VERSION "HNNBNNNYNNNNNNNNNNNNNNNNNNNNNNNNNNNNNNNNNN/4/%%%/4/'%**4NNN///"

NS_ :

BS_:

BU_: BAP_Tester BedienDisp_vo BedienSG_hi CGS DDA Gateway Gateway_PAG GurtMikrofon OTA_FC ZR_High ZR_LIMU ZR_MIB_TOP_ab_Gen3 ZR_Standard

BO_ 1178 Mem_FS_01: 8 Gateway
 SG_ FS_Fond_Bed_enable : 12|1@1+ (1.0,0.0) [0.0|1] ""  ZR_High
 SG_ FS_Lehne_nicht_verriegelt : 13|1@1+ (1.0,0.0) [0.0|1] ""  ZR_High
 SG_ FS_Spezialposition_anfahren : 14|1@1+ (1.0,0.0) [0.0|1] ""  ZR_High
 SG_ FS_Gurtbringer_Sperre : 15|1@1+ (1.0,0.0) [0.0|1] ""  ZR_High
 SG_ FS_BFS_Sitzsym_Anfahrt : 16|1@1+ (1.0,0.0) [0.0|1] ""  ZR_High
 SG_ FS_Sitzfahrt_aktiv : 17|1@1+ (1.0,0.0) [0.0|1] ""  ZR_High
 SG_ FS_SLV_aktiv : 18|1@1+ (1.0,0.0) [0.0|1] ""  ZR_High
 SG_ FS_SHV_aktiv : 19|1@1+ (1.0,0.0) [0.0|1] ""  ZR_High
 SG_ FS_LNV_aktiv : 20|1@1+ (1.0,0.0) [0.0|1] ""  ZR_High
 SG_ FS_SNV_aktiv : 21|1@1+ (1.0,0.0) [0.0|1] ""  ZR_High
 SG_ FS_KSV_aktiv : 22|1@1+ (1.0,0.0) [0.0|1] ""  ZR_High
 SG_ FS_LKV_aktiv : 23|1@1+ (1.0,0.0) [0.0|1] ""  ZR_High
 SG_ FS_STV_aktiv : 24|1@1+ (1.0,0.0) [0.0|1] ""  ZR_High
 SG_ FS_LHV_aktiv : 25|1@1+ (1.0,0.0) [0.0|1] ""  ZR_High
 SG_ FS_LWV_aktiv : 26|1@1+ (1.0,0.0) [0.0|1] ""  ZR_High
 SG_ FS_GHV_aktiv : 27|1@1+ (1.0,0.0) [0.0|1] ""  ZR_High
 SG_ FS_BFS_KSS_Anfahrt : 28|1@1+ (1.0,0.0) [0.0|1] ""  ZR_High
 SG_ FS_MMB_lokal_Stop : 29|1@1+ (1.0,0.0) [0.0|1] ""  ZR_High
 SG_ FS_NFA_einfahren : 30|1@1+ (1.0,0.0) [0.0|1] ""  Vector__XXX
 SG_ FS_Kollisionsbereich_Windschott : 31|1@1+ (1.0,0.0) [0.0|1] ""  Vector__XXX
 SG_ FS_MMB_storage : 32|4@1+ (1.0,0.0) [0.0|15] ""  ZR_High
 SG_ FS_MMB_tipp : 36|1@1+ (1.0,0.0) [0.0|1] ""  ZR_High
 SG_ FS_MMB_tast : 37|1@1+ (1.0,0.0) [0.0|1] ""  ZR_High
 SG_ FS_MMB_store_LED_on : 38|1@1+ (1.0,0.0) [0.0|1] ""  ZR_High
 SG_ FS_MMB_storage_beep : 39|1@1+ (1.0,0.0) [0.0|1] ""  Vector__XXX
 SG_ FS_MMB_store : 40|1@1+ (1.0,0.0) [0.0|1] ""  ZR_High
 SG_ FS_MMB_glob_stop : 41|1@1+ (1.0,0.0) [0.0|1] ""  ZR_High
 SG_ FS_EE_Fond_FS_enable : 42|1@1+ (1.0,0.0) [0.0|1] ""  ZR_High
 SG_ FS_EE_Fond_BFS_enable : 43|1@1+ (1.0,0.0) [0.0|1] ""  ZR_High
 SG_ FS_BFS_Fond_Verst_enable : 44|1@1+ (1.0,0.0) [0.0|1] ""  ZR_High
 SG_ FS_EE_BFS_enable : 45|1@1+ (1.0,0.0) [0.0|1] ""  ZR_High
 SG_ FS_Kollisionsgefahr_Windschott : 46|1@1+ (1.0,0.0) [0.0|1] ""  Vector__XXX

BO_ 954 Mem_FS_02: 8 Gateway
 SG_ Mem_FS_Lordose_hoch : 12|1@1+ (1.0,0.0) [0.0|1] ""  ZR_High
 SG_ Mem_FS_Lordose_runter : 13|1@1+ (1.0,0.0) [0.0|1] ""  ZR_High
 SG_ Mem_FS_Lordose_vor : 14|1@1+ (1.0,0.0) [0.0|1] ""  ZR_High
 SG_ Mem_FS_Lordose_zurueck : 15|1@1+ (1.0,0.0) [0.0|1] ""  ZR_High
 SG_ Mem_FS_Massage_Geschw : 16|3@1+ (1.0,0.0) [0.0|7] ""  ZR_High
 SG_ Mem_FS_Massage_Intensitaet : 19|3@1+ (1.0,0.0) [0.0|7] ""  ZR_High
 SG_ Mem_FS_SWangenLehne_beluef : 22|1@1+ (1.0,0.0) [0.0|1] ""  ZR_High
 SG_ Mem_FS_SWangenLehne_entlue : 23|1@1+ (1.0,0.0) [0.0|1] ""  ZR_High
 SG_ Mem_FS_Massage_Programm : 24|3@1+ (1.0,0.0) [0.0|7] ""  Vector__XXX
 SG_ Mem_FS_SWangenSitz_beluef : 27|1@1+ (1.0,0.0) [0.0|1] ""  ZR_High
 SG_ Mem_FS_SWangenSitz_entlue : 28|1@1+ (1.0,0.0) [0.0|1] ""  ZR_High
 SG_ FS_BFS_aufraeumen : 29|1@1+ (1.0,0.0) [0.0|1] ""  ZR_High
 SG_ FS_BFSFo_aufraeumen : 30|1@1+ (1.0,0.0) [0.0|1] ""  ZR_High
 SG_ FS_FSFo_aufraeumen : 31|1@1+ (1.0,0.0) [0.0|1] ""  ZR_High
 SG_ FS_Remote_Multif_Taster_hoch : 32|1@1+ (1.0,0.0) [0.0|1] ""  ZR_High
 SG_ FS_Remote_Multif_Taster_tief : 33|1@1+ (1.0,0.0) [0.0|1] ""  ZR_High
 SG_ FS_Remote_Multif_Taster_vor : 34|1@1+ (1.0,0.0) [0.0|1] ""  ZR_High
 SG_ FS_Remote_Multif_Taster_zurueck : 35|1@1+ (1.0,0.0) [0.0|1] ""  ZR_High
 SG_ FS_Remote_Programmwippe_hoch : 36|1@1+ (1.0,0.0) [0.0|1] ""  ZR_High
 SG_ FS_Remote_Programmwippe_tief : 37|1@1+ (1.0,0.0) [0.0|1] ""  ZR_High
 SG_ FS_Remote_SHV_Taste_hoch : 38|1@1+ (1.0,0.0) [0.0|1] ""  ZR_High
 SG_ FS_Remote_SHV_Taste_tief : 39|1@1+ (1.0,0.0) [0.0|1] ""  ZR_High
 SG_ FS_Remote_SLV_Taste_vor : 40|1@1+ (1.0,0.0) [0.0|1] ""  ZR_High
 SG_ FS_Remote_SLV_Taste_zurueck : 41|1@1+ (1.0,0.0) [0.0|1] ""  ZR_High
 SG_ FS_Remote_SNV_Taste_hoch : 42|1@1+ (1.0,0.0) [0.0|1] ""  ZR_High
 SG_ FS_Remote_SNV_Taste_tief : 43|1@1+ (1.0,0.0) [0.0|1] ""  ZR_High
 SG_ FS_Remote_KSV_Taste_hoch : 44|1@1+ (1.0,0.0) [0.0|1] ""  ZR_High
 SG_ FS_Remote_KSV_Taste_tief : 45|1@1+ (1.0,0.0) [0.0|1] ""  ZR_High
 SG_ FS_Remote_LNV_Taste_vor : 46|1@1+ (1.0,0.0) [0.0|1] ""  ZR_High
 SG_ FS_Remote_LNV_Taste_zurueck : 47|1@1+ (1.0,0.0) [0.0|1] ""  ZR_High
 SG_ FS_Remote_Massage_Taste : 48|1@1+ (1.0,0.0) [0.0|1] ""  ZR_High
 SG_ FS_RemoteTarget : 49|2@1+ (1.0,0.0) [0.0|3] ""  ZR_High
 SG_ FS_Remote_KSV_Taste_vor : 51|1@1+ (1.0,0.0) [0.0|1] ""  ZR_High
 SG_ FS_Remote_KSV_Taste_zurueck : 52|1@1+ (1.0,0.0) [0.0|1] ""  ZR_High
 SG_ FS_Remote_STV_Taste_vor : 53|1@1+ (1.0,0.0) [0.0|1] ""  ZR_High
 SG_ FS_Remote_STV_Taste_zurueck : 54|1@1+ (1.0,0.0) [0.0|1] ""  ZR_High
 SG_ FS_Remote_SWV_Taste_eng : 55|1@1+ (1.0,0.0) [0.0|1] ""  ZR_High
 SG_ FS_Remote_SWV_Taste_breit : 56|1@1+ (1.0,0.0) [0.0|1] ""  ZR_High
 SG_ FS_Remote_LWV_Taste_eng : 57|1@1+ (1.0,0.0) [0.0|1] ""  ZR_High
 SG_ FS_Remote_LWV_Taste_breit : 58|1@1+ (1.0,0.0) [0.0|1] ""  ZR_High
 SG_ FS_Remote_LKV_Taste_vor : 59|1@1+ (1.0,0.0) [0.0|1] ""  ZR_High
 SG_ FS_Remote_LKV_Taste_zurueck : 60|1@1+ (1.0,0.0) [0.0|1] ""  ZR_High
 SG_ FS_MMB_Sys_Fahrt_aktiv : 61|1@1+ (1.0,0.0) [0.0|1] ""  ZR_High

BO_ 956 Mem_FS_Fond_01: 8 Gateway
 SG_ Mem_FSFo_Lordose_hoch : 12|1@1+ (1.0,0.0) [0.0|1] ""  ZR_High
 SG_ Mem_FSFo_Lordose_runter : 13|1@1+ (1.0,0.0) [0.0|1] ""  ZR_High
 SG_ Mem_FSFo_Lordose_vor : 14|1@1+ (1.0,0.0) [0.0|1] ""  ZR_High
 SG_ Mem_FSFo_Lordose_zurueck : 15|1@1+ (1.0,0.0) [0.0|1] ""  ZR_High
 SG_ Mem_FSFo_Massage_Geschw : 16|3@1+ (1.0,0.0) [0.0|7] ""  ZR_High
 SG_ Mem_FSFo_Massage_Intens : 19|3@1+ (1.0,0.0) [0.0|7] ""  ZR_High
 SG_ Mem_FSFo_MMB_storage : 22|2@1+ (1.0,0.0) [0.0|3] ""  ZR_High
 SG_ Mem_FSFo_Massage_Prg : 24|3@1+ (1.0,0.0) [0.0|7] ""  ZR_High
 SG_ Mem_FSFo_MMB_tast : 27|1@1+ (1.0,0.0) [0.0|1] ""  ZR_High
 SG_ Mem_FSFo_MMB_tipp : 28|1@1+ (1.0,0.0) [0.0|1] ""  ZR_High
 SG_ Mem_FSFo_MMB_glob_Stop : 29|1@1+ (1.0,0.0) [0.0|1] ""  ZR_High
 SG_ Mem_FSFo_Sitztiefe_vor : 30|1@1+ (1.0,0.0) [0.0|1] ""  ZR_High
 SG_ Mem_FSFo_Sitztiefe_zur : 31|1@1+ (1.0,0.0) [0.0|1] ""  ZR_High
 SG_ Mem_FSFo_MMB_store : 32|1@1+ (1.0,0.0) [0.0|1] ""  ZR_High
 SG_ Mem_FSFo_MMB_storage_beep : 33|1@1+ (1.0,0.0) [0.0|1] ""  ZR_High
 SG_ Mem_FSFo_MMB_store_LED_on : 34|1@1+ (1.0,0.0) [0.0|1] ""  ZR_High
 SG_ Mem_FSFo_MMB_lokal_Stop : 36|1@1+ (1.0,0.0) [0.0|1] ""  ZR_High
 SG_ Mem_FSFo_Sitzfahrt_aktiv : 37|1@1+ (1.0,0.0) [0.0|1] ""  ZR_High
 SG_ Mem_FSFo_Business_anfahren : 42|1@1+ (1.0,0.0) [0.0|1] ""  ZR_High
 SG_ Mem_FSFo_Relax_anfahren : 43|1@1+ (1.0,0.0) [0.0|1] ""  ZR_High

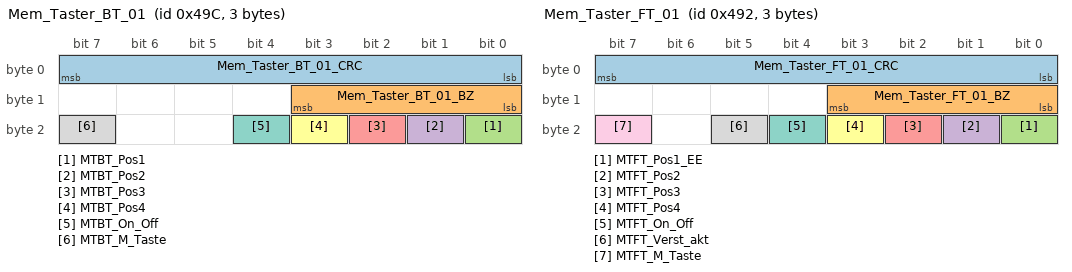
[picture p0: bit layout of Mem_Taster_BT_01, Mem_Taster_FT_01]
BO_ 1180 Mem_Taster_BT_01: 3 Gateway
 SG_ Mem_Taster_BT_01_CRC : 0|8@1+ (1,0) [0|255] ""  Vector__XXX
 SG_ Mem_Taster_BT_01_BZ : 8|4@1+ (1,0) [0|15] ""  Vector__XXX
 SG_ MTBT_Pos1 : 16|1@1+ (1.0,0.0) [0.0|1] ""  ZR_High
 SG_ MTBT_Pos2 : 17|1@1+ (1.0,0.0) [0.0|1] ""  ZR_High
 SG_ MTBT_Pos3 : 18|1@1+ (1.0,0.0) [0.0|1] ""  ZR_High
 SG_ MTBT_Pos4 : 19|1@1+ (1.0,0.0) [0.0|1] ""  ZR_High
 SG_ MTBT_On_Off : 20|1@1+ (1.0,0.0) [0.0|1] ""  ZR_High
 SG_ MTBT_M_Taste : 23|1@1+ (1.0,0.0) [0.0|1] ""  ZR_High

BO_ 1170 Mem_Taster_FT_01: 3 Gateway
 SG_ Mem_Taster_FT_01_CRC : 0|8@1+ (1,0) [0|255] ""  Vector__XXX
 SG_ Mem_Taster_FT_01_BZ : 8|4@1+ (1,0) [0|15] ""  Vector__XXX
 SG_ MTFT_Pos1_EE : 16|1@1+ (1.0,0.0) [0.0|1] ""  ZR_High
 SG_ MTFT_Pos2 : 17|1@1+ (1.0,0.0) [0.0|1] ""  ZR_High
 SG_ MTFT_Pos3 : 18|1@1+ (1.0,0.0) [0.0|1] ""  ZR_High
 SG_ MTFT_Pos4 : 19|1@1+ (1.0,0.0) [0.0|1] ""  ZR_High
 SG_ MTFT_On_Off : 20|1@1+ (1.0,0.0) [0.0|1] ""  ZR_High
 SG_ MTFT_Verst_akt : 21|1@1+ (1.0,0.0) [0.0|1] ""  ZR_High
 SG_ MTFT_M_Taste : 23|1@1+ (1.0,0.0) [0.0|1] ""  ZR_High

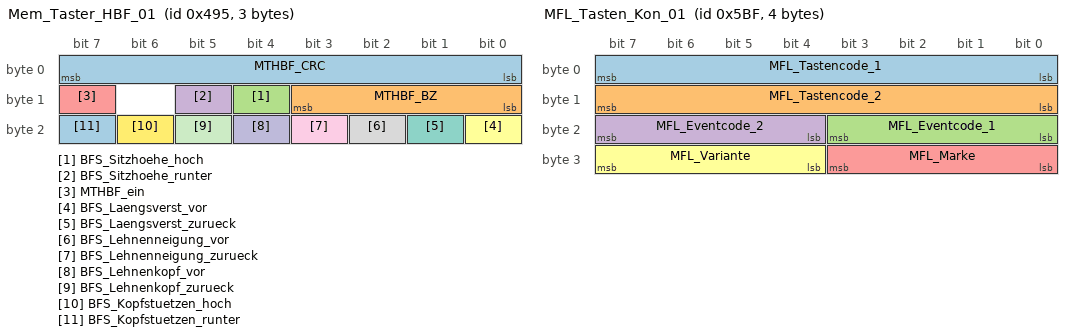
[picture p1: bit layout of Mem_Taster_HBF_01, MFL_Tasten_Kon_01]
BO_ 1173 Mem_Taster_HBF_01: 3 Gateway
 SG_ MTHBF_CRC : 0|8@1+ (1,0) [0|255] ""  Vector__XXX
 SG_ MTHBF_BZ : 8|4@1+ (1,0) [0|15] ""  Vector__XXX
 SG_ BFS_Sitzhoehe_hoch : 12|1@1+ (1.0,0.0) [0.0|1] ""  ZR_High
 SG_ BFS_Sitzhoehe_runter : 13|1@1+ (1.0,0.0) [0.0|1] ""  ZR_High
 SG_ MTHBF_ein : 15|1@1+ (1.0,0.0) [0.0|1] ""  ZR_High
 SG_ BFS_Laengsverst_vor : 16|1@1+ (1.0,0.0) [0.0|1] ""  ZR_High
 SG_ BFS_Laengsverst_zurueck : 17|1@1+ (1.0,0.0) [0.0|1] ""  ZR_High
 SG_ BFS_Lehnenneigung_vor : 18|1@1+ (1.0,0.0) [0.0|1] ""  ZR_High
 SG_ BFS_Lehnenneigung_zurueck : 19|1@1+ (1.0,0.0) [0.0|1] ""  ZR_High
 SG_ BFS_Lehnenkopf_vor : 20|1@1+ (1.0,0.0) [0.0|1] ""  ZR_High
 SG_ BFS_Lehnenkopf_zurueck : 21|1@1+ (1.0,0.0) [0.0|1] ""  ZR_High
 SG_ BFS_Kopfstuetzen_hoch : 22|1@1+ (1.0,0.0) [0.0|1] ""  ZR_High
 SG_ BFS_Kopfstuetzen_runter : 23|1@1+ (1.0,0.0) [0.0|1] ""  ZR_High

BO_ 817 MFL_01: 8 Gateway
 SG_ MFL_Zaehler : 0|4@1+ (1,0) [0|15] ""  Vector__XXX
 SG_ MFL_Toggle : 4|1@1+ (1,0) [0|1] ""  Vector__XXX
 SG_ MFL_Lokalaktiv : 5|1@1+ (1.0,0.0) [0.0|1] ""  Vector__XXX
 SG_ MFL_M_Taste : 6|1@1+ (1.0,0.0) [0.0|1] ""  ZR_High
 SG_ MFL_Paddle_Verbau : 7|1@1+ (1.0,0.0) [0.0|1] ""  ZR_High
 SG_ MFL_Tastencode_1 : 8|8@1+ (1.0,0.0) [0.0|255] ""  Vector__XXX
 SG_ MFL_Tastencode_2 : 16|8@1+ (1.0,0.0) [0.0|255] ""  Vector__XXX
 SG_ MFL_Eventcode_1 : 24|4@1+ (1.0,0.0) [0.0|15] ""  Vector__XXX
 SG_ MFL_Eventcode_2 : 28|4@1+ (1.0,0.0) [0.0|15] ""  Vector__XXX
 SG_ MFL_Marke : 32|4@1+ (1.0,0.0) [0.0|15] ""  Vector__XXX
 SG_ MFL_Variante : 36|4@1+ (1,0) [0|15] ""  Vector__XXX
 SG_ MFL_Dummy_0_Signal_1 : 40|8@1+ (1.0,0.0) [0.0|255] ""  Vector__XXX
 SG_ MFL_Tip_Down : 48|1@1+ (1.0,0.0) [0.0|1] ""  ZR_High
 SG_ MFL_Tip_Up : 49|1@1+ (1.0,0.0) [0.0|1] ""  ZR_High
 SG_ MFL_SatModul_links_Err : 50|1@1+ (1.0,0.0) [0.0|1] ""  ZR_High
 SG_ MFL_SatModul_rechts_Err : 51|1@1+ (1.0,0.0) [0.0|1] ""  ZR_High
 SG_ MFL_Dummy_0_Signal_2 : 52|1@1+ (1.0,0.0) [0.0|1] ""  Vector__XXX
 SG_ MFL_Dummy_0_Signal_3 : 53|1@1+ (1.0,0.0) [0.0|1] ""  Vector__XXX
 SG_ MFL_LR_HZG_Status : 54|1@1+ (1.0,0.0) [0.0|1] ""  ZR_High
 SG_ MFL_LR_HZG_Err : 55|1@1+ (1.0,0.0) [0.0|1] ""  ZR_High
 SG_ MFL_Signalhorn : 56|1@1+ (1.0,0.0) [0.0|1] ""  OTA_FC,ZR_High
 SG_ MFL_Signalhorn_Err : 57|1@1+ (1.0,0.0) [0.0|1] ""  ZR_High
 SG_ MFL_Tip_links_Err : 58|1@1+ (1.0,0.0) [0.0|1] ""  ZR_High
 SG_ MFL_Tip_rechts_Err : 59|1@1+ (1.0,0.0) [0.0|1] ""  ZR_High
 SG_ MFL_Taste_links_Err : 60|1@1+ (1.0,0.0) [0.0|1] ""  ZR_High
 SG_ MFL_Taste_rechts_Err : 61|1@1+ (1.0,0.0) [0.0|1] ""  ZR_High
 SG_ MFL_ECU_Err : 62|1@1+ (1.0,0.0) [0.0|1] ""  ZR_High
 SG_ MFL_Response_Err : 63|1@1+ (1.0,0.0) [0.0|1] ""  Vector__XXX

BO_ 1471 MFL_Tasten_Kon_01: 4 Gateway
 SG_ MFL_Tastencode_1 : 0|8@1+ (1.0,0.0) [0.0|255] ""  OTA_FC,ZR_High,ZR_LIMU,ZR_MIB_TOP_ab_Gen3,ZR_Standard
 SG_ MFL_Tastencode_2 : 8|8@1+ (1.0,0.0) [0.0|255] ""  OTA_FC,ZR_High,ZR_LIMU,ZR_MIB_TOP_ab_Gen3,ZR_Standard
 SG_ MFL_Eventcode_1 : 16|4@1+ (1.0,0.0) [0.0|15] ""  ZR_High,ZR_LIMU,ZR_MIB_TOP_ab_Gen3,ZR_Standard
 SG_ MFL_Eventcode_2 : 20|4@1+ (1.0,0.0) [0.0|15] ""  ZR_High,ZR_LIMU,ZR_MIB_TOP_ab_Gen3,ZR_Standard
 SG_ MFL_Marke : 24|4@1+ (1.0,0.0) [0.0|15] ""  ZR_High,ZR_LIMU,ZR_MIB_TOP_ab_Gen3,ZR_Standard
 SG_ MFL_Variante : 28|4@1+ (1,0) [0|15] ""  ZR_High,ZR_LIMU,ZR_MIB_TOP_ab_Gen3,ZR_Standard

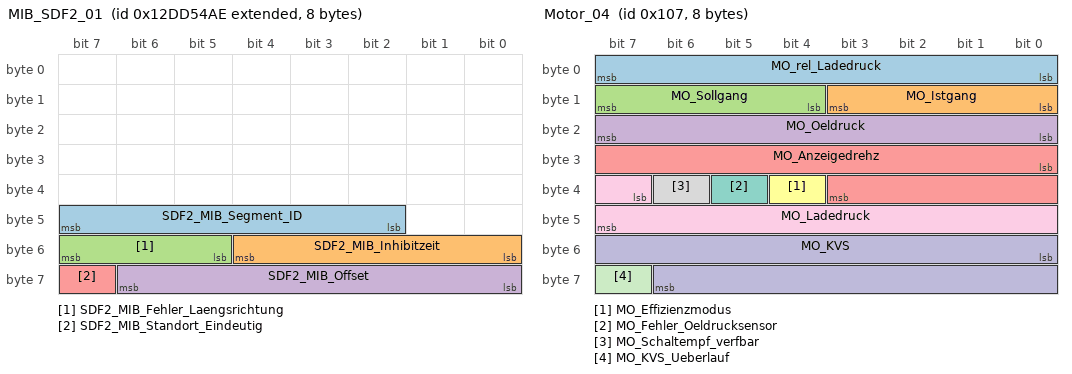
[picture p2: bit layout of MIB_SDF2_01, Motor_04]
BO_ 2463978670 MIB_SDF2_01: 8 ZR_High
 SG_ SDF2_MIB_Segment_ID : 42|6@1+ (1,0) [2|63] ""  Gateway,Gateway_PAG
 SG_ SDF2_MIB_Inhibitzeit : 48|5@1+ (10,0) [0|310] "Unit_MilliSecon"  Gateway,Gateway_PAG
 SG_ SDF2_MIB_Fehler_Laengsrichtung : 53|3@1+ (1.0,0.0) [0.0|7] ""  Gateway,Gateway_PAG
 SG_ SDF2_MIB_Offset : 56|7@1+ (2,0) [0|254] "Unit_Meter"  Gateway,Gateway_PAG
 SG_ SDF2_MIB_Standort_Eindeutig : 63|1@1+ (1.0,0.0) [0.0|1] ""  Gateway,Gateway_PAG

BO_ 263 Motor_04: 8 Gateway
 SG_ MO_rel_Ladedruck : 0|8@1+ (0.4,0) [0.0|100.0] "Unit_PerCent"  ZR_High,ZR_LIMU,ZR_MIB_TOP_ab_Gen3,ZR_Standard
 SG_ MO_Istgang : 8|4@1+ (1.0,0.0) [0.0|15] ""  ZR_High,ZR_LIMU,ZR_MIB_TOP_ab_Gen3,ZR_Standard
 SG_ MO_Sollgang : 12|4@1+ (1.0,0.0) [0.0|15] ""  ZR_High,ZR_LIMU,ZR_MIB_TOP_ab_Gen3,ZR_Standard
 SG_ MO_Oeldruck : 16|8@1+ (0.04,0) [0.00|10.00] "Unit_Bar"  Vector__XXX
 SG_ MO_Anzeigedrehz : 24|12@1+ (3,0) [0|12282] "Unit_MinutInver"  ZR_High,ZR_LIMU,ZR_MIB_TOP_ab_Gen3,ZR_Standard
 SG_ MO_Effizienzmodus : 36|1@1+ (1.0,0.0) [0.0|1] ""  Vector__XXX
 SG_ MO_Fehler_Oeldrucksensor : 37|1@1+ (1.0,0.0) [0.0|1] ""  Vector__XXX
 SG_ MO_Schaltempf_verfbar : 38|1@1+ (1.0,0.0) [0.0|1] ""  ZR_High,ZR_LIMU,ZR_MIB_TOP_ab_Gen3,ZR_Standard
 SG_ MO_Ladedruck : 39|9@1+ (0.01,0) [0.00|5.10] "Unit_Bar"  Vector__XXX
 SG_ MO_KVS : 48|15@1+ (1,0) [0|32767] "Unit_MicroLiter"  OTA_FC
 SG_ MO_KVS_Ueberlauf : 63|1@1+ (1.0,0.0) [0.0|1] ""  Vector__XXX

BO_ 1600 Motor_07: 8 Gateway
 SG_ MO_QBit_Ansaugluft_Temp : 0|1@1+ (1.0,0.0) [0.0|1] ""  Vector__XXX
 SG_ MO_QBit_Oel_Temp : 1|1@1+ (1.0,0.0) [0.0|1] ""  BedienSG_hi
 SG_ MO_QBit_Kuehlmittel_Temp : 2|1@1+ (1.0,0.0) [0.0|1] ""  BedienSG_hi
 SG_ MO_KL15_Abschaltempfehlung : 3|1@1+ (1.0,0.0) [0.0|1] ""  Vector__XXX
 SG_ MO_HYB_Fehler_HV_Netz : 4|1@1+ (1.0,0.0) [0.0|1] ""  Vector__XXX
 SG_ MO_aktives_Getriebeheizen : 5|1@1+ (1.0,0.0) [0.0|1] ""  Vector__XXX
 SG_ MO_Absperrventil_oeffnen : 6|2@1+ (1.0,0.0) [0.0|3] ""  Vector__XXX
 SG_ MO_Ansaugluft_Temp : 8|8@1+ (0.75,-48) [-48.00|141.75] "Unit_DegreCelsi"  OTA_FC
 SG_ MO_Oel_Temp : 16|8@1+ (1,-60) [-60|192] "Unit_DegreCelsi"  BedienSG_hi,OTA_FC,ZR_High
 SG_ MO_Kuehlmittel_Temp : 24|8@1+ (0.75,-48) [-48.00|141.75] "Unit_DegreCelsi"  BedienSG_hi,OTA_FC,ZR_High
 SG_ MO_Hoeheninfo : 32|8@1+ (0.00781,0) [0.00000|1.98374] ""  OTA_FC,ZR_High
 SG_ MO_Kennfeldk : 40|1@1+ (1.0,0.0) [0.0|1] ""  Vector__XXX
 SG_ MO_Versionsinfo_02 : 41|5@1+ (1.0,0.0) [0.0|31] ""  Vector__XXX
 SG_ MO_QBit_Hoeheninfo : 46|1@1+ (1.0,0.0) [0.0|1] ""  ZR_High
 SG_ MO_Getriebe_kuehlen : 47|1@1+ (1.0,0.0) [0.0|1] ""  OTA_FC
 SG_ MO_Mom_Traegheit_02 : 48|5@1+ (0.01,0) [0.00|0.31] "Unit_KiloGramMeterSquar"  Vector__XXX
 SG_ MO_Heizungspumpenansteuerung : 53|4@1+ (10,0) [0|100] "Unit_PerCent"  Vector__XXX
 SG_ MO_SpannungsAnf : 57|1@1+ (1.0,0.0) [0.0|1] ""  Vector__XXX
 SG_ MO_Nachlaufzeit_Heizungspumpe : 58|6@1+ (15,0) [0|945] "Unit_Secon"  Vector__XXX

BO_ 1607 Motor_09: 8 Gateway
 SG_ MO_ITM_Kuehlmittel_Temp : 0|8@1+ (0.75,-48) [-45.75|143.25] "Unit_DegreCelsi"  OTA_FC,ZR_High
 SG_ MO_E85_Sensor : 8|4@1+ (10,0) [0|100] "Unit_PerCent"  Vector__XXX
 SG_ SCR_Anz_Motorstarts : 12|4@1+ (1.0,0.0) [0.0|15] ""  Vector__XXX
 SG_ SCR_Reichweite : 16|15@1+ (1,0) [0|32766] "Unit_KiloMeter"  ZR_High
 SG_ MO_Ethanol_Spuelhinweis : 31|1@1+ (1.0,0.0) [0.0|1] ""  Vector__XXX
 SG_ SCR_Warnstufe_1 : 32|1@1+ (1.0,0.0) [0.0|1] ""  ZR_High
 SG_ SCR_Warnstufe_2 : 33|1@1+ (1.0,0.0) [0.0|1] ""  ZR_High
 SG_ SCR_Text : 34|3@1+ (1.0,0.0) [0.0|7] ""  Vector__XXX
 SG_ SCR_Akustik : 37|2@1+ (1.0,0.0) [0.0|3] ""  Vector__XXX
 SG_ SCR_verbaut : 39|1@1+ (1.0,0.0) [0.0|1] ""  ZR_High
 SG_ MO_Kraftstofffilter_Wasser : 40|1@1+ (1.0,0.0) [0.0|1] ""  ZR_High
 SG_ SCR_Systemfehler : 41|1@1+ (1.0,0.0) [0.0|1] ""  ZR_High
 SG_ SCR_Inducement_Strategie : 42|2@1+ (1.0,0.0) [0.0|3] ""  Vector__XXX
 SG_ MO_CO2_Faktor : 44|12@1+ (1,0) [1|4094] "Unit_GramPerLiter"  Vector__XXX
 SG_ MO_MKB_MUX M  : 56|2@1+ (1.0,0.0) [0.0|3] ""  ZR_High
 SG_ MO_MKB_01 m0  : 59|5@1+ (1.0,0.0) [0.0|31] ""  ZR_High
 SG_ MO_MKB_02 m1  : 59|5@1+ (1.0,0.0) [0.0|31] ""  ZR_High
 SG_ MO_MKB_03 m2  : 59|5@1+ (1.0,0.0) [0.0|31] ""  ZR_High
 SG_ MO_MKB_04 m3  : 59|5@1+ (1.0,0.0) [0.0|31] ""  ZR_High

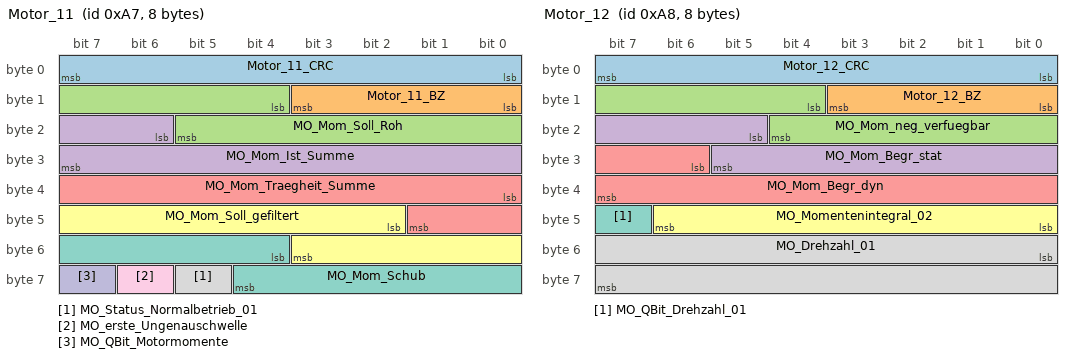
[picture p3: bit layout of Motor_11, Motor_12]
BO_ 167 Motor_11: 8 Gateway
 SG_ Motor_11_CRC : 0|8@1+ (1,0) [0|255] ""  Vector__XXX
 SG_ Motor_11_BZ : 8|4@1+ (1,0) [0|15] ""  Vector__XXX
 SG_ MO_Mom_Soll_Roh : 12|10@1+ (1,-509) [-509|509] ""  Vector__XXX
 SG_ MO_Mom_Ist_Summe : 22|10@1+ (1,-509) [-509|509] ""  OTA_FC,ZR_High,ZR_Standard
 SG_ MO_Mom_Traegheit_Summe : 32|10@1+ (1,-509) [-509|509] ""  Vector__XXX
 SG_ MO_Mom_Soll_gefiltert : 42|10@1+ (1,-509) [-509|509] ""  OTA_FC
 SG_ MO_Mom_Schub : 52|9@1+ (1,-509) [-509|0] ""  Vector__XXX
 SG_ MO_Status_Normalbetrieb_01 : 61|1@1+ (1.0,0.0) [0.0|1] ""  Vector__XXX
 SG_ MO_erste_Ungenauschwelle : 62|1@1+ (1.0,0.0) [0.0|1] ""  Vector__XXX
 SG_ MO_QBit_Motormomente : 63|1@1+ (1.0,0.0) [0.0|1] ""  Vector__XXX

BO_ 168 Motor_12: 8 Gateway
 SG_ Motor_12_CRC : 0|8@1+ (1,0) [0|255] ""  Vector__XXX
 SG_ Motor_12_BZ : 8|4@1+ (1,0) [0|15] ""  Vector__XXX
 SG_ MO_Mom_neg_verfuegbar : 12|9@1+ (1,-509) [-509|0] ""  Vector__XXX
 SG_ MO_Mom_Begr_stat : 21|9@1+ (1,0) [0|509] ""  Vector__XXX
 SG_ MO_Mom_Begr_dyn : 30|10@1+ (1,-509) [-509|509] ""  OTA_FC
 SG_ MO_Momentenintegral_02 : 40|7@1+ (1,0) [0|100] "Unit_PerCent"  Vector__XXX
 SG_ MO_QBit_Drehzahl_01 : 47|1@1+ (1.0,0.0) [0.0|1] ""  ZR_High,ZR_LIMU,ZR_MIB_TOP_ab_Gen3,ZR_Standard
 SG_ MO_Drehzahl_01 : 48|16@1+ (0.25,0) [0.00|16383.00] "Unit_MinutInver"  BedienSG_hi,OTA_FC,ZR_High,ZR_LIMU,ZR_MIB_TOP_ab_Gen3,ZR_Standard

BO_ 958 Motor_14: 8 Gateway
 SG_ Motor_14_CRC : 0|8@1+ (1,0) [0|255] ""  Vector__XXX
 SG_ Motor_14_BZ : 8|4@1+ (1,0) [0|15] ""  Vector__XXX
 SG_ MO_StartStopp_Status : 12|2@1+ (1.0,0.0) [0.0|3] ""  BedienSG_hi
 SG_ MO_StartStopp_Wiederstart : 14|1@1+ (1.0,0.0) [0.0|1] ""  OTA_FC,ZR_High,ZR_LIMU,ZR_MIB_TOP_ab_Gen3,ZR_Standard
 SG_ MO_StartStopp_Motorstopp : 15|1@1+ (1.0,0.0) [0.0|1] ""  BedienSG_hi,ZR_High
 SG_ MO_Freig_Reku : 16|2@1+ (1.0,0.0) [0.0|3] ""  Vector__XXX
 SG_ MO_Kl_75 : 18|1@1+ (1.0,0.0) [0.0|1] ""  ZR_High,ZR_LIMU,ZR_MIB_TOP_ab_Gen3,ZR_Standard
 SG_ MO_Kl_50 : 19|1@1+ (1.0,0.0) [0.0|1] ""  ZR_High,ZR_LIMU,ZR_MIB_TOP_ab_Gen3,ZR_Standard
 SG_ MO_Gangposition : 20|4@1+ (1.0,0.0) [0.0|15] ""  OTA_FC,ZR_High
 SG_ MO_StartStopp_Fahrerwunsch : 24|2@1+ (1.0,0.0) [0.0|3] ""  ZR_High
 SG_ MO_HYB_Fahrbereitschaft : 26|1@1+ (1.0,0.0) [0.0|1] ""  Vector__XXX
 SG_ MO_Ext_E_Fahrt_aktiv : 27|1@1+ (1.0,0.0) [0.0|1] ""  OTA_FC,ZR_High
 SG_ MO_Fahrer_bremst : 28|1@1+ (1.0,0.0) [0.0|1] ""  ZR_High,ZR_LIMU,ZR_MIB_TOP_ab_Gen3,ZR_Standard
 SG_ MO_QBit_Fahrer_bremst : 29|1@1+ (1.0,0.0) [0.0|1] ""  ZR_High,ZR_LIMU,ZR_MIB_TOP_ab_Gen3,ZR_Standard
 SG_ MO_BLS : 30|1@1+ (1.0,0.0) [0.0|1] ""  ZR_High
 SG_ MO_Konsistenz_Bremsped : 31|1@1+ (1.0,0.0) [0.0|1] ""  Vector__XXX
 SG_ MO_KomFehler_ESP : 32|1@1+ (1.0,0.0) [0.0|1] ""  Vector__XXX
 SG_ MO_Klima_Eingr : 33|2@1+ (1.0,0.0) [0.0|3] ""  Vector__XXX
 SG_ MO_Aussp_Anlass : 35|1@1+ (1.0,0.0) [0.0|1] ""  Vector__XXX
 SG_ MO_Freig_Anlass : 36|1@1+ (1.0,0.0) [0.0|1] ""  Vector__XXX
 SG_ MO_Kuppl_schalter : 37|1@1+ (1.0,0.0) [0.0|1] ""  ZR_High,ZR_LIMU,ZR_MIB_TOP_ab_Gen3,ZR_Standard
 SG_ MO_Interlock : 38|1@1+ (1.0,0.0) [0.0|1] ""  Vector__XXX
 SG_ MO_Motor_laeuft : 39|1@1+ (1.0,0.0) [0.0|1] ""  DDA
 SG_ MO_Kickdown : 40|1@1+ (1.0,0.0) [0.0|1] ""  OTA_FC,ZR_High,ZR_LIMU,ZR_MIB_TOP_ab_Gen3,ZR_Standard
 SG_ MO_QBit_KL_75 : 41|1@1+ (1.0,0.0) [0.0|1] ""  ZR_High
 SG_ MO_EKlKomLeiRed : 42|2@1+ (1.0,0.0) [0.0|3] ""  Vector__XXX
 SG_ MO_Handshake_STH : 44|1@1+ (1.0,0.0) [0.0|1] ""  Vector__XXX
 SG_ MO_BKV_Unterdruckwarnung : 45|1@1+ (1.0,0.0) [0.0|1] ""  Vector__XXX
 SG_ MO_Freigabe_Segeln : 46|1@1+ (1.0,0.0) [0.0|1] ""  Vector__XXX
 SG_ MO_PTC_Status : 47|3@1+ (1.0,0.0) [0.0|7] ""  Vector__XXX
 SG_ MO_QBit_Gangposition : 50|1@1+ (1.0,0.0) [0.0|1] ""  Vector__XXX
 SG_ MO_Signalquelle_Gangposition : 51|1@1+ (1.0,0.0) [0.0|1] ""  Vector__XXX
 SG_ MO_Remotestart_Betrieb : 52|1@1+ (1.0,0.0) [0.0|1] ""  DDA
 SG_ MO_Remotestart_moeglich : 53|1@1+ (1.0,0.0) [0.0|1] ""  Vector__XXX
 SG_ MO_FMAus_aktiv : 55|1@1+ (1.0,0.0) [0.0|1] ""  Vector__XXX
 SG_ MO_FMAus_Startvariante : 56|2@1+ (1.0,0.0) [0.0|3] ""  Vector__XXX
 SG_ MO_BMS_NV_Anf_stuetzen : 58|1@1+ (1.0,0.0) [0.0|1] ""  Vector__XXX
 SG_ MO_Zylinderabschaltung : 59|2@1+ (1.0,0.0) [0.0|3] ""  ZR_High
 SG_ MO_HYB_VM_aktiv : 61|1@1+ (1.0,0.0) [0.0|1] ""  Vector__XXX
 SG_ MO_StartVorauss_erfuellt : 62|2@1+ (1.0,0.0) [0.0|3] ""  Vector__XXX

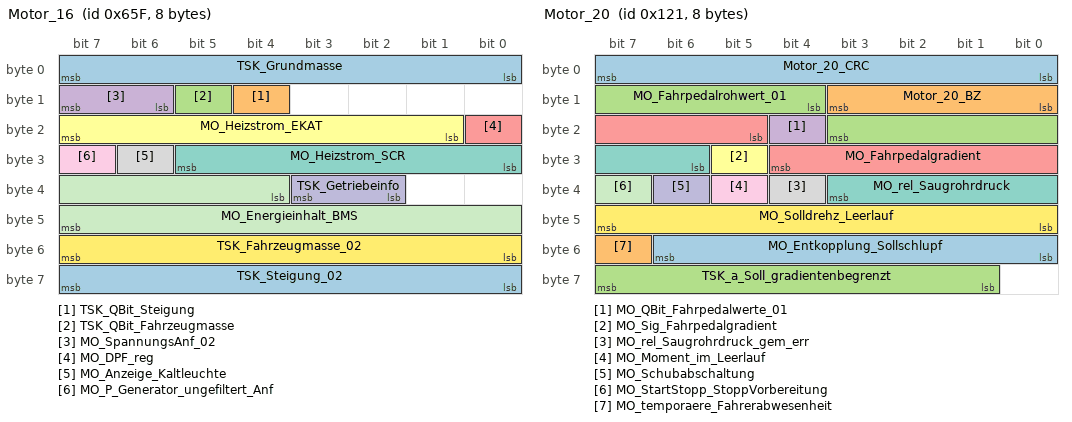
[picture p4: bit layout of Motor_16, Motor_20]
BO_ 1631 Motor_16: 8 Gateway
 SG_ TSK_Grundmasse : 0|8@1+ (32,0) [0|8128] "Unit_KiloGram"  ZR_High
 SG_ TSK_QBit_Steigung : 12|1@1+ (1.0,0.0) [0.0|1] ""  Vector__XXX
 SG_ TSK_QBit_Fahrzeugmasse : 13|1@1+ (1.0,0.0) [0.0|1] ""  ZR_High
 SG_ MO_SpannungsAnf_02 : 14|2@1+ (1.0,0.0) [0.0|3] ""  Vector__XXX
 SG_ MO_DPF_reg : 16|1@1+ (1.0,0.0) [0.0|1] ""  ZR_High
 SG_ MO_Heizstrom_EKAT : 17|7@1+ (1,0) [0|126] "Unit_Amper"  Vector__XXX
 SG_ MO_Heizstrom_SCR : 24|6@1+ (1,0) [0|62] "Unit_Amper"  Vector__XXX
 SG_ MO_Anzeige_Kaltleuchte : 30|1@1+ (1.0,0.0) [0.0|1] ""  Vector__XXX
 SG_ MO_P_Generator_ungefiltert_Anf : 31|1@1+ (1.0,0.0) [0.0|1] ""  Vector__XXX
 SG_ TSK_Getriebeinfo : 34|2@1+ (1.0,0.0) [0.0|3] ""  Vector__XXX
 SG_ MO_Energieinhalt_BMS : 36|12@1+ (25,0) [0|102325] "Unit_WattHour"  Vector__XXX
 SG_ TSK_Fahrzeugmasse_02 : 48|8@1+ (32,0) [0|8128] "Unit_KiloGram"  OTA_FC,ZR_High
 SG_ TSK_Steigung_02 : 56|8@1+ (0.8,-101.6) [-100.8|101.6] "Unit_PerCent"  OTA_FC

BO_ 1648 Motor_18: 8 Gateway
 SG_ MO_max_Ladedruck : 0|6@1+ (0.1,0) [0.0|6.3] "Unit_Bar"  ZR_High,ZR_LIMU,ZR_MIB_TOP_ab_Gen3,ZR_Standard
 SG_ MO_ANC_Kennfeld_Anf : 6|2@1+ (1.0,0.0) [0.0|3] ""  ZR_High,ZR_LIMU,ZR_MIB_TOP_ab_Gen3,ZR_Standard
 SG_ MO_Bremslicht_Reku : 8|1@1+ (1.0,0.0) [0.0|1] ""  Vector__XXX
 SG_ MO_StartStopp_PopUp : 9|2@1+ (1.0,0.0) [0.0|3] ""  Vector__XXX
 SG_ MO1_Sperr_Info_WFS : 11|1@1+ (1.0,0.0) [0.0|1] ""  Vector__XXX
 SG_ MO1_Freigabe_Info_WFS : 12|1@1+ (1.0,0.0) [0.0|1] ""  Vector__XXX
 SG_ MO_EPCL : 13|3@1+ (1.0,0.0) [0.0|7] ""  Vector__XXX
 SG_ MO_Zylabsch_Texte_02 : 16|4@1+ (1.0,0.0) [0.0|15] ""  Vector__XXX
 SG_ MO_Fahrzeugtyp : 20|3@1+ (1.0,0.0) [0.0|7] ""  Vector__XXX
 SG_ MO_NMAX_Schaltanzeige : 23|9@1+ (25,0) [0|12775] "Unit_MinutInver"  Vector__XXX
 SG_ MO_Abstellzeit : 32|8@1+ (8,0) [0|2024] "Unit_Minut"  Vector__XXX
 SG_ MO_Abstellzeit_Status : 40|2@1+ (1.0,0.0) [0.0|3] ""  Vector__XXX
 SG_ MO1_Freigabe_Verfallsinfo_WFS : 42|1@1+ (1.0,0.0) [0.0|1] ""  Vector__XXX
 SG_ MO_Hybrid_StartStopp_LED : 43|2@1+ (1.0,0.0) [0.0|3] ""  Vector__XXX
 SG_ MO_Fehler_Zylabsch : 45|2@1+ (1.0,0.0) [0.0|3] ""  ZR_High,ZR_LIMU,ZR_MIB_TOP_ab_Gen3,ZR_Standard
 SG_ MO_Anzahl_Abgesch_Zyl : 47|3@1+ (1.0,0.0) [0.0|7] ""  Vector__XXX
 SG_ MO_Zylabsch_Texte : 50|2@1+ (1.0,0.0) [0.0|3] ""  Vector__XXX
 SG_ MO_Ethanol_BS_Texte : 52|3@1+ (1.0,0.0) [0.0|7] ""  Vector__XXX
 SG_ MO_Drehzahl_Warnung : 55|1@1+ (1.0,0.0) [0.0|1] ""  Vector__XXX
 SG_ MO_obere_Drehzahlgrenze : 56|8@1+ (50,0) [50|12750] "Unit_MinutInver"  Vector__XXX

BO_ 289 Motor_20: 8 Gateway
 SG_ Motor_20_CRC : 0|8@1+ (1,0) [0|255] ""  Vector__XXX
 SG_ Motor_20_BZ : 8|4@1+ (1,0) [0|15] ""  Vector__XXX
 SG_ MO_Fahrpedalrohwert_01 : 12|8@1+ (0.4,0) [0.0|101.6] "Unit_PerCent"  OTA_FC,ZR_High,ZR_LIMU,ZR_MIB_TOP_ab_Gen3,ZR_Standard
 SG_ MO_QBit_Fahrpedalwerte_01 : 20|1@1+ (1.0,0.0) [0.0|1] ""  ZR_High,ZR_LIMU,ZR_MIB_TOP_ab_Gen3,ZR_Standard
 SG_ MO_Fahrpedalgradient : 21|8@1+ (25,0) [0|6350] "Unit_PerCentPerSecon"  OTA_FC,ZR_High
 SG_ MO_Sig_Fahrpedalgradient : 29|1@1+ (1.0,0.0) [0.0|1] ""  ZR_High
 SG_ MO_rel_Saugrohrdruck : 30|6@1+ (18,0) [0|1116] "Unit_MilliBar"  Vector__XXX
 SG_ MO_rel_Saugrohrdruck_gem_err : 36|1@1+ (1.0,0.0) [0.0|1] ""  Vector__XXX
 SG_ MO_Moment_im_Leerlauf : 37|1@1+ (1.0,0.0) [0.0|1] ""  ZR_High
 SG_ MO_Schubabschaltung : 38|1@1+ (1.0,0.0) [0.0|1] ""  Vector__XXX
 SG_ MO_StartStopp_StoppVorbereitung : 39|1@1+ (1.0,0.0) [0.0|1] ""  OTA_FC
 SG_ MO_Solldrehz_Leerlauf : 40|8@1+ (10,0) [0|2540] "Unit_MinutInver"  Vector__XXX
 SG_ MO_Entkopplung_Sollschlupf : 48|7@1+ (20,0) [0|2480] "Unit_MinutInver"  Vector__XXX
 SG_ MO_temporaere_Fahrerabwesenheit : 55|1@1+ (1.0,0.0) [0.0|1] ""  Vector__XXX
 SG_ TSK_a_Soll_gradientenbegrenzt : 57|7@1+ (0.1,-7.2) [-7.2|5.4] "Unit_MeterPerSeconSquar"  Vector__XXX

BO_ 1654 Motor_21: 8 Gateway
 SG_ StSt_Koord_Wiederstart_Anz_09 : 0|1@1+ (1.0,0.0) [0.0|1] ""  Vector__XXX
 SG_ StSt_Koord_Wiederstart_Anz_10 : 1|1@1+ (1.0,0.0) [0.0|1] ""  Vector__XXX
 SG_ StSt_Koord_Wiederstart_Anz_11 : 2|1@1+ (1.0,0.0) [0.0|1] ""  Vector__XXX
 SG_ MO_Wiederstart_Anz_01 : 12|1@1+ (1.0,0.0) [0.0|1] ""  ZR_High
 SG_ MO_Wiederstart_Anz_02 : 13|1@1+ (1.0,0.0) [0.0|1] ""  ZR_High
 SG_ MO_Wiederstart_Anz_03 : 14|1@1+ (1.0,0.0) [0.0|1] ""  ZR_High
 SG_ MO_Wiederstart_Anz_Std : 15|1@1+ (1.0,0.0) [0.0|1] ""  ZR_High
 SG_ MO_Stoppverbot_Anz_01 : 16|1@1+ (1.0,0.0) [0.0|1] ""  ZR_High
 SG_ MO_Stoppverbot_Anz_02 : 17|1@1+ (1.0,0.0) [0.0|1] ""  ZR_High
 SG_ MO_Stoppverbot_Anz_03 : 18|1@1+ (1.0,0.0) [0.0|1] ""  ZR_High
 SG_ MO_Stoppverbot_Anz_04 : 19|1@1+ (1.0,0.0) [0.0|1] ""  ZR_High
 SG_ MO_Stoppverbot_Anz_05 : 20|1@1+ (1.0,0.0) [0.0|1] ""  ZR_High
 SG_ MO_Stoppverbot_Anz_06 : 21|1@1+ (1.0,0.0) [0.0|1] ""  ZR_High
 SG_ MO_Stoppverbot_Anz_07 : 22|1@1+ (1.0,0.0) [0.0|1] ""  ZR_High
 SG_ MO_Stoppverbot_Anz_08 : 23|1@1+ (1.0,0.0) [0.0|1] ""  ZR_High
 SG_ MO_Stoppverbot_Anz_09 : 24|1@1+ (1.0,0.0) [0.0|1] ""  ZR_High
 SG_ MO_Stoppverbot_Anz_10 : 25|1@1+ (1.0,0.0) [0.0|1] ""  ZR_High
 SG_ MO_Stoppverbot_Anz_11 : 26|1@1+ (1.0,0.0) [0.0|1] ""  ZR_High
 SG_ MO_Stoppverbot_Anz_Std : 27|1@1+ (1.0,0.0) [0.0|1] ""  ZR_High
 SG_ StSt_Koord_Stoppverbot_Anz_20 : 28|1@1+ (1.0,0.0) [0.0|1] ""  Vector__XXX
 SG_ StSt_Koord_Stoppverbot_Anz_21 : 29|1@1+ (1.0,0.0) [0.0|1] ""  Vector__XXX
 SG_ StSt_Koord_Wiederstart_Anz_Std : 30|1@1+ (1.0,0.0) [0.0|1] ""  Vector__XXX
 SG_ StSt_Koord_Status_Bremspedalkzpt : 31|1@1+ (1.0,0.0) [0.0|1] ""  ZR_High
 SG_ StSt_Koord_Wiederstart_Anz_01 : 32|1@1+ (1.0,0.0) [0.0|1] ""  Vector__XXX
 SG_ StSt_Koord_Wiederstart_Anz_02 : 33|1@1+ (1.0,0.0) [0.0|1] ""  Vector__XXX
 SG_ StSt_Koord_Wiederstart_Anz_03 : 34|1@1+ (1.0,0.0) [0.0|1] ""  Vector__XXX
 SG_ StSt_Koord_Wiederstart_Anz_04 : 35|1@1+ (1.0,0.0) [0.0|1] ""  Vector__XXX
 SG_ StSt_Koord_Wiederstart_Anz_05 : 36|1@1+ (1.0,0.0) [0.0|1] ""  Vector__XXX
 SG_ StSt_Koord_Wiederstart_Anz_06 : 37|1@1+ (1.0,0.0) [0.0|1] ""  Vector__XXX
 SG_ StSt_Koord_Wiederstart_Anz_07 : 38|1@1+ (1.0,0.0) [0.0|1] ""  Vector__XXX
 SG_ StSt_Koord_Wiederstart_Anz_08 : 39|1@1+ (1.0,0.0) [0.0|1] ""  Vector__XXX
 SG_ StSt_Koord_Stoppverbot_Anz_01 : 40|1@1+ (1.0,0.0) [0.0|1] ""  ZR_High
 SG_ StSt_Koord_Stoppverbot_Anz_02 : 41|1@1+ (1.0,0.0) [0.0|1] ""  ZR_High
 SG_ StSt_Koord_Stoppverbot_Anz_03 : 42|1@1+ (1.0,0.0) [0.0|1] ""  ZR_High
 SG_ StSt_Koord_Stoppverbot_Anz_04 : 43|1@1+ (1.0,0.0) [0.0|1] ""  ZR_High
 SG_ StSt_Koord_Stoppverbot_Anz_05 : 44|1@1+ (1.0,0.0) [0.0|1] ""  Vector__XXX
 SG_ StSt_Koord_Stoppverbot_Anz_06 : 45|1@1+ (1.0,0.0) [0.0|1] ""  Vector__XXX
 SG_ StSt_Koord_Stoppverbot_Anz_07 : 46|1@1+ (1.0,0.0) [0.0|1] ""  Vector__XXX
 SG_ StSt_Koord_Stoppverbot_Anz_08 : 47|1@1+ (1.0,0.0) [0.0|1] ""  Vector__XXX
 SG_ StSt_Koord_Stoppverbot_Anz_09 : 48|1@1+ (1.0,0.0) [0.0|1] ""  Vector__XXX
 SG_ StSt_Koord_Stoppverbot_Anz_10 : 49|1@1+ (1.0,0.0) [0.0|1] ""  Vector__XXX
 SG_ StSt_Koord_Stoppverbot_Anz_11 : 50|1@1+ (1.0,0.0) [0.0|1] ""  Vector__XXX
 SG_ StSt_Koord_Stoppverbot_Anz_12 : 51|1@1+ (1.0,0.0) [0.0|1] ""  Vector__XXX
 SG_ StSt_Koord_Stoppverbot_Anz_13 : 52|1@1+ (1.0,0.0) [0.0|1] ""  Vector__XXX
 SG_ StSt_Koord_Stoppverbot_Anz_14 : 53|1@1+ (1.0,0.0) [0.0|1] ""  Vector__XXX
 SG_ StSt_Koord_Stoppverbot_Anz_15 : 54|1@1+ (1.0,0.0) [0.0|1] ""  Vector__XXX
 SG_ StSt_Koord_Stoppverbot_Anz_16 : 55|1@1+ (1.0,0.0) [0.0|1] ""  Vector__XXX
 SG_ StSt_Koord_Stoppverbot_Anz_17 : 56|1@1+ (1.0,0.0) [0.0|1] ""  Vector__XXX
 SG_ StSt_Koord_Stoppverbot_Anz_Std : 57|1@1+ (1.0,0.0) [0.0|1] ""  Vector__XXX
 SG_ StSt_Koord_Stoppverbot_Anz_18 : 58|1@1+ (1.0,0.0) [0.0|1] ""  Vector__XXX
 SG_ StSt_Koord_Stoppverbot_Anz_19 : 59|1@1+ (1.0,0.0) [0.0|1] ""  Vector__XXX
 SG_ MO_StaGluehk : 60|4@1+ (8,0) [0|112] "Unit_PerCent"  Vector__XXX

BO_TX_BU_ 1178 :Gateway,Gateway_PAG;
BO_TX_BU_ 954 :Gateway,Gateway_PAG;
BO_TX_BU_ 956 :Gateway,Gateway_PAG;
BO_TX_BU_ 1180 :Gateway,Gateway_PAG;
BO_TX_BU_ 1170 :Gateway,Gateway_PAG;
BO_TX_BU_ 1173 :Gateway,Gateway_PAG;
BO_TX_BU_ 817 :Gateway,Gateway_PAG;
BO_TX_BU_ 1471 :Gateway,Gateway_PAG;
BO_TX_BU_ 2463978670 :ZR_High,ZR_LIMU,ZR_MIB_TOP_ab_Gen3;
BO_TX_BU_ 263 :Gateway,Gateway_PAG;
BO_TX_BU_ 1600 :Gateway,Gateway_PAG;
BO_TX_BU_ 1607 :Gateway,Gateway_PAG;
BO_TX_BU_ 167 :Gateway,Gateway_PAG;
BO_TX_BU_ 168 :Gateway,Gateway_PAG;
BO_TX_BU_ 958 :Gateway,Gateway_PAG;
BO_TX_BU_ 1631 :Gateway,Gateway_PAG;
BO_TX_BU_ 1648 :Gateway,Gateway_PAG;
BO_TX_BU_ 289 :Gateway,Gateway_PAG;
BO_TX_BU_ 1654 :Gateway,Gateway_PAG;
CM_ BO_ 1178 "ab MQB 7.2";
CM_ BO_ 956 "MLBevo";
CM_ BO_ 1180 "Ab MLBevo - CRC
";
CM_ BO_ 1170 "Ab MLBevo - CRC
";
CM_ BO_ 1173 "Ab MLBevo - CRC";
CM_ BO_ 1600 "ab MQB mit QBit Höheneinfo und MO_Versionsinfo_02";
CM_ BO_ 168 "Teil 2 neue Momentenschnittstelle MLB";
CM_ BO_ 1648 "Kombischnittstelle";

CM_ SG_ 1178 FS_BFS_Fond_Verst_enable "Verstellung Fond (vom MMI)
";
CM_ SG_ 1178 FS_BFS_KSS_Anfahrt "Komfortseitensicht Anfahrt BFS";
CM_ SG_ 1178 FS_BFS_Sitzsym_Anfahrt "Sitzsymetrie Anfahrt BFS";
CM_ SG_ 1178 FS_EE_BFS_enable "EasyEntry Freigabe für Befahrersitz.";
CM_ SG_ 1178 FS_EE_Fond_BFS_enable "EE Fond rechts

";
CM_ SG_ 1178 FS_EE_Fond_FS_enable "EE Fond links
";
CM_ SG_ 1178 FS_GHV_aktiv "Verstellung Gurthöhe
";
CM_ SG_ 1178 FS_Gurtbringer_Sperre "Freigabesignal für den Gurtzubringer";
CM_ SG_ 1178 FS_Kollisionsbereich_Windschott "Fahrersitz steht innerhalb oder außerhalb Windschottbereich. Sitzposition in Kennfeld bedeutet: Windschott kann ohne Kollision ausfahren.";
CM_ SG_ 1178 FS_Kollisionsgefahr_Windschott "Warnmeldung in Kombi anzeigen, dass manuelle oder automatische Sitzfahrt nicht (mehr) möglich ist, da Kollisionsgefahr zwischen Sitz und Windschott besteht.";
CM_ SG_ 1178 FS_KSV_aktiv "Verstellung Kopfstütze
";
CM_ SG_ 1178 FS_Lehne_nicht_verriegelt "Fahrer Sitz Lehne Verstellung Verriegelt Status

Verwendung nur im Bentley";
CM_ SG_ 1178 FS_LHV_aktiv "Verstellung Lordose Höhe
";
CM_ SG_ 1178 FS_LKV_aktiv "Verstellung Lehnenkopf
";
CM_ SG_ 1178 FS_LNV_aktiv "Verstellung Lehnenneigung
";
CM_ SG_ 1178 FS_LWV_aktiv "Verstellung Lordose W
";
CM_ SG_ 1178 FS_MMB_lokal_Stop "mit dem lokal Stop moechte man, dass ein Sitz mit Pneumatik - Lordose sich im Memoryfall wie ein Sitz mit elektromechanischer Lordose verhaelt. Nur lokler Abbruch im TIP-Betrieb.";
CM_ SG_ 1178 FS_MMB_storage "Memory-Positionstaste, Funkschlüssel-Memory-ID, Benutzerkonto-Nummer";
CM_ SG_ 1178 FS_MMB_storage_beep "Quittierungston Sitzmemory FS (Anforderung Kombi)";
CM_ SG_ 1178 FS_MMB_store_LED_on "LED für Speichern
";
CM_ SG_ 1178 FS_NFA_einfahren "Neigungsverstellbare Fussauflage im Fond muss eingefahren werden";
CM_ SG_ 1178 FS_SHV_aktiv "Verstellung Sitzhöhe

";
CM_ SG_ 1178 FS_Sitzfahrt_aktiv "Aktive Sitzfahrt Fahrersitz
";
CM_ SG_ 1178 FS_SLV_aktiv "Sitzlängsverstellung
";
CM_ SG_ 1178 FS_SNV_aktiv "Verstellung Sitzneigung
";
CM_ SG_ 1178 FS_Spezialposition_anfahren "paralell zu diesem Signal wird eine Botschaft auf den KCAN gesendet in der spezielle Anforderungen für den Empfänger stehen. 
Dieses Signal dient zusätzlich der Checksummenabsicherung bei einer Remotverstellung ";
CM_ SG_ 1178 FS_STV_aktiv "Verstellung Sitztiefe
";

CM_ SG_ 954 FS_BFS_aufraeumen "Das Signal dient der Fernsteuerung des Beifahrersitz.";
CM_ SG_ 954 FS_BFSFo_aufraeumen "Das Signal dient der Fernsteuerung des Beifahrersitz.";
CM_ SG_ 954 FS_FSFo_aufraeumen "Das Signal dient der Fernsteuerung des Beifahrersitz.";
CM_ SG_ 954 FS_MMB_Sys_Fahrt_aktiv "Signalisierung einer aktiven Verstellung, solange der Sitz und/oder die Lenksäule im Fall Peronalisierung eine Automatikfahrt durchführt. Nutzung dieses Signals zur Verkürzung der Anzeigedauer des Abbruchtexts im Kombi oder der entsprechenden Abbruchmögli";
CM_ SG_ 954 FS_Remote_KSV_Taste_hoch "Zu FS_Remote_Target zugehöriges Aktionssignal zur Fernsteuerung von Sitzfunktionen (hier KSV).";
CM_ SG_ 954 FS_Remote_KSV_Taste_tief "Zu FS_Remote_Target zugehöriges Aktionssignal zur Fernsteuerung von Sitzfunktionen (hier KSV).";
CM_ SG_ 954 FS_Remote_KSV_Taste_vor "Zu FS_Remote_Target zugehöriges Aktionssignal zur Fernsteuerung von Sitzfunktionen (hier KSVx).";
CM_ SG_ 954 FS_Remote_KSV_Taste_zurueck "Zu FS_Remote_Target zugehöriges Aktionssignal zur Fernsteuerung von Sitzfunktionen (hier KSVx).";
CM_ SG_ 954 FS_Remote_LKV_Taste_vor "Zu FS_Remote_Target zugehöriges Aktionssignal zur Fernsteuerung von Sitzfunktionen (hier LKV).";
CM_ SG_ 954 FS_Remote_LKV_Taste_zurueck "Zu FS_Remote_Target zugehöriges Aktionssignal zur Fernsteuerung von Sitzfunktionen (hier LKV).";
CM_ SG_ 954 FS_Remote_LNV_Taste_vor "Zu FS_Remote_Target zugehöriges Aktionssignal zur Fernsteuerung von Sitzfunktionen (hier LNV).";
CM_ SG_ 954 FS_Remote_LNV_Taste_zurueck "Zu FS_Remote_Target zugehöriges Aktionssignal zur Fernsteuerung von Sitzfunktionen (hier LNV).";
CM_ SG_ 954 FS_Remote_LWV_Taste_breit "Zu FS_Remote_Target zugehöriges Aktionssignal zur Fernsteuerung von Sitzfunktionen (hier LWV).";
CM_ SG_ 954 FS_Remote_LWV_Taste_eng "Zu FS_Remote_Target zugehöriges Aktionssignal zur Fernsteuerung von Sitzfunktionen (hier LWV).";
CM_ SG_ 954 FS_Remote_Massage_Taste "Zu FS_Remote_Target zugehöriges Aktionssignal zur Fernsteuerung von Sitzfunktionen (hier Massage).";
CM_ SG_ 954 FS_Remote_Multif_Taster_hoch "Zu FS_Remote_Target zugehöriges Aktionssignal zur Fernsteuerung von Sitzfunktionen (hier MuFu).";
CM_ SG_ 954 FS_Remote_Multif_Taster_tief "Zu FS_Remote_Target zugehöriges Aktionssignal zur Fernsteuerung von Sitzfunktionen (hier MuFu).";
CM_ SG_ 954 FS_Remote_Multif_Taster_vor "Zu FS_Remote_Target zugehöriges Aktionssignal zur Fernsteuerung von Sitzfunktionen (hier MuFu).";
CM_ SG_ 954 FS_Remote_Multif_Taster_zurueck "Zu FS_Remote_Target zugehöriges Aktionssignal zur Fernsteuerung von Sitzfunktionen (hier MuFu).";
CM_ SG_ 954 FS_Remote_Programmwippe_hoch "Zu FS_Remote_Target zugehöriges Aktionssignal zur Fernsteuerung von Sitzfunktionen (hier MuFu).";
CM_ SG_ 954 FS_Remote_Programmwippe_tief "Zu FS_Remote_Target zugehöriges Aktionssignal zur Fernsteuerung von Sitzfunktionen (hier MuFu).";
CM_ SG_ 954 FS_Remote_SHV_Taste_hoch "Zu FS_Remote_Target zugehöriges Aktionssignal zur Fernsteuerung von Sitzfunktionen (hier SHV).";
CM_ SG_ 954 FS_Remote_SHV_Taste_tief "Zu FS_Remote_Target zugehöriges Aktionssignal zur Fernsteuerung von Sitzfunktionen (hier SHV).";
CM_ SG_ 954 FS_Remote_SLV_Taste_vor "Zu FS_Remote_Target zugehöriges Aktionssignal zur Fernsteuerung von Sitzfunktionen (hier SLV).";
CM_ SG_ 954 FS_Remote_SLV_Taste_zurueck "Zu FS_Remote_Target zugehöriges Aktionssignal zur Fernsteuerung von Sitzfunktionen (hier SLV).";
CM_ SG_ 954 FS_Remote_SNV_Taste_hoch "Zu FS_Remote_Target zugehöriges Aktionssignal zur Fernsteuerung von Sitzfunktionen (hier SNV).";
CM_ SG_ 954 FS_Remote_SNV_Taste_tief "Zu FS_Remote_Target zugehöriges Aktionssignal zur Fernsteuerung von Sitzfunktionen (hier SNV).";
CM_ SG_ 954 FS_Remote_STV_Taste_vor "Zu FS_Remote_Target zugehöriges Aktionssignal zur Fernsteuerung von Sitzfunktionen (hier STV).";
CM_ SG_ 954 FS_Remote_STV_Taste_zurueck "Zu FS_Remote_Target zugehöriges Aktionssignal zur Fernsteuerung von Sitzfunktionen (hier STV).";
CM_ SG_ 954 FS_Remote_SWV_Taste_breit "Zu FS_Remote_Target zugehöriges Aktionssignal zur Fernsteuerung von Sitzfunktionen (hier SWV).";
CM_ SG_ 954 FS_Remote_SWV_Taste_eng "Zu FS_Remote_Target zugehöriges Aktionssignal zur Fernsteuerung von Sitzfunktionen (hier SWV).";
CM_ SG_ 954 FS_RemoteTarget "Empfänger-Nummer der zugehörigen FS_Remote-Signale (Fernsteuerung von Sitzfunktionen BFS, FSFo & BFSFo vom Fahrersitz aus)";
CM_ SG_ 954 Mem_FS_Lordose_hoch "Anforderung Lordosenwölbung nach oben zu verschieben.";
CM_ SG_ 954 Mem_FS_Lordose_runter "Anforderung Lordosenwölbung nach unten zu verschieben.";
CM_ SG_ 954 Mem_FS_Lordose_vor "Anforderung Lordosenwölbung pneumatisch zu vergrößern.";
CM_ SG_ 954 Mem_FS_Lordose_zurueck "Anforderung Lordosenwölbung zu verkleinern.";
CM_ SG_ 954 Mem_FS_Massage_Geschw "Weiterleitung  der gewünschten Massage Geschwindigkeit";
CM_ SG_ 954 Mem_FS_Massage_Intensitaet "Weiterleitung  der gewünschten Massage Intensität";
CM_ SG_ 954 Mem_FS_Massage_Programm "Weiterleitung  des gewünschten Massageprogramms";
CM_ SG_ 954 Mem_FS_SWangenLehne_beluef "Anforderung Seitenwangen Lehne zu vergrößern.";
CM_ SG_ 954 Mem_FS_SWangenLehne_entlue "Anforderung Seitenwangen Lehne zu verkleinern.";
CM_ SG_ 954 Mem_FS_SWangenSitz_beluef "Anforderung Seitenwangen Sitz zu vergrößern.";
CM_ SG_ 954 Mem_FS_SWangenSitz_entlue "Anforderung Seitenwangen Sitz zu verkleinern.";

CM_ SG_ 956 Mem_FSFo_Business_anfahren "Befehl um Business Position an zufahren";
CM_ SG_ 956 Mem_FSFo_Lordose_hoch "Anforderung Lordosenwölbung nach oben zu verschieben.";
CM_ SG_ 956 Mem_FSFo_Lordose_runter "Anforderung Lordosenwölbung nach unten zu verschieben.";
CM_ SG_ 956 Mem_FSFo_Lordose_vor "Anforderung Lordosenwölbung pneumatisch zu vergrößern.";
CM_ SG_ 956 Mem_FSFo_Lordose_zurueck "Anforderung Lordosenwölbung zu verkleinern.";
CM_ SG_ 956 Mem_FSFo_Massage_Geschw "Weiterleitung  der gewünschten Massage Geschwindigkeit ans IVB und zugleich Anforderungsbestätigung für LEDs am Klima-SG.";
CM_ SG_ 956 Mem_FSFo_Massage_Intens "Weiterleitung  der gewünschten Massage Intensität ans IVB und zugleich Anforderungsbestätigung für LEDs am Klima-SG.";
CM_ SG_ 956 Mem_FSFo_Massage_Prg "Weiterleitung  des gewünschten Massageprogramms ans IVB und zugleich Anforderungsbestätigung für LEDs am Klima-SG.";
CM_ SG_ 956 Mem_FSFo_MMB_glob_Stop "Globaler Abbruch für automatische Funktionen";
CM_ SG_ 956 Mem_FSFo_MMB_lokal_Stop "mit dem lokal Stop moechte man, dass ein Sitz mit Pneumatik - Lordose sich im Memoryfall wie ein Sitz mit elektromechanischer Lordose verhaelt. Nur lokler Abbruch im TIP-Betrieb.";
CM_ SG_ 956 Mem_FSFo_MMB_storage "Angabe der zu speichernden oder einzustellenden Memoryposition";
CM_ SG_ 956 Mem_FSFo_MMB_storage_beep "Quittierungston Sitzmemory  (Anforderung Kombi)";
CM_ SG_ 956 Mem_FSFo_MMB_store "Aufforderung Memory-Position Mem_HL_MMB_store zu speichern";
CM_ SG_ 956 Mem_FSFo_MMB_store_LED_on "LED zur Anzeige der Speicherbereitschaft";
CM_ SG_ 956 Mem_FSFo_MMB_tast "Einstellung der Memoryposition im  Tastbetrieb";
CM_ SG_ 956 Mem_FSFo_MMB_tipp "Einstellung der Memoryposition im  Tippbetrieb";
CM_ SG_ 956 Mem_FSFo_Relax_anfahren "Befehl um Relax Position an zufahren";
CM_ SG_ 956 Mem_FSFo_Sitzfahrt_aktiv "Signalisiert eine aktive Sitzfahrt.";
CM_ SG_ 956 Mem_FSFo_Sitztiefe_vor "Anforderung Sitztiefe nach vorne zu verlängern.";
CM_ SG_ 956 Mem_FSFo_Sitztiefe_zur "Anforderung Sitztiefe nach vorne zu verlängern.";

CM_ SG_ 1180 Mem_Taster_BT_01_BZ "4bit Botschaftszähler, wird in jeder Sendebotschaft inkrementiert";
CM_ SG_ 1180 Mem_Taster_BT_01_CRC "Für MLB:
'Berechnung siehe Lastenheft 'Kommunikationsabsicherung für FlexRay und CAN''

Ab MQB und MLBevo:
'Berechnung siehe Lastenheft 'End-to-End Kommunikationsabsicherung''

Endwerte siehe Begleitdokument 'S-PDU Kennungsfolgen'";
CM_ SG_ 1180 MTBT_M_Taste "Betätigung M-Taste BT";
CM_ SG_ 1180 MTBT_On_Off "Betätigung On-Off Taste BT";
CM_ SG_ 1180 MTBT_Pos1 "Betätigung Postionstaste 1 BT";
CM_ SG_ 1180 MTBT_Pos2 "Betätigung Postionstaste 2 BT";
CM_ SG_ 1180 MTBT_Pos3 "Betätigung Postionstaste 3 BT";
CM_ SG_ 1180 MTBT_Pos4 "Betätigung Postionstaste 4 BT";

CM_ SG_ 1170 Mem_Taster_FT_01_BZ "4bit Botschaftszähler, wird in jeder Sendebotschaft inkrementiert";
CM_ SG_ 1170 Mem_Taster_FT_01_CRC "Für MLB:
'Berechnung siehe Lastenheft 'Kommunikationsabsicherung für FlexRay und CAN''

Ab MQB und MLBevo:
'Berechnung siehe Lastenheft 'End-to-End Kommunikationsabsicherung''

Endwerte siehe Begleitdokument 'S-PDU Kennungsfolgen'";
CM_ SG_ 1170 MTFT_M_Taste "Betätigung M-Taste FT";
CM_ SG_ 1170 MTFT_On_Off "Betätigung On-Off Taste FT";
CM_ SG_ 1170 MTFT_Pos1_EE "Betätigung Postionstaste 1 FT";
CM_ SG_ 1170 MTFT_Pos2 "Betätigung Postionstaste 2 FT";
CM_ SG_ 1170 MTFT_Pos3 "Betätigung Postionstaste 3 FT";
CM_ SG_ 1170 MTFT_Pos4 "Betätigung Postionstaste 4 FT";

CM_ SG_ 1173 BFS_Kopfstuetzen_hoch "Kopfstützen hoch (Wird bei Rechtslenker vom TSG HL gesendet)";
CM_ SG_ 1173 BFS_Kopfstuetzen_runter "Kopfstützen runter (Wird bei Rechtslenker vom TSG HL gesendet)";
CM_ SG_ 1173 BFS_Laengsverst_vor "Längsverstellung vor (Wird bei Rechtslenker vom TSG HL gesendet)
";
CM_ SG_ 1173 BFS_Laengsverst_zurueck "Längsverstellung zurück (Wird bei Rechtslenker vom TSG HL gesendet)";
CM_ SG_ 1173 BFS_Lehnenkopf_vor "Lehnenkopf vor (Wird bei Rechtslenker vom TSG HL gesendet)";
CM_ SG_ 1173 BFS_Lehnenkopf_zurueck "Lehnenkopf zurück (Wird bei Rechtslenker vom TSG HL gesendet)";
CM_ SG_ 1173 BFS_Lehnenneigung_vor "Lehnenneigung vor (Wird bei Rechtslenker vom TSG HL gesendet)";
CM_ SG_ 1173 BFS_Lehnenneigung_zurueck "Lehnenneigung zurück (Wird bei Rechtslenker vom TSG HL gesendet)
";
CM_ SG_ 1173 BFS_Sitzhoehe_hoch "Dient der Sitzhoehenverstellung des Beifahrersitzes aus dem Fond";
CM_ SG_ 1173 BFS_Sitzhoehe_runter "Dient der Sitzhoehenverstellung des Beifahrersitzes aus dem Fond";
CM_ SG_ 1173 MTHBF_BZ "4bit Botschaftszähler, wird in jeder Sendebotschaft inkrementiert
(Wird bei Rechtslenker vom TSG HL gesendet)
";
CM_ SG_ 1173 MTHBF_CRC "Für MLB:
'Berechnung siehe Lastenheft 'Kommunikationsabsicherung für FlexRay und CAN''

Ab MQB und MLBevo:
'Berechnung siehe Lastenheft 'End-to-End Kommunikationsabsicherung''

Endwerte siehe Begleitdokument 'S-PDU Kennungsfolgen'";
CM_ SG_ 1173 MTHBF_ein "Wird bei Rechtslenker vom TSG HL gesendet";

CM_ SG_ 817 MFL_ECU_Err "MFL-µC Fehler";
CM_ SG_ 817 MFL_Eventcode_1 "Siehe Q-LAH MFL-Protokoll";
CM_ SG_ 817 MFL_Eventcode_2 "Siehe Q-LAH MFL-Protokoll";
CM_ SG_ 817 MFL_Lokalaktiv "Zeigt an ob das SG nach Klemme15 AUS und nach entsprechender MAX Aktivzeit noch aktiv war";
CM_ SG_ 817 MFL_LR_HZG_Err "Lenkradheizung Fehler";
CM_ SG_ 817 MFL_LR_HZG_Status "Status Lenkradheizung";
CM_ SG_ 817 MFL_M_Taste "Taster für Umschaltung Automatik/manuelles Schalten (Tiptronic)";
CM_ SG_ 817 MFL_Paddle_Verbau "Signalisiert den Zustand des Tipp-Paddle-Verbaus";
CM_ SG_ 817 MFL_Response_Err "siehe LIN2.0-Specification
(Darf nicht über ein Fehlergueltigkeitsbit abgesichtert werden!)";
CM_ SG_ 817 MFL_SatModul_links_Err "Schalter Tastermodul links Fehler";
CM_ SG_ 817 MFL_SatModul_rechts_Err "Schalter Tastermodul rechts Fehler";
CM_ SG_ 817 MFL_Signalhorn "Signalhorn nicht betaetigt/betaetigt";
CM_ SG_ 817 MFL_Signalhorn_Err "Signalhorn Fehler";
CM_ SG_ 817 MFL_Taste_links_Err "MFL_Tastenblock links Fehler";
CM_ SG_ 817 MFL_Taste_rechts_Err "MFL_Tastenblock rechts Fehler";
CM_ SG_ 817 MFL_Tastencode_1 "Beschreibt die Funktion einer fest zugeordneten Taste/Walze auf dem MFL. Bei Betätigung ändert sich der Wert von 0x0 auf den jeweiligen Tastencode.";
CM_ SG_ 817 MFL_Tastencode_2 "Beschreibt die Funktion einer fest zugeordneten Taste/Walze auf dem MFL. Ist MFL_Tastencode_1 wegen Betätigung einer Taste/Walze bereits mit einem Wert ungleich 0x0 belegt, so ändert sich bei Betätigung einer weiteren Taste/Walze der Wert dieses Signals v";
CM_ SG_ 817 MFL_Tip_Down "MFL-Tiptronic Tasten vom MFL für Getriebe
    0x0 = kein Tip_Down
    0x1 = Tip_Down";
CM_ SG_ 817 MFL_Tip_links_Err "Tiptronic links Fehler";
CM_ SG_ 817 MFL_Tip_rechts_Err "Tiptronic rechts Fehler";
CM_ SG_ 817 MFL_Tip_Up "MFL-Tiptronic Tasten vom MFL für Getriebe
    0x0 = kein Tip_Up
    0x1 = Tip_Up";
CM_ SG_ 817 MFL_Toggle "Watchdog Toggle-Bit";
CM_ SG_ 817 MFL_Variante "Markenspezifische Variantennummer des MFL";

CM_ SG_ 1471 MFL_Eventcode_1 "Siehe Q-LAH MFL-Protokoll";
CM_ SG_ 1471 MFL_Eventcode_2 "Siehe Q-LAH MFL-Protokoll";
CM_ SG_ 1471 MFL_Tastencode_1 "Beschreibt die Funktion einer fest zugeordneten Taste/Walze auf dem MFL. Bei Betätigung ändert sich der Wert von 0x0 auf den jeweiligen Tastencode.";
CM_ SG_ 1471 MFL_Tastencode_2 "Beschreibt die Funktion einer fest zugeordneten Taste/Walze auf dem MFL. Ist MFL_Tastencode_1 wegen Betätigung einer Taste/Walze bereits mit einem Wert ungleich 0x0 belegt, so ändert sich bei Betätigung einer weiteren Taste/Walze der Wert dieses Signals v";
CM_ SG_ 1471 MFL_Variante "Markenspezifische Variantennummer des MFL";

CM_ SG_ 2463978670 SDF2_MIB_Fehler_Laengsrichtung "Längsfehler der Positionierung im ZR.";
CM_ SG_ 2463978670 SDF2_MIB_Inhibitzeit "Zeitspanne zwischen Generierung und Versand der Positionsdaten im ZR.";
CM_ SG_ 2463978670 SDF2_MIB_Offset "Verbleibende Länge des Streckensegments, auf dem sich das Fahrzeug nach der Positionierung auf dem ZR befindet.";
CM_ SG_ 2463978670 SDF2_MIB_Segment_ID "PSD-Segment ID der Positionierung im ZR";
CM_ SG_ 2463978670 SDF2_MIB_Standort_Eindeutig "Information, ob die Position des Fahrzeugs im ZR eindeutig dem aktuellen Segment zugeordnet wurde.";

CM_ SG_ 263 MO_Anzeigedrehz "Optimierte Anzeigedrehzahl wegen sportlicherem Drehzahlmesser im Kombi. 
Bei Parallelhybrid: Anzeige VKM- Drehzahl nach Anzeigekonzept

Hinweis: Ehemaliger Fehlerwert 0xFFF wird senderseitig nicht unterstützt. Diesen Wert aus Kompatibilitätsgründen nic";
CM_ SG_ 263 MO_Effizienzmodus "Bei Handschaltern wird  das Fahrprogramm Effizienz signalisiert. 
Bei Automatikgetrieben wird das Fahrprogramm 'D' durch 'E' ersetzt.";
CM_ SG_ 263 MO_Fehler_Oeldrucksensor "Steuert  im Kombiinstrument die gelbe zentrale Warnlampe und das Symbol 'gelbe Ölkanne'  mit der Textmeldung 'Sensorfehler: Werkstatt aufsuchen' an
";
CM_ SG_ 263 MO_Istgang "Aktueller Gang für Anzeige Hochschaltempfehlung (gültig, wenn MO_Schaltempf_verfbar = 1).

Anzeige im Kombi:
Sollgang == Istgang         ==> Anzeige Istgang
Sollgang !=   Istgang         ==> Schaltempfehlung
Sollgang == Istgang == 0 ==> keine Anzeige";
CM_ SG_ 263 MO_KVS "Motorsteuergerätinterner Verbrauchszähler, der vom Kombi zyklisch ausgelesen wird, um die Einspritzmenge zur Verbrauchsmessung aufzusummieren; aus diesem Zählerstand werden Momentan- und Durchschnittsverbrauch berechnet; das Überlauf-Bit ist zu berücksich";
CM_ SG_ 263 MO_KVS_Ueberlauf "Der motorsteuergeräteinterne Verbrauchszähler ist mindestens einmal übergelaufen. Dieses Bit wird genutzt, um erkennen zu können, daß das Motorsteuergerät aus dem Reset-Zustand hochläuft.";
CM_ SG_ 263 MO_Ladedruck "absoluter Ladedruck";
CM_ SG_ 263 MO_Oeldruck "Öldruck analog zur Anzeige";
CM_ SG_ 263 MO_rel_Ladedruck "relativer Ladedruck (für Boostanzeige)";
CM_ SG_ 263 MO_Schaltempf_verfbar "Info, ob Schaltempfehlung im Fzg. verfügbar. Statischer Wert, ändert sich für ein Fzg. nicht!";
CM_ SG_ 263 MO_Sollgang "Motor sendet den Sollgang in den der Fahrer schalten soll. Wird im Kombi als Hochschaltempfehlung hervorgehoben (gültig, wenn MO_Schaltempf_verfbar = 1).

Anzeige im Kombi:
Sollgang == Istgang          ==> Anzeige Istgang
Sollgang !=  Istgang         ";

CM_ SG_ 1600 MO_Absperrventil_oeffnen "Signal an Klima-SG das Absperrrventil anzusteuern. Ab D4 auch 0x3 Ventil_schließen.

Im MQB wird hier der Soll-Status des Absperrventils ausgegeben.
Achtung: bei z. B. klemmendem Ventil entspricht das Signal nicht dem tatsächlichen Status!";
CM_ SG_ 1600 MO_aktives_Getriebeheizen "Information für Getriebe, ob ein Ventil für Getriebheizen angesteuert werden muss";
CM_ SG_ 1600 MO_Ansaugluft_Temp "In Fahrzeugen ohne Außentemperatur vom Kombi kann aus der Ansauglufttemperatur auf die Außentemperatur geschlossen werden. Beim SDI ist das mit einer gewissen Genauigkeit gegeben. Genutzt wird es vom ASG.";
CM_ SG_ 1600 MO_Getriebe_kuehlen "Anforderung Getriebekühlventilansteuerung";
CM_ SG_ 1600 MO_Heizungspumpenansteuerung "Anforderung Heizungspumpenansteuerung
MQB und Hybrid: Status der Heizungsunterstützungspumpe am MSG
";
CM_ SG_ 1600 MO_Hoeheninfo "Korrekturfaktor Höhe (1 entspricht 1013 mbar)";
CM_ SG_ 1600 MO_HYB_Fehler_HV_Netz "Im HV-Bordnetz ist fehlerbedingt kein generatorischer Betrieb möglich. Das 12V-Bordnetz wird über den DC/DC-Wandler allein aus der Traktionsbatterie gespeist. Um diesen Zustand möglichst lange aufrechterhalten zu können, sollten Komfort-Verbraucher abgesc";
CM_ SG_ 1600 MO_Kennfeldk "Die Kennfeldkühlung ist in diesem Fahrzeug verbaut und hat keinen Systemfehler";
CM_ SG_ 1600 MO_KL15_Abschaltempfehlung "Kessy Abschaltempfehlung nach Verlassen des Fahrzeugs";
CM_ SG_ 1600 MO_Kuehlmittel_Temp "Kuehlmitteltemperatur";
CM_ SG_ 1600 MO_Mom_Traegheit_02 "Massenträgheit (J) der Motors bzw. der Antriebsmaschinen in kgm².

Zur Berücksichtigung des E-Motor in Hybrid-Projekten:
in MLB-Projekten wird nur der J-Wert des Verbrennungsmotors und nicht der J-Wert des E-Motors berücksichtigt.
In MQB/MLBevo-Projek";
CM_ SG_ 1600 MO_Nachlaufzeit_Heizungspumpe "Nachlaufzeit für Heizungspumpe für Turboladerschutz";
CM_ SG_ 1600 MO_Oel_Temp "Realer Meßbereich ca. -40..150 Grad";
CM_ SG_ 1600 MO_QBit_Ansaugluft_Temp "
";
CM_ SG_ 1600 MO_QBit_Hoeheninfo "Qualifizierungsbit der Höheninfo. Gesetzt bei Ersatzwert, Init oder Fehler.";
CM_ SG_ 1600 MO_QBit_Kuehlmittel_Temp "
";
CM_ SG_ 1600 MO_SpannungsAnf "Forderung des Motor-SGs zur Spannungsanhebung";
CM_ SG_ 1600 MO_Versionsinfo_02 "Versioninformation vom Motor zur Steuerung bei inkompatiblen KMatrix-Änderung bzw. Einführung von neuen Funktionen, die in den Empfängern verriegelt werden müssen. Zu jedem Ereignis wird ein fixer Zählerstand zugeordnet, um dem Empfänger die funktionale Ä";

CM_ SG_ 1607 MO_CO2_Faktor "dynamischer Umrechnungsfaktor von l in CO2";
CM_ SG_ 1607 MO_E85_Sensor "Information über den E85 Gehalt (%-mass.) im Ottokraftstoff";
CM_ SG_ 1607 MO_Ethanol_Spuelhinweis "Hinweis das der Fahrer beim nächsten Tanken Ethanol armen Sprit tanken soll.";
CM_ SG_ 1607 MO_ITM_Kuehlmittel_Temp "Kuehlmitteltemperatur: Ersatzkühlmitteltemperatur für Motoren mit ITM (Thermomanagement)

ACHTUNG: Ab MQB wird in diesem Signal das Anzeigeplateau durch das MSG dargestellt!";
CM_ SG_ 1607 MO_Kraftstofffilter_Wasser "Für Schlechtkraftstoffländer wird das Wasserabscheidevolumen im Dieselkraftstofffilter mit einem  Wassersensor überwacht. Ist das Volumen erschöpft, erfolgt im Kombi eine entsprechende Anzeige.";
CM_ SG_ 1607 MO_MKB_01 "Motorkennbuchstabe 1";
CM_ SG_ 1607 MO_MKB_02 "Motorkennbuchstabe 2";
CM_ SG_ 1607 MO_MKB_03 "Motorkennbuchstabe 3";
CM_ SG_ 1607 MO_MKB_04 "Motorkennbuchstabe 4";
CM_ SG_ 1607 MO_MKB_MUX "Die vier Motorkennbuchstaben werden gemultiplext in MO_MKB übertragen. Das Signal MO_MKB_MUX stellt das Steuersignal für diesen Multiplexer dar.";
CM_ SG_ 1607 SCR_Akustik "Ansteuerung von Summer/Gong bei Aktivieren der SCR-Warnungen.
Bedienung des Signals nur bei Dieseln mit SCR-System. Andere senden Initwert.";
CM_ SG_ 1607 SCR_Anz_Motorstarts "Anzahl noch möglicher Motorstarts, wenn Reichweite = 0 ist
0..13 = Anzeige 'x mögliche Restarts'
14 = Eingeschränkte Fahrfunktion (z. Zt. Audi)
15 = keine Einschränkung (Anzeige Reichweite)
Bedienung des Signals nur bei Dieseln mit SCR-System.";
CM_ SG_ 1607 SCR_Inducement_Strategie "Art des Motor-Inducement-Konzepts. Abhängig von diesem Signal sind die Warntexte zwischen 'Kein Motorstart (in...km)' und 'eingeschränkte Fahrbarkeit (in ...km)' auszuwählen.";
CM_ SG_ 1607 SCR_Reichweite "Gesamtreichweite in km der aktuellen SCR-Tankfüllung, sofern die Reichweite kleiner 2400 km ist. Bei einer Reichweite größer 2400 km wird grundsätzlich der Initwert (32767) übertragen. Bedienung des Signals nur bei Dieseln mit SCR-System.";
CM_ SG_ 1607 SCR_Systemfehler "Ansteuerung Anzeige für SCR-Systemfehler";
CM_ SG_ 1607 SCR_Text "Warntext (z. B. in Kombination mit SCR Warnstufe und SCR-Systemfehler).
Bedienung des Signals nur bei Dieseln mit SCR-System. Andere senden Initwert.";
CM_ SG_ 1607 SCR_verbaut "Die SCR-Signale deren Initwert ungleich 0 sind, werden nur dann ausgewertet, wenn SCR_verbaut == 1 den Verbau des SCR Systems zeigt.";
CM_ SG_ 1607 SCR_Warnstufe_1 "Ansteuerung der SCR Füllstandswarnlampe (Stufe 1) (gelbe Lampe) SCR_Warnstufe_1 (Prio 2).
Bedienung des Signals nur bei Dieseln mit SCR-System. Andere senden Initwert.";
CM_ SG_ 1607 SCR_Warnstufe_2 "Ansteuerung der SCR Füllstandswarnlampe (Stufe 2) (Blinkbit für gelbe Lampe oder rote Lampe) SCR_Warnstufe_2 (Prio 1).
Bedienung des Signals nur bei Dieseln mit SCR-System. Andere senden Initwert.";

CM_ SG_ 167 MO_erste_Ungenauschwelle "Zusätzliche Ungenauigkeit (zur Grundungenauigkeit). Motormomente ungenau >8% (kleinste Ungenauschwelle)
";
CM_ SG_ 167 MO_Mom_Ist_Summe "Einheitenloser Wert! Faktor in MO_Faktor_Momente_02 in Motor_Code_01 beachten!

Ist-Moment als Summe aus Verbrennungsmotor und E-Motor (bei Hybrid-Konzepten) incl. allen Eingriffen und Korrekturen

In Fahrzeugen mit einer Antriebsachse bzw. mit mechan";
CM_ SG_ 167 MO_Mom_Schub "Einheitenloser Wert! Faktor in MO_Faktor_Momente_02 in Motor_Code_01 beachten!

Moment das sich einstellt, wenn der Fahrer 0% Fahrpedal gibt; bei konventionellen Projekten = alle Verluste (mechanische Reibung und sonstige Verluste) des Verbrennungsmotor";
CM_ SG_ 167 MO_Mom_Soll_gefiltert "Einheitenloser Wert! Faktor in MO_Faktor_Momente_02 in Motor_Code_01 beachten!

MO_Mom_Soll_Roh nach Fahrverhaltensfilter, begrenzt nach oben mit MO_Mom_Begr_dyn, Einrechnung der plausibilisierten Bremsen-Eingriffe; ohne Getriebe-Schalt-Eingriffe, ohne ";
CM_ SG_ 167 MO_Mom_Soll_Roh "Einheitenloser Wert! Faktor in MO_Faktor_Momente_02 in Motor_Code_01 beachten!

Momentenanforderung aus Fahrpedal bzw. von ACC/GRA bzw. aus dem Leerlaufregler (quasistatischer Anteil) bzw. aus Rekuperationsanforderung; keine Begrenzungen, keine Filterun";
CM_ SG_ 167 MO_Mom_Traegheit_Summe "Einheitenloser Wert! Faktor in MO_Faktor_Momente (CAN V6.x) bzw. MO_Faktor_Momente_02 (CAN V7.x) in Motor_Code_01 beachten!

Moment, das zur Beschleunigung der trägen Massen aufgewendet wird bzw. frei wird; Summen aus Anteilen für Verbrennungsmotor und ";
CM_ SG_ 167 MO_QBit_Motormomente "AUDI D4: Zykluszeit: 10ms (siehe Zykluszeit schnell/Cycletime Fast)

Ungenaue Momentenangaben, weil die Momente aus Ersatzwerten berechnet wurden (z.B. HFM ausgefallen). Qualifizierungsbit für die Motormomente.

Achtung:
Reduktion der Zykluszeit Moto";
CM_ SG_ 167 MO_Status_Normalbetrieb_01 "Das Motorsteuergerät sendet das Informationsbit, wenn die Initialisierungsphase des Steuergerätes abgeschlossen ist. Zusätzlich muss die Klemme 15 eingeschalten sein und eine applizierbare Mindestdrehzahlschwelle (Kennlinie in Abh. von der Kühlwassertempe";
CM_ SG_ 167 Motor_11_BZ "Botschaft asynchron geroutet. Zählerwert kann springen.";
CM_ SG_ 167 Motor_11_CRC "Für MLB:
'Berechnung siehe Lastenheft 'Kommunikationsabsicherung für FlexRay und CAN''

Ab MQB und MLBevo:
'Berechnung siehe Lastenheft 'End-to-End Kommunikationsabsicherung''

Endwerte siehe Begleitdokument 'S-PDU Kennungsfolgen'";

CM_ SG_ 168 MO_Drehzahl_01 "Im Fehlerfall wird die Motordrehzahl über die Nockenwellendrehzahl als Ersatzgrösse ausgegeben

Bei Parallelhybrid: Getriebeeingangsdrehzahl (=E-Maschinen Drehzahl)

Hinweis: 
Ehemaliger Fehlerwert 0xFFFF wird senderseitig nicht unterstützt. 
Diesen";
CM_ SG_ 168 MO_Mom_Begr_dyn "Einheitenloser Wert! Faktor in MO_Faktor_Momente (CAN V6.x) bzw. MO_Faktor_Momente_02 (CAN V7.x/V8.x) in Motor_Code_01 beachten!

Bei aktueller Drehzahl kurzfristig (ca. 100..200 ms) max. mögliches Moment (Summe aus Verbrennungsmotor und E-Motor), wird ";
CM_ SG_ 168 MO_Mom_Begr_stat "Einheitenloser Wert! Faktor in MO_Faktor_Momente (CAN V6.x) bzw. MO_Faktor_Momente_02 (CAN V7.x) in Motor_Code_01 beachten!

Bei aktueller Drehzahl quasistationär (nach ca. 3..5 s) max. mögliches Moment (Summe aus max. Moment des Verbrennungsmotors aus ";
CM_ SG_ 168 MO_Mom_neg_verfuegbar "Einheitenloser Wert! Faktor in MO_Faktor_Momente (CAN V6.x) bzw. MO_Faktor_Momente_02 (CAN V7.x) in Motor_Code_01 beachten!

Bei aktueller Drehzahl im nächsten Task (bei CAN-Übertragung z.B. 10ms) tatsächlich verfügbares negatives Moment (Summe aus Verl";
CM_ SG_ 168 MO_Momentenintegral_02 "100  %  entspricht volle Verfügbarkeit aktuell vorhanden. 0 % entspricht Integral bis Limit gefüllt, erhöhender Eingriff kann aktuell nicht berücksichtigt werden oder aufgrund eines Fehlers nicht verfügbar
";
CM_ SG_ 168 MO_QBit_Drehzahl_01 "AUDI D4: Zykluszeit: 10ms (siehe Zykluszeit schnell/Cycletime Fast)

Achtung:
Reduktion der Zykluszeit Motor_03 auf 10ms geplant.
Projektabhängig soll künftig mit 10ms gesendet werden.
Empfänger die in weiteren Konzern-Projekten eingesetzt werden müs";
CM_ SG_ 168 Motor_12_CRC "Für MLB:
'Berechnung siehe Lastenheft 'Kommunikationsabsicherung für FlexRay und CAN''

Ab MQB und MLBevo:
'Berechnung siehe Lastenheft 'End-to-End Kommunikationsabsicherung'

Endwerte siehe Begleitdokument 'S-PDU Kennungsfolgen'";

CM_ SG_ 958 MO_Aussp_Anlass "Das Signal zeigt an, ob die Wiederholstartsperre aktiv ist. D. h. eine Ansteuerung des Anlassers wird auch bei erfüllten Startvoraussetzungen (HS: Interlock betätigt bzw. AT: P/N eingelegt und Bremse betätigt) nicht erfolgen.";
CM_ SG_ 958 MO_BKV_Unterdruckwarnung "Über die Unterdruckwarnung signalisiert das MSG dem ESP, dass kein ausreichender Unterdruck für den BKV zur Verfügung gestellt werden kann.";
CM_ SG_ 958 MO_BLS "Ungefiltertes Rohsignal des Bremslichtschalters, nur wenn HW-Eingang bestückt und ausgewertet wird. Bei Motoren ohne genutzten HW-Eingang wird kein Ersatzwert (bspw. SW-Signal über CAN) ausgegeben!
Bei AUDI muss das Signal wg. Bremslichtfunktion immer be";
CM_ SG_ 958 MO_BMS_NV_Anf_stuetzen "Garantierte Unterstützung des Zusatzspeichers ist erforderlich. Zusatzspeicher muss an das Versorgungsnezt angebunden werden. ";
CM_ SG_ 958 MO_EKlKomLeiRed "Anforderung an die Klimasteuerung, die Leistungsaufnahme des E-Kompressors bei schlechtem SOC und in bestimmten Fahrsituationen zu begrenzen. (Das bereits bestehende Signal 'Klimakompressor aus' als stets umzusetzende Anforderung bleibt unverändert besteh";
CM_ SG_ 958 MO_Ext_E_Fahrt_aktiv "Funktionsrückmeldung zum erw. E-Fahr-Betrieb über Lampe/LED im E-Mode-Taster";
CM_ SG_ 958 MO_Fahrer_bremst "Redundante Bremsinformation vom Motor.

MLB:
AUDI D4: Zykluszeit: 10ms (siehe Zykluszeit schnell/Cycletime Fast)
Im AUDI B8 wird in diesem Bit der Wert der ESP-CAN-Information 'ESP_Fahrer_bremst' ausgegeben.

Achtung:
Reduktion der Zykluszeit Motor";
CM_ SG_ 958 MO_FMAus_aktiv "Das Signal gibt Rückmeldung ob Freilauf Motor aus aktiv ist. Beleibt auch 0km/h (unterhalb der StartStopp Schwelle) weiterhin aktiv.";
CM_ SG_ 958 MO_FMAus_Startvariante "Startvariante beim Motorstart aus der Freilauf-Motor-AUS Phase";
CM_ SG_ 958 MO_Freig_Anlass "Bit wird gesetzt, wenn der Motor beim Automatikstart gestartet werden darf (Motorstillstand, Emissionsmaßnahmen sind erfüllt).";
CM_ SG_ 958 MO_Freig_Reku "Empfehlung des Motor-SG's zur Spannungsabsenkung/-anhebung für den Rekuperationsbetrieb";
CM_ SG_ 958 MO_Freigabe_Segeln "Freigabebit des Segelbetriebs im Getriebe. Bedingt durch bestimmte Diagnosen und Adaptionen des MSGs, die nur im Schub möglich sind, darf nicht jede Schubphase für einen Segelbetrieb genutzt werden. Eine Freigabe bleibt auch außerhalb einer Schubphase bes";
CM_ SG_ 958 MO_Gangposition "MLB:
Stellung des Wählhebels in der Schaltgasse des Handschaltgetriebes.
MLBevo: 
Ausweitung der Bedienung auch auf Automatikgetriebe;
Routing des Signals GE_Fahrstufe: 
1. Position_R (dez. 6) auf MO_Gangposition: Gang_R (dez. 13) wegen Entfall Signa";
CM_ SG_ 958 MO_Handshake_STH "Es gilt: Signalspec MO_Handshake v1.0

Handshake zwischen MSG und STH. Wenn das MSG die EKP aufgrund einer STH-Anforderung ansteuert und kein Fehlereintrag bzgl. EKP/KPE/NDR vorliegt, wird das Bit gesetzt.";
CM_ SG_ 958 MO_HYB_Fahrbereitschaft "Signal steuert u.a. in der Lenkhilfe zusammen mit weiteren Informationen den Modewechsel in den 'Drivemode'
Grüne Anzeige im Kombiinstrument zur Signalisierung der Bereitschaft des Hybridsystems.";
CM_ SG_ 958 MO_HYB_VM_aktiv "0 = VMotor wird nicht aktiv gehalten (nVM < n_min und keine LL-Regelung aktiv)
1 = VMotor aktiv (ab der ersten Einspritzung; gilt auch für Schubbetrieb, wenn VMotor spätestens durch LLRegelung befeuert würde)
Verwendet zur Bestimmung des Ist-Zustandes";
CM_ SG_ 958 MO_Interlock "Das Motorsteuergerät gibt die Information aus, ab wann der Kupplungsschalter durch das Motorsteuergerät als getreten gesehen wird.
Bei Systemen für Start Stopp muss das Interlocksignal für einen Start durch das MSG generiert werden, sobald der Schalthebe";
CM_ SG_ 958 MO_Kickdown "Es gilt: Signalspec MO_Kickdown v1.0";
CM_ SG_ 958 MO_Kl_50 "Klemme 50: Startausführung durch Ritzelstarter

MLB: nicht von allen Motoren gesendet
MQB/MLBevo: gesendet von allen Motoren";
CM_ SG_ 958 MO_Kl_75 "Klemme X
";
CM_ SG_ 958 MO_Klima_Eingr "Eingriffe des Motor bei der Klima";
CM_ SG_ 958 MO_KomFehler_ESP "Anzeige Kommunikationsfehler bei Empfang vom ESP";
CM_ SG_ 958 MO_Konsistenz_Bremsped "MLB:

AUDI D4: Zykluszeit: 10ms (siehe Zykluszeit schnell/Cycletime Fast)
Siehe 'Funktionsspezifikation Bremslichtinfo B8'

Achtung:
Reduktion der Zykluszeit Motor_03 auf 10ms geplant.
Projektabhängig soll künftig mit 10ms gesendet werden.
Empfäng";
CM_ SG_ 958 MO_Kuppl_schalter "MLB:
Das Motorsteuergerät gibt die Information aus, ab wann der Kupplungsschalter durch das Motorsteuergerät als getreten gesehen wird
0x0: Schalter sagt betätigt (Ausgekuppelt)
0x1: Schalter sagt nicht betätigt (Eingekuppelt)

MQB:
Nur Handschalter";
CM_ SG_ 958 MO_Motor_laeuft "Das Motorsteuergerät gibt die Information aus, ab wann der Motor verbrennungsbedingt autark läuft und durch zuschaltbare Nebenaggregate mechanisch belastbar ist (z.B. durch Generator, Klimakompressor, etc.).

Die 'Motor läuft' Information wird ausgegebe";
CM_ SG_ 958 MO_PTC_Status "Status-Rückmeldung vom MSG zum aktuellen PTC-Status (stufiges PTC, Relais am MSG). Bei Ansteuerung eines stufigen PTC durch ein anderes SG beschreibt das Signal die vom MSG freigegebene PTC-Stufe.";
CM_ SG_ 958 MO_QBit_Fahrer_bremst "MLB:
AUDI D4: Zykluszeit: 10ms (siehe Zykluszeit schnell/Cycletime Fast)

Achtung:
Reduktion der Zykluszeit Motor_03 auf 10ms geplant.
Projektabhängig soll künftig mit 10ms gesendet werden.
Empfänger die in weiteren Konzern-Projekten eingesetzt werd";
CM_ SG_ 958 MO_QBit_Gangposition "Qualitätsbit zum Signal MO_Gangposition";
CM_ SG_ 958 MO_QBit_KL_75 "Q - Bit für das KL 75 Signal zur Vermeidung der fehlerhaften Erkennung von Motorstarts. 
Wird auf 1 gesetzt, solange das Motorsteuergerät KL15 = AUS erkannt hat.";
CM_ SG_ 958 MO_Remotestart_Betrieb "Das MSG ist für den Remotestart-Betrieb bereit. Nach Empfang der Motorstartanforderung für RSt-Betrieb durch BCM wird der Fahrzeugmotor gestartet und solange der Motor läuft, bleibt dieses Bit aktiv. Dieses Signal ist nur zur Verwendung durch das BCM zur ";
CM_ SG_ 958 MO_Remotestart_moeglich "Wenn Bit gesetzt, würde das MSG bei entsprechender Anforderung durch das BCM den Remotestartbetrieb einleiten, d.h. das MSG ist remotestartfähig und es liegen aktuell keine relevanten Fehler oder andere Abbruchgründe vor.";
CM_ SG_ 958 MO_Signalquelle_Gangposition "Signalquelle des Signals MO_Gangposition
0: Signalquelle Gangpositionssensor
1: Signalquelle Modellwert (v/n)";
CM_ SG_ 958 MO_StartStopp_Fahrerwunsch "Fahreraktivität Start/Stop";
CM_ SG_ 958 MO_StartStopp_Motorstopp "Motor-Stopp durch Start/Stopp-Koordinator
HYBRID:
Wenn MO_Hybridfahrzeug = 1 gilt:
Verbrennungsmotor durch Hybrid-Koordinator im MSG ausgeschaltet. 
Die definierten Start/Stopp-Signale beziehen sich nur auf den Verbrennungsmotor!";
CM_ SG_ 958 MO_StartStopp_Status "Aktivitätsstatus Start/Stopp-Koordinator
HYBRID:
Wenn MO_Hybridfahrzeug = 1 gilt:
Signal bezieht sich nur auf den Verbrennungsmotor, nicht auf den Hybridantrieb
";
CM_ SG_ 958 MO_StartStopp_Wiederstart "Motorwiederstart durch Start/Stopp-Koordinator
HYBRID:
Wenn MO_Hybridfahrzeug =1 gilt:
Warnung vor Spannungseinbruch beim Zustart des Verbrennungsmotors. 
-nicht relevant, da derzeit kein Start über 12V-Starter geplant-
Dieses Signal wird nur vom Hyb";
CM_ SG_ 958 MO_StartVorauss_erfuellt "Dient der Fallunterscheidung bei ZAT-Betätigung im Zustand 'KL15 ein' (bei nicht gesetztem Signal folgt KL15 aus, bei gesetztem Signal folgt setzen KL50-Anf.)

0: Signal nicht bedient 
1: Voraussetzungen zur Antriebsstrangaktivierung / Startvoraussetzu";
CM_ SG_ 958 MO_Zylinderabschaltung "Status Zylinderabschaltung Motor";
CM_ SG_ 958 Motor_14_CRC "Ab MQB und MLBevo:
'Berechnung siehe Lastenheft 'End-to-End Kommunikationsabsicherung'

Endwerte siehe Begleitdokument 'S-PDU Kennungsfolgen'";

CM_ SG_ 1631 MO_Anzeige_Kaltleuchte "Fahrleistungseinschänkungen aus dem Motor-Abgasmanagement zur Anzeige als Lampe ohne Hinweistext im Kombiinstrument";
CM_ SG_ 1631 MO_DPF_reg "Regeneration Diesel-Partikel-Filter";
CM_ SG_ 1631 MO_Energieinhalt_BMS "Restenergieinhalt der Traktionsbatterie, beeinflusst durch Fahrstrategie und weiteren Faktoren der Antriebssteuerung.";
CM_ SG_ 1631 MO_Heizstrom_EKAT "Aktuelle Gesamtstromaufnahme des E-Katalysators";
CM_ SG_ 1631 MO_Heizstrom_SCR "Aktuelle Gesamtstromaufnahme der Tank-, Fördermodul- und Leitungsheizung des SCR-Systems";
CM_ SG_ 1631 MO_P_Generator_ungefiltert_Anf "Bei Empfang der Anforderung soll der Sender BEM_P_Generator ungefiltert befüllen.";
CM_ SG_ 1631 MO_SpannungsAnf_02 "Forderung des Motor-SG's zur Spannungsanhebung";
CM_ SG_ 1631 TSK_Fahrzeugmasse_02 "Neue Definition ab D4
Fahrzeugmasse in kg. Das Signal dient der Anpassung der Sollbeschleunigung vom ACC


";
CM_ SG_ 1631 TSK_Grundmasse "Fahrzeuggrundmasse in kg. Das Signal dient der Anpassung der Sollbeschleunigung vom ACC

Hinweis: Ehemaliger Fehlerwert 0x7F wird senderseitig nicht unterstützt. Diesen Wert aus Kompatibilitätsgründen nicht neu belegen!";
CM_ SG_ 1631 TSK_Steigung_02 "Steigung in % Berg. Das Signal dient der Anpassung der Sollbeschleunigung vom ACC

Positive Werte > bergauf; 
Negative Werte < bergab

Fehler: Die Steigung aufgrund eines Fehlers (mit KD-Fehlereintrag) nicht mehr berechnet werden";

CM_ SG_ 1648 MO1_Freigabe_Info_WFS "WFS-Freigabeinformation";
CM_ SG_ 1648 MO1_Freigabe_Verfallsinfo_WFS "WFS-Freigabeverfallsinformation";
CM_ SG_ 1648 MO1_Sperr_Info_WFS "WFS-Sperrinformation";
CM_ SG_ 1648 MO_Abstellzeit "Abstelldauer nach letztem KL15 aus

Hinweis: 
Ehemaliger Fehlerwert 0xFF wird senderseitig nicht unterstützt. 
Diesen Wert aus Kompatibilitätsgründen nicht neu belegen!";
CM_ SG_ 1648 MO_Abstellzeit_Status "Statusinformation zur Abstellzeit
0: Die dem Status zugeordnete Variable konnte noch nicht berechnet werden. 
1: Die dem Status zugehörige Variable wurde korrekt berechnet. 
2: Der Wert der zugehörigen Variablen ist nur ein Minimalwert. 
3: Der Wert d";
CM_ SG_ 1648 MO_ANC_Kennfeld_Anf "Anforderung ANC Kennfeldumschaltung";
CM_ SG_ 1648 MO_Anzahl_Abgesch_Zyl "Gibt die Anzahl der abgeschalteten Zylinder an. In Übergangszuständen wird der Zielbetriebszustand angezeigt.";
CM_ SG_ 1648 MO_Bremslicht_Reku "Bremslicht (ggf. bei Rekuperation durch E-Motor) wird angesteuert";
CM_ SG_ 1648 MO_Drehzahl_Warnung "Warnhinweis zum Kombi im Fall einer fehlerbehafteten Drehzahlbegrenzung";
CM_ SG_ 1648 MO_EPCL "Die Anforderung der EPC-Lampe vom MSG ans Kombi soll durch das Bus-Signal MO_EPCL gemäß folgender Logik erfolgen:
MO_EPCL = 0 dez -> EPC Lampe aus, kein Text
MO_EPCL = 1 dez -> gelbe EPC-Symbolik, Text „Antrieb: Störung! Bitte Service aufsuchen“
MO_EPC";
CM_ SG_ 1648 MO_Ethanol_BS_Texte "Ethanol Brennstoff-Texte im Kombi

0 = kein Text
1 = E85 Warm_Up
2 = FlexFuel Warnung 3.Stufe (Too cold for ethanol)
3 = Warmfahrempfehlung MQB / FlexFuel Warnung 1.Stufe (Refuel with gasoline)
4 = FlexFuel Warnung 2. Stufe (Refuel with gasoline)
5";
CM_ SG_ 1648 MO_Fahrzeugtyp "Unterscheidet die Fahrzeugtypen bzgl. der Antriebsart";
CM_ SG_ 1648 MO_Fehler_Zylabsch "Fehlerstatus der Funktion Zylinderabschaltung ";
CM_ SG_ 1648 MO_Hybrid_StartStopp_LED "Ansteuerung der Funktions-LED der Hybrid Taste bzw. Start/Stop Deaktivierungstaste.
Der Start/Stopp-Master (derzeit im MSG) (oder ein künftiger Hybrid-Master) soll die Ansteuerung senden.";
CM_ SG_ 1648 MO_max_Ladedruck "maximal möglicher Ladedruck (zur Anpassung des Anzeigebereichs bei absoluter Ladedruckanzeige)";
CM_ SG_ 1648 MO_NMAX_Schaltanzeige "Maximaldrehzahl für Schaltanzeige";
CM_ SG_ 1648 MO_obere_Drehzahlgrenze "obere Drehzahlgrenze des Motors";
CM_ SG_ 1648 MO_StartStopp_PopUp "Das Signal zeigt an, ob der StSt-Status mittels Deaktivierungstaster geändert wurde. Ein Wechsel auf die Werte 01 oder 10 löst im Kombi ein entsprechendes PopUp aus. Bei einem Statuswechsel durch andere Signalquellen (z.B. Charisma, fehlerbedingte Abschal";
CM_ SG_ 1648 MO_Zylabsch_Texte "Zylinderabschaltung mode in Kombi, fuer Zylinderabschaltung";
CM_ SG_ 1648 MO_Zylabsch_Texte_02 "ZAS-Anzeige für den Fahrer im Kombi
0: kein ZAS (generell keinerlei ZAS-Anzeigen)  (Init für nicht ZAS-Motor)
1: ZAS im Vollmotorbetrieb  (Init für ZAS-Motor)
2: ZAS im Abschaltbetrieb: 1 Zyl aktiv
3: ZAS im Abschaltbetrieb: 2 Zyl aktiv
4: ZAS im Abs";

CM_ SG_ 289 MO_Entkopplung_Sollschlupf "MSG fordert von GSG an, das Anfahrelement (Fahr-/Wandlerkupplung) zu entkoppeln; das GSG soll die gesendete Drehzahl als Schlupf einstellen und ggf. die Regler-Parameter umschalten, damit Rucke aus dem Antrieb nicht im Fahrzeug spürbar werden; nutzbar z.B";
CM_ SG_ 289 MO_Fahrpedalgradient "Das Motorsteuergerät besitzt 2 analoge Fahrpedalsignale. Das Signal des ersten Kanals wird alle 4ms abgetastet. Um Bitschwankungen des A/D-Wandler herauszufiltern wird das Signal entjittert. Anschließend wird der Gradient berechnet. Entsprechend der Zyklu";
CM_ SG_ 289 MO_Fahrpedalrohwert_01 "AUDI D4: Zykluszeit: 10ms (siehe Zykluszeit schnell/Cycletime Fast)

Stellung des Fahrpedales (Rohwert, ohne Überlagerung durch GRA-Eingriffe etc.)

Die Funktionen zur Berechung des Fahrpedalrohwerts laufen im 10ms Raster. Der Fahrpedalwert berechnet ";
CM_ SG_ 289 MO_Moment_im_Leerlauf "Fahrerwunschmoment ist minimal: keine Momentenanforderung durch Fahrpedal, ACC oder GRA+; (Das Signal ist unabhängig von Momentenerhöhungen durch Leerlaufregler oder MSR).

AUDI D4: Zykluszeit: 10ms (siehe Zykluszeit schnell/Cycletime Fast)

Achtung:";
CM_ SG_ 289 MO_QBit_Fahrpedalwerte_01 "AUDI D4: Zykluszeit: 10ms (siehe Zykluszeit schnell/Cycletime Fast)

QBit für beide Fahrpedalwerte des Motors (Fahrpedalrohsignal für ESP, EPB, ACC; Fahrpedalwert für Getriebe)

Achtung:
Reduktion der Zykluszeit Motor_03 auf 10ms geplant.
Projektabh";
CM_ SG_ 289 MO_rel_Saugrohrdruck "Der Wert gibt an, um wieviel mbar der Saugrohrdruck unterhalb des Umgebungsdrucks liegt. Überdruck im Saugrohr wird nicht ausgegeben.
0: Saugrohrdruck=Umgebungsdruck";
CM_ SG_ 289 MO_rel_Saugrohrdruck_gem_err "0: mind. eine Modellrechnung wird zur Berechnung des relativen Saugdrucks herangezogen
1: Relativer Saugrohrdruck wird ausschließlich über Messgrößen bestimmt";
CM_ SG_ 289 MO_Schubabschaltung "ESP plausibilisiert Unterdrucksensor nur bei aktiver Schubabschaltung

MLBevo:
Signal wird nur in MLBevo Projekten mit PDKII Getriebe bedient. In allen anderen MLBevo Projekten wird das Signal mit '0' bedient
PDKII berücksichtigt Verzugszeiten, die in";
CM_ SG_ 289 MO_Sig_Fahrpedalgradient "Kennzeichnet das Vorzeichen des Signal 'Fahrpedalgradient'. Die Ausgabe erfolgt nur parallel statisch mit gesendetem Signal: 'Steuerungsbit Fahrpedalgradient' ";
CM_ SG_ 289 MO_Solldrehz_Leerlauf "Leerlaufsolldrehzahl, die im Motor eingestellt ist (Bei Parallelhybrid im E-Fahr-Betrieb Leerlaufsolldrehzahl der E-Maschine). Der Motor paßt aufgrund der Anforderung von anderen Steuergeräten seine Leerlaufsolldrehzahl an, bspw. Kat-Heizen, Anforderung v";
CM_ SG_ 289 MO_StartStopp_StoppVorbereitung "Zeigt allen aktiven Start-/Stoppteilnehmern einen möglichen Motorstopp im Anhaltevorgang an (Empfänger notwendige Vorbereitungen treffen)
Es liegen keine Vetos vor.";
CM_ SG_ 289 MO_temporaere_Fahrerabwesenheit "Das Signal dient zur Signalisierung einer temporären Abwesenheit des Fahrers. In dieser Zeit ist es ihm möglich, sich durch gewisse ¿ im Verlassenskonzept definierte ¿ Fahreraktionen im aktuellen Fahrzyklus zurückzumelden.
Das Signal wird gesetzt, sobald";
CM_ SG_ 289 Motor_20_BZ "Botschaft asynchron geroutet. Zählerwert kann springen.";
CM_ SG_ 289 Motor_20_CRC "Für MLB:
'Berechnung siehe Lastenheft 'Kommunikationsabsicherung für FlexRay und CAN''

Ab MQB und MLBevo:
'Berechnung siehe Lastenheft 'End-to-End Kommunikationsabsicherung'

Endwerte siehe Begleitdokument 'S-PDU Kennungsfolgen'";
CM_ SG_ 289 TSK_a_Soll_gradientenbegrenzt "TSK Sollbeschleunigung für Fahrerassistenzsysteme mit aktiver Längsführung (GRA, ACC, IPA...). Der Wert stellt den ruckbegrenzten Sollwert der TSK-Regelung dar und ist Basis der TSK-Antriebs- und Bremsmomentenvorsteuerung.";

CM_ SG_ 1654 MO_StaGluehk "Einschaltzustand der Gluehkerzenheizung in Prozent";
CM_ SG_ 1654 MO_Stoppverbot_Anz_01 "Dieses Signal gibt die detaillierte Begründung für ein Stoppverbot vom Motor an.";
CM_ SG_ 1654 MO_Stoppverbot_Anz_02 "Dieses Signal gibt die detaillierte Begründung für ein Stoppverbot vom Motor an.";
CM_ SG_ 1654 MO_Stoppverbot_Anz_03 "Dieses Signal gibt die detaillierte Begründung für ein Stoppverbot vom Motor an.";
CM_ SG_ 1654 MO_Stoppverbot_Anz_04 "Dieses Signal gibt die detaillierte Begründung für ein Stoppverbot vom Motor an.";
CM_ SG_ 1654 MO_Stoppverbot_Anz_05 "Dieses Signal gibt die detaillierte Begründung für ein Stoppverbot vom Motor an.";
CM_ SG_ 1654 MO_Stoppverbot_Anz_06 "Dieses Signal gibt die detaillierte Begründung für ein Stoppverbot vom Motor an.";
CM_ SG_ 1654 MO_Stoppverbot_Anz_07 "Dieses Signal gibt die detaillierte Begründung für ein Stoppverbot vom Motor an.";
CM_ SG_ 1654 MO_Stoppverbot_Anz_08 "Dieses Signal gibt die detaillierte Begründung für ein Stoppverbot vom Motor an.";
CM_ SG_ 1654 MO_Stoppverbot_Anz_09 "Dieses Signal gibt die detaillierte Begründung für ein Stoppverbot vom Motor an.";
CM_ SG_ 1654 MO_Stoppverbot_Anz_10 "Dieses Signal gibt die detaillierte Begründung für ein Stoppverbot vom Motor an.";
CM_ SG_ 1654 MO_Stoppverbot_Anz_11 "Dieses Signal gibt die detaillierte Begründung für ein Stoppverbot vom Motor an.";
CM_ SG_ 1654 MO_Stoppverbot_Anz_Std "Dieses Signal gibt die detaillierte Begründung für ein Stoppverbot vom Motor an.";
CM_ SG_ 1654 MO_Wiederstart_Anz_01 "Dieses Signal gibt die detaillierte Begründung für eine Wiederstartanforderung vom Motor an.";
CM_ SG_ 1654 MO_Wiederstart_Anz_02 "Dieses Signal gibt die detaillierte Begründung für eine Wiederstartanforderung vom Motor an.";
CM_ SG_ 1654 MO_Wiederstart_Anz_03 "Dieses Signal gibt die detaillierte Begründung für eine Wiederstartanforderung vom Motor an.";
CM_ SG_ 1654 MO_Wiederstart_Anz_Std "Dieses Signal gibt die detaillierte Begründung für eine Wiederstartanforderung vom Motor an.";
CM_ SG_ 1654 StSt_Koord_Status_Bremspedalkzpt "Dieses Signal gibt die Information, ob das Bremspedalkonzept (Startanforderung Automat) aktiv ist oder nicht.";
CM_ SG_ 1654 StSt_Koord_Stoppverbot_Anz_01 "Dieses Signal gibt die detaillierte Begründung für ein Stoppverbot vom StartStop Koordinator an.";
CM_ SG_ 1654 StSt_Koord_Stoppverbot_Anz_02 "Dieses Signal gibt die detaillierte Begründung für ein Stoppverbot vom StartStop Koordinator an.";
CM_ SG_ 1654 StSt_Koord_Stoppverbot_Anz_03 "Dieses Signal gibt die detaillierte Begründung für ein Stoppverbot vom StartStop Koordinator an.";
CM_ SG_ 1654 StSt_Koord_Stoppverbot_Anz_04 "Dieses Signal gibt die detaillierte Begründung für ein Stoppverbot vom StartStop Koordinator an.";
CM_ SG_ 1654 StSt_Koord_Stoppverbot_Anz_05 "Dieses Signal gibt die detaillierte Begründung für ein Stoppverbot vom StartStop Koordinator an.";
CM_ SG_ 1654 StSt_Koord_Stoppverbot_Anz_06 "Dieses Signal gibt die detaillierte Begründung für ein Stoppverbot vom StartStop Koordinator an.";
CM_ SG_ 1654 StSt_Koord_Stoppverbot_Anz_07 "Dieses Signal gibt die detaillierte Begründung für ein Stoppverbot vom StartStop Koordinator an.";
CM_ SG_ 1654 StSt_Koord_Stoppverbot_Anz_08 "Dieses Signal gibt die detaillierte Begründung für ein Stoppverbot vom StartStop Koordinator an.";
CM_ SG_ 1654 StSt_Koord_Stoppverbot_Anz_09 "Dieses Signal gibt die detaillierte Begründung für ein Stoppverbot vom StartStop Koordinator an.";
CM_ SG_ 1654 StSt_Koord_Stoppverbot_Anz_10 "Dieses Signal gibt die detaillierte Begründung für ein Stoppverbot vom StartStop Koordinator an.";
CM_ SG_ 1654 StSt_Koord_Stoppverbot_Anz_11 "Dieses Signal gibt die detaillierte Begründung für ein Stoppverbot vom StartStop Koordinator an.";
CM_ SG_ 1654 StSt_Koord_Stoppverbot_Anz_12 "Dieses Signal gibt die detaillierte Begründung für ein Stoppverbot vom StartStop Koordinator an.";
CM_ SG_ 1654 StSt_Koord_Stoppverbot_Anz_13 "Dieses Signal gibt die detaillierte Begründung für ein Stoppverbot vom StartStop Koordinator an.";
CM_ SG_ 1654 StSt_Koord_Stoppverbot_Anz_14 "Dieses Signal gibt die detaillierte Begründung für ein Stoppverbot vom StartStop Koordinator an.";
CM_ SG_ 1654 StSt_Koord_Stoppverbot_Anz_15 "Dieses Signal gibt die detaillierte Begründung für ein Stoppverbot vom StartStop Koordinator an.";
CM_ SG_ 1654 StSt_Koord_Stoppverbot_Anz_16 "Dieses Signal gibt die detaillierte Begründung für ein Stoppverbot vom StartStop Koordinator an.";
CM_ SG_ 1654 StSt_Koord_Stoppverbot_Anz_17 "Dieses Signal beinhaltet die Information, ob für einen Motorstopp eine weitere Fahrerbedienhandlung (z. B. Kupplung lösen) nötig ist.

0 = Motorstopp nicht durch Fahrerhandlung verhindert
1 = fehlende Fahrerhandlung verhindert Motorstopp";
CM_ SG_ 1654 StSt_Koord_Stoppverbot_Anz_18 "Dieses Signal beinhaltet die Information, dass ein Motorlauf wg. PSD notwendig ist.

0 = Motorstopp nicht durch PSD verhindert
1 = PSD verhindert Motorstopp";
CM_ SG_ 1654 StSt_Koord_Stoppverbot_Anz_19 "Dieses Signal beinhaltet die Information, dass ein Motorlauf wg. Kurzstopperkennung notwendig ist.

0 = Motorstopp nicht durch Kurzstopperkennung verhindert
1 = Kurzstopperkennung verhindert Motorstopp";
CM_ SG_ 1654 StSt_Koord_Stoppverbot_Anz_20 "Dieses Signal beinhaltet die Information, dass ein Motorlauf wg. Ampelinfo-Online notwendig ist.

0 = Motorstopp nicht durch Ampelinfo-Online verhindert
1 = Ampelinfo-Online verhindert Motorstopp";
CM_ SG_ 1654 StSt_Koord_Stoppverbot_Anz_21 "Dieses Signal beinhaltet die Information, dass ein Motorlauf wg. RaceMode, S oder Tipp notwendig ist

0 = Motorstopp nicht durch RaceMode, S oder Tipp verhindert
1 = RaceMode, S oder Tipp verhindert Motorstopp";
CM_ SG_ 1654 StSt_Koord_Stoppverbot_Anz_Std "Dieses Signal gibt die detaillierte Begründung für ein Stoppverbot vom StartStop Koordinator an.";
CM_ SG_ 1654 StSt_Koord_Wiederstart_Anz_01 "Dieses Signal gibt die detaillierte Begründung für eine Wiederstartanforderung vom StartStop Koordinator an.";
CM_ SG_ 1654 StSt_Koord_Wiederstart_Anz_02 "Dieses Signal gibt die detaillierte Begründung für eine Wiederstartanforderung vom StartStop Koordinator an.";
CM_ SG_ 1654 StSt_Koord_Wiederstart_Anz_03 "Dieses Signal gibt die detaillierte Begründung für eine Wiederstartanforderung vom StartStop Koordinator an.";
CM_ SG_ 1654 StSt_Koord_Wiederstart_Anz_04 "Dieses Signal gibt die detaillierte Begründung für eine Wiederstartanforderung vom StartStop Koordinator an.";
CM_ SG_ 1654 StSt_Koord_Wiederstart_Anz_05 "Dieses Signal gibt die detaillierte Begründung für eine Wiederstartanforderung vom StartStop Koordinator an.";
CM_ SG_ 1654 StSt_Koord_Wiederstart_Anz_06 "Dieses Signal gibt die detaillierte Begründung für eine Wiederstartanforderung vom StartStop Koordinator an.";
CM_ SG_ 1654 StSt_Koord_Wiederstart_Anz_07 "Dieses Signal gibt die detaillierte Begründung für eine Wiederstartanforderung vom StartStop Koordinator an.";
CM_ SG_ 1654 StSt_Koord_Wiederstart_Anz_08 "Dieses Signal gibt die detaillierte Begründung für eine Wiederstartanforderung vom StartStop Koordinator an.";
CM_ SG_ 1654 StSt_Koord_Wiederstart_Anz_09 "Dieses Signal gibt die detaillierte Begründung für eine Wiederstartanforderung vom StartStop Koordinator an.";
CM_ SG_ 1654 StSt_Koord_Wiederstart_Anz_10 "Dieses Signal gibt die detaillierte Begründung für eine Wiederstartanforderung vom StartStop Koordinator an.";
CM_ SG_ 1654 StSt_Koord_Wiederstart_Anz_11 "Dieses Signal gibt die detaillierte Begründung für eine Wiederstartanforderung vom StartStop Koordinator an.";
CM_ SG_ 1654 StSt_Koord_Wiederstart_Anz_Std "Dieses Signal gibt die detaillierte Begründung für eine Wiederstartanforderung vom StartStop Koordinator an.";
BA_DEF_REL_ BU_SG_REL_  "GenSigTimeoutTime" INT 0 65535;
BA_DEF_ BO_  "DiagRequest" ENUM "No", "Yes";
BA_DEF_ BO_  "DiagResponse" ENUM "No", "Yes";
BA_DEF_ BO_  "DiagState" ENUM "No", "Yes";
BA_DEF_ BO_  "GenMsgChkConstant" HEX 0 4095;
BA_DEF_ BO_  "GenMsgCycleTime" INT 0 65535;
BA_DEF_ BO_  "GenMsgCycleTimeFast" INT 0 65535;
BA_DEF_ BO_  "GenMsgDelayTime" INT 0 100000;
BA_DEF_ BO_  "GenMsgILSupport" ENUM "No", "Yes";
BA_DEF_ BO_  "GenMsgNrOfRepetition" INT 0 100;
BA_DEF_ BO_  "GenMsgPDUConstants" STRING;
BA_DEF_ BO_  "GenMsgSendType" ENUM "Cyclic", "not_used", "not_used", "not_used", "not_used", "not_used", "not_used", "IfActive", "NoMsgSendType";
BA_DEF_ BO_  "GenMsgStartDelayTime" INT 0 100000;
BA_DEF_ BO_  "NmMessage" ENUM "No", "Yes";
BA_DEF_ BO_  "NmhMessage" ENUM "No", "Yes";
BA_DEF_ BO_  "MsgType" ENUM "Application", "NM ", "NMH", "TP2.0", "ISO-TP ", "BAP", "EID", "KS", "XCP_PRE_CONFIGURED", "XCP_RUNTIME_CONFIGURED";
BA_DEF_ BO_  "VAGTP20_API" HEX 0 255;
BA_DEF_ BO_  "VAGTP20_DynConnection" ENUM "No", "Yes";
BA_DEF_ BO_  "VAGTP20_DynSetup" ENUM "No", "Yes";
BA_DEF_ BO_  "VAGTP20_StatConnection" ENUM "No", "Yes";
BA_DEF_ SG_  "GenSigActiveRepetitions" INT -2147483648 2147483647;
BA_DEF_ SG_  "GenSigInactiveValue" INT -2147483648 2147483647;
BA_DEF_ SG_  "GenSigSendType" ENUM "Cyclic", "OnWrite", "OnWriteWithRepetition", "OnChange", "OnChangeWithRepetition", "IfActive", "IfActiveWithRepetition", "NoSigSendType", "OnChangeAndIfActive", "OnChangeAndIfActiveWithRepetition";
BA_DEF_ SG_  "GenSigStartValue" INT -2147483648 2147483647;
BA_DEF_ SG_  "NWM-WakeupAllowed" ENUM "No", "Yes";
BA_DEF_ SG_  "GenSigFuncType" ENUM "NoFunction", "MsgCounter", "CRC-8", "XOR", "XOR-2", "DatedBit", "SW-Kl15", "CHK", "Constant", "Protocol", "CRC-8-SAE_J1850", "CRC-32", "DataLength", "DataID", "MsgCounter16", "SOK-Signatur", "Cluster";
BA_DEF_ SG_  "GenSigSwitchedByIgnition" ENUM "No", "Yes";
BA_DEF_ SG_  "Fehlerwert" HEX 0 2147483647;
BA_DEF_ SG_  "GenSigMissingSourceValue" HEX 0 2147483647;
BA_DEF_DEF_REL_  "GenSigTimeoutTime" 0;
BA_DEF_DEF_  "DiagRequest" "No";
BA_DEF_DEF_  "DiagResponse" "No";
BA_DEF_DEF_  "DiagState" "No";
BA_DEF_DEF_  "GenMsgChkConstant" 0;
BA_DEF_DEF_  "GenMsgCycleTime" 0;
BA_DEF_DEF_  "GenMsgCycleTimeFast" 0;
BA_DEF_DEF_  "GenMsgDelayTime" 0;
BA_DEF_DEF_  "GenMsgILSupport" "No";
BA_DEF_DEF_  "GenMsgNrOfRepetition" 0;
BA_DEF_DEF_  "GenMsgPDUConstants" "";
BA_DEF_DEF_  "GenMsgSendType" "NoMsgSendType";
BA_DEF_DEF_  "GenMsgStartDelayTime" 0;
BA_DEF_DEF_  "NmMessage" "No";
BA_DEF_DEF_  "NmhMessage" "No";
BA_DEF_DEF_  "MsgType" "Application";
BA_DEF_DEF_  "VAGTP20_API" 0;
BA_DEF_DEF_  "VAGTP20_DynConnection" "No";
BA_DEF_DEF_  "VAGTP20_DynSetup" "No";
BA_DEF_DEF_  "VAGTP20_StatConnection" "No";
BA_DEF_DEF_  "GenSigActiveRepetitions" 0;
BA_DEF_DEF_  "GenSigInactiveValue" 0;
BA_DEF_DEF_  "GenSigSendType" "NoSigSendType";
BA_DEF_DEF_  "GenSigStartValue" 0;
BA_DEF_DEF_  "NWM-WakeupAllowed" "No";
BA_DEF_DEF_  "GenSigFuncType" "NoFunction";
BA_DEF_DEF_  "GenSigSwitchedByIgnition" "Yes";
BA_DEF_DEF_  "Fehlerwert" 0;
BA_DEF_DEF_  "GenSigMissingSourceValue" 0;
BA_ "GenMsgCycleTime" BO_ 1178 100;
BA_ "GenMsgDelayTime" BO_ 1178 50;
BA_ "GenMsgILSupport" BO_ 1178 1;
BA_ "GenMsgSendType" BO_ 1178 0;
BA_ "GenMsgCycleTime" BO_ 954 100;
BA_ "GenMsgDelayTime" BO_ 954 50;
BA_ "GenMsgILSupport" BO_ 954 1;
BA_ "GenMsgSendType" BO_ 954 0;
BA_ "GenMsgCycleTime" BO_ 956 100;
BA_ "GenMsgDelayTime" BO_ 956 50;
BA_ "GenMsgILSupport" BO_ 956 1;
BA_ "GenMsgSendType" BO_ 956 0;
BA_ "GenMsgChkConstant" BO_ 1180 152;
BA_ "GenMsgCycleTime" BO_ 1180 100;
BA_ "GenMsgCycleTimeFast" BO_ 1180 50;
BA_ "GenMsgDelayTime" BO_ 1180 30;
BA_ "GenMsgILSupport" BO_ 1180 1;
BA_ "GenMsgNrOfRepetition" BO_ 1180 6;
BA_ "GenMsgPDUConstants" BO_ 1180 "0x98,0x98,0x98,0x98,0x98,0x98,0x98,0x98,0x98,0x98,0x98,0x98,0x98,0x98,0x98,0x98";
BA_ "GenMsgSendType" BO_ 1180 0;
BA_ "GenMsgChkConstant" BO_ 1170 150;
BA_ "GenMsgCycleTime" BO_ 1170 100;
BA_ "GenMsgCycleTimeFast" BO_ 1170 50;
BA_ "GenMsgDelayTime" BO_ 1170 30;
BA_ "GenMsgILSupport" BO_ 1170 1;
BA_ "GenMsgNrOfRepetition" BO_ 1170 6;
BA_ "GenMsgPDUConstants" BO_ 1170 "0x96,0x96,0x96,0x96,0x96,0x96,0x96,0x96,0x96,0x96,0x96,0x96,0x96,0x96,0x96,0x96";
BA_ "GenMsgSendType" BO_ 1170 0;
BA_ "GenMsgChkConstant" BO_ 1173 145;
BA_ "GenMsgCycleTime" BO_ 1173 100;
BA_ "GenMsgILSupport" BO_ 1173 1;
BA_ "GenMsgPDUConstants" BO_ 1173 "0x91,0x91,0x91,0x91,0x91,0x91,0x91,0x91,0x91,0x91,0x91,0x91,0x91,0x91,0x91,0x91";
BA_ "GenMsgSendType" BO_ 1173 0;
BA_ "GenMsgCycleTime" BO_ 817 500;
BA_ "GenMsgCycleTimeFast" BO_ 817 30;
BA_ "GenMsgILSupport" BO_ 817 1;
BA_ "GenMsgSendType" BO_ 817 0;
BA_ "GenMsgDelayTime" BO_ 1471 20;
BA_ "GenMsgILSupport" BO_ 1471 1;
BA_ "GenMsgStartDelayTime" BO_ 1471 15;
BA_ "GenMsgCycleTime" BO_ 2463978670 150;
BA_ "GenMsgILSupport" BO_ 2463978670 1;
BA_ "GenMsgSendType" BO_ 2463978670 0;
BA_ "GenMsgCycleTime" BO_ 263 20;
BA_ "GenMsgILSupport" BO_ 263 1;
BA_ "GenMsgSendType" BO_ 263 0;
BA_ "GenMsgCycleTime" BO_ 1600 320;
BA_ "GenMsgILSupport" BO_ 1600 1;
BA_ "GenMsgSendType" BO_ 1600 0;
BA_ "GenMsgCycleTime" BO_ 1607 320;
BA_ "GenMsgILSupport" BO_ 1607 1;
BA_ "GenMsgSendType" BO_ 1607 0;
BA_ "GenMsgCycleTime" BO_ 167 200;
BA_ "GenMsgILSupport" BO_ 167 1;
BA_ "GenMsgPDUConstants" BO_ 167 "0xd2,0x3d,0xcd,0x28,0x4c,0x14,0x22,0x4b,0x24,0xac,0xfa,0x55,0x66,0x80,0x0d,0x6c";
BA_ "GenMsgSendType" BO_ 167 0;
BA_ "GenMsgCycleTime" BO_ 168 10;
BA_ "GenMsgILSupport" BO_ 168 1;
BA_ "GenMsgPDUConstants" BO_ 168 "0x52,0x8c,0x50,0xee,0x4f,0xa6,0xcc,0xcf,0x7d,0x2f,0x98,0x6b,0x27,0x41,0x9f,0x93";
BA_ "GenMsgSendType" BO_ 168 0;
BA_ "GenMsgCycleTime" BO_ 958 100;
BA_ "GenMsgDelayTime" BO_ 958 10;
BA_ "GenMsgILSupport" BO_ 958 1;
BA_ "GenMsgPDUConstants" BO_ 958 "0x1f,0x28,0xc6,0x85,0xe6,0xf8,0xb0,0x19,0x5b,0x64,0x35,0x21,0xe4,0xf7,0x9c,0x24";
BA_ "GenMsgSendType" BO_ 958 0;
BA_ "GenMsgCycleTime" BO_ 1631 320;
BA_ "GenMsgILSupport" BO_ 1631 1;
BA_ "GenMsgSendType" BO_ 1631 0;
BA_ "GenMsgCycleTime" BO_ 1648 500;
BA_ "GenMsgDelayTime" BO_ 1648 20;
BA_ "GenMsgILSupport" BO_ 1648 1;
BA_ "GenMsgSendType" BO_ 1648 0;
BA_ "GenMsgCycleTime" BO_ 289 200;
BA_ "GenMsgILSupport" BO_ 289 1;
BA_ "GenMsgPDUConstants" BO_ 289 "0xe9,0x65,0xae,0x6b,0x7b,0x35,0xe5,0x5f,0x4e,0xc7,0x86,0xa2,0xbb,0xdd,0xeb,0xb4";
BA_ "GenMsgSendType" BO_ 289 0;
BA_ "GenMsgCycleTime" BO_ 1654 960;
BA_ "GenMsgDelayTime" BO_ 1654 160;
BA_ "GenMsgILSupport" BO_ 1654 1;
BA_ "GenMsgSendType" BO_ 1654 0;
BA_ "GenSigSendType" SG_ 1178 FS_BFS_Fond_Verst_enable 3;
BA_ "GenSigSwitchedByIgnition" SG_ 1178 FS_BFS_Fond_Verst_enable 0;
BA_ "GenSigSendType" SG_ 1178 FS_BFS_KSS_Anfahrt 3;
BA_ "GenSigSwitchedByIgnition" SG_ 1178 FS_BFS_KSS_Anfahrt 0;
BA_ "GenSigSendType" SG_ 1178 FS_BFS_Sitzsym_Anfahrt 3;
BA_ "GenSigSwitchedByIgnition" SG_ 1178 FS_BFS_Sitzsym_Anfahrt 0;
BA_ "GenSigSendType" SG_ 1178 FS_EE_BFS_enable 3;
BA_ "GenSigSwitchedByIgnition" SG_ 1178 FS_EE_BFS_enable 0;
BA_ "GenSigSendType" SG_ 1178 FS_EE_Fond_BFS_enable 3;
BA_ "GenSigSwitchedByIgnition" SG_ 1178 FS_EE_Fond_BFS_enable 0;
BA_ "GenSigSendType" SG_ 1178 FS_EE_Fond_FS_enable 3;
BA_ "GenSigSwitchedByIgnition" SG_ 1178 FS_EE_Fond_FS_enable 0;
BA_ "GenSigSendType" SG_ 1178 FS_Fond_Bed_enable 3;
BA_ "GenSigSwitchedByIgnition" SG_ 1178 FS_Fond_Bed_enable 0;
BA_ "GenSigSendType" SG_ 1178 FS_GHV_aktiv 3;
BA_ "GenSigSwitchedByIgnition" SG_ 1178 FS_GHV_aktiv 0;
BA_ "GenSigSendType" SG_ 1178 FS_Gurtbringer_Sperre 0;
BA_ "GenSigSwitchedByIgnition" SG_ 1178 FS_Gurtbringer_Sperre 0;
BA_ "GenSigSendType" SG_ 1178 FS_Kollisionsbereich_Windschott 3;
BA_ "GenSigSwitchedByIgnition" SG_ 1178 FS_Kollisionsbereich_Windschott 0;
BA_ "GenSigSendType" SG_ 1178 FS_Kollisionsgefahr_Windschott 3;
BA_ "GenSigSwitchedByIgnition" SG_ 1178 FS_Kollisionsgefahr_Windschott 0;
BA_ "GenSigSendType" SG_ 1178 FS_KSV_aktiv 3;
BA_ "GenSigSwitchedByIgnition" SG_ 1178 FS_KSV_aktiv 0;
BA_ "GenSigSendType" SG_ 1178 FS_Lehne_nicht_verriegelt 3;
BA_ "GenSigSwitchedByIgnition" SG_ 1178 FS_Lehne_nicht_verriegelt 0;
BA_ "GenSigSendType" SG_ 1178 FS_LHV_aktiv 3;
BA_ "GenSigSwitchedByIgnition" SG_ 1178 FS_LHV_aktiv 0;
BA_ "GenSigSendType" SG_ 1178 FS_LKV_aktiv 3;
BA_ "GenSigSwitchedByIgnition" SG_ 1178 FS_LKV_aktiv 0;
BA_ "GenSigSendType" SG_ 1178 FS_LNV_aktiv 3;
BA_ "GenSigSwitchedByIgnition" SG_ 1178 FS_LNV_aktiv 0;
BA_ "GenSigSendType" SG_ 1178 FS_LWV_aktiv 3;
BA_ "GenSigSwitchedByIgnition" SG_ 1178 FS_LWV_aktiv 0;
BA_ "GenSigSendType" SG_ 1178 FS_MMB_glob_stop 3;
BA_ "GenSigSwitchedByIgnition" SG_ 1178 FS_MMB_glob_stop 0;
BA_ "GenSigSendType" SG_ 1178 FS_MMB_lokal_Stop 3;
BA_ "GenSigSwitchedByIgnition" SG_ 1178 FS_MMB_lokal_Stop 0;
BA_ "GenSigSendType" SG_ 1178 FS_MMB_storage 3;
BA_ "GenSigSwitchedByIgnition" SG_ 1178 FS_MMB_storage 0;
BA_ "GenSigSendType" SG_ 1178 FS_MMB_storage_beep 3;
BA_ "GenSigSwitchedByIgnition" SG_ 1178 FS_MMB_storage_beep 0;
BA_ "GenSigSendType" SG_ 1178 FS_MMB_store 3;
BA_ "GenSigSwitchedByIgnition" SG_ 1178 FS_MMB_store 0;
BA_ "GenSigSendType" SG_ 1178 FS_MMB_store_LED_on 3;
BA_ "GenSigSwitchedByIgnition" SG_ 1178 FS_MMB_store_LED_on 0;
BA_ "GenSigSendType" SG_ 1178 FS_MMB_tast 3;
BA_ "GenSigSwitchedByIgnition" SG_ 1178 FS_MMB_tast 0;
BA_ "GenSigSendType" SG_ 1178 FS_MMB_tipp 3;
BA_ "GenSigSwitchedByIgnition" SG_ 1178 FS_MMB_tipp 0;
BA_ "GenSigSendType" SG_ 1178 FS_NFA_einfahren 3;
BA_ "GenSigSwitchedByIgnition" SG_ 1178 FS_NFA_einfahren 0;
BA_ "GenSigSendType" SG_ 1178 FS_SHV_aktiv 3;
BA_ "GenSigSwitchedByIgnition" SG_ 1178 FS_SHV_aktiv 0;
BA_ "GenSigSendType" SG_ 1178 FS_Sitzfahrt_aktiv 3;
BA_ "GenSigSwitchedByIgnition" SG_ 1178 FS_Sitzfahrt_aktiv 0;
BA_ "GenSigSendType" SG_ 1178 FS_SLV_aktiv 3;
BA_ "GenSigSwitchedByIgnition" SG_ 1178 FS_SLV_aktiv 0;
BA_ "GenSigSendType" SG_ 1178 FS_SNV_aktiv 3;
BA_ "GenSigSwitchedByIgnition" SG_ 1178 FS_SNV_aktiv 0;
BA_ "GenSigSendType" SG_ 1178 FS_Spezialposition_anfahren 3;
BA_ "GenSigSwitchedByIgnition" SG_ 1178 FS_Spezialposition_anfahren 0;
BA_ "GenSigSendType" SG_ 1178 FS_STV_aktiv 3;
BA_ "GenSigSwitchedByIgnition" SG_ 1178 FS_STV_aktiv 0;
BA_ "GenSigSendType" SG_ 954 FS_BFS_aufraeumen 3;
BA_ "GenSigSwitchedByIgnition" SG_ 954 FS_BFS_aufraeumen 0;
BA_ "GenSigSendType" SG_ 954 FS_BFSFo_aufraeumen 3;
BA_ "GenSigSwitchedByIgnition" SG_ 954 FS_BFSFo_aufraeumen 0;
BA_ "GenSigSendType" SG_ 954 FS_FSFo_aufraeumen 3;
BA_ "GenSigSwitchedByIgnition" SG_ 954 FS_FSFo_aufraeumen 0;
BA_ "GenSigSendType" SG_ 954 FS_MMB_Sys_Fahrt_aktiv 3;
BA_ "GenSigSwitchedByIgnition" SG_ 954 FS_MMB_Sys_Fahrt_aktiv 0;
BA_ "GenSigSendType" SG_ 954 FS_Remote_KSV_Taste_hoch 3;
BA_ "GenSigSwitchedByIgnition" SG_ 954 FS_Remote_KSV_Taste_hoch 0;
BA_ "GenSigSendType" SG_ 954 FS_Remote_KSV_Taste_tief 3;
BA_ "GenSigSwitchedByIgnition" SG_ 954 FS_Remote_KSV_Taste_tief 0;
BA_ "GenSigSendType" SG_ 954 FS_Remote_KSV_Taste_vor 3;
BA_ "GenSigSwitchedByIgnition" SG_ 954 FS_Remote_KSV_Taste_vor 0;
BA_ "GenSigSendType" SG_ 954 FS_Remote_KSV_Taste_zurueck 3;
BA_ "GenSigSwitchedByIgnition" SG_ 954 FS_Remote_KSV_Taste_zurueck 0;
BA_ "GenSigSendType" SG_ 954 FS_Remote_LKV_Taste_vor 3;
BA_ "GenSigSwitchedByIgnition" SG_ 954 FS_Remote_LKV_Taste_vor 0;
BA_ "GenSigSendType" SG_ 954 FS_Remote_LKV_Taste_zurueck 3;
BA_ "GenSigSwitchedByIgnition" SG_ 954 FS_Remote_LKV_Taste_zurueck 0;
BA_ "GenSigSendType" SG_ 954 FS_Remote_LNV_Taste_vor 3;
BA_ "GenSigSwitchedByIgnition" SG_ 954 FS_Remote_LNV_Taste_vor 0;
BA_ "GenSigSendType" SG_ 954 FS_Remote_LNV_Taste_zurueck 3;
BA_ "GenSigSwitchedByIgnition" SG_ 954 FS_Remote_LNV_Taste_zurueck 0;
BA_ "GenSigSendType" SG_ 954 FS_Remote_LWV_Taste_breit 3;
BA_ "GenSigSwitchedByIgnition" SG_ 954 FS_Remote_LWV_Taste_breit 0;
BA_ "GenSigSendType" SG_ 954 FS_Remote_LWV_Taste_eng 3;
BA_ "GenSigSwitchedByIgnition" SG_ 954 FS_Remote_LWV_Taste_eng 0;
BA_ "GenSigSendType" SG_ 954 FS_Remote_Massage_Taste 3;
BA_ "GenSigSwitchedByIgnition" SG_ 954 FS_Remote_Massage_Taste 0;
BA_ "GenSigSendType" SG_ 954 FS_Remote_Multif_Taster_hoch 3;
BA_ "GenSigSwitchedByIgnition" SG_ 954 FS_Remote_Multif_Taster_hoch 0;
BA_ "GenSigSendType" SG_ 954 FS_Remote_Multif_Taster_tief 3;
BA_ "GenSigSwitchedByIgnition" SG_ 954 FS_Remote_Multif_Taster_tief 0;
BA_ "GenSigSendType" SG_ 954 FS_Remote_Multif_Taster_vor 3;
BA_ "GenSigSwitchedByIgnition" SG_ 954 FS_Remote_Multif_Taster_vor 0;
BA_ "GenSigSendType" SG_ 954 FS_Remote_Multif_Taster_zurueck 3;
BA_ "GenSigSwitchedByIgnition" SG_ 954 FS_Remote_Multif_Taster_zurueck 0;
BA_ "GenSigSendType" SG_ 954 FS_Remote_Programmwippe_hoch 3;
BA_ "GenSigSwitchedByIgnition" SG_ 954 FS_Remote_Programmwippe_hoch 0;
BA_ "GenSigSendType" SG_ 954 FS_Remote_Programmwippe_tief 3;
BA_ "GenSigSwitchedByIgnition" SG_ 954 FS_Remote_Programmwippe_tief 0;
BA_ "GenSigSendType" SG_ 954 FS_Remote_SHV_Taste_hoch 3;
BA_ "GenSigSwitchedByIgnition" SG_ 954 FS_Remote_SHV_Taste_hoch 0;
BA_ "GenSigSendType" SG_ 954 FS_Remote_SHV_Taste_tief 3;
BA_ "GenSigSwitchedByIgnition" SG_ 954 FS_Remote_SHV_Taste_tief 0;
BA_ "GenSigSendType" SG_ 954 FS_Remote_SLV_Taste_vor 3;
BA_ "GenSigSwitchedByIgnition" SG_ 954 FS_Remote_SLV_Taste_vor 0;
BA_ "GenSigSendType" SG_ 954 FS_Remote_SLV_Taste_zurueck 3;
BA_ "GenSigSwitchedByIgnition" SG_ 954 FS_Remote_SLV_Taste_zurueck 0;
BA_ "GenSigSendType" SG_ 954 FS_Remote_SNV_Taste_hoch 3;
BA_ "GenSigSwitchedByIgnition" SG_ 954 FS_Remote_SNV_Taste_hoch 0;
BA_ "GenSigSendType" SG_ 954 FS_Remote_SNV_Taste_tief 3;
BA_ "GenSigSwitchedByIgnition" SG_ 954 FS_Remote_SNV_Taste_tief 0;
BA_ "GenSigSendType" SG_ 954 FS_Remote_STV_Taste_vor 3;
BA_ "GenSigSwitchedByIgnition" SG_ 954 FS_Remote_STV_Taste_vor 0;
BA_ "GenSigSendType" SG_ 954 FS_Remote_STV_Taste_zurueck 3;
BA_ "GenSigSwitchedByIgnition" SG_ 954 FS_Remote_STV_Taste_zurueck 0;
BA_ "GenSigSendType" SG_ 954 FS_Remote_SWV_Taste_breit 3;
BA_ "GenSigSwitchedByIgnition" SG_ 954 FS_Remote_SWV_Taste_breit 0;
BA_ "GenSigSendType" SG_ 954 FS_Remote_SWV_Taste_eng 3;
BA_ "GenSigSwitchedByIgnition" SG_ 954 FS_Remote_SWV_Taste_eng 0;
BA_ "GenSigSendType" SG_ 954 FS_RemoteTarget 3;
BA_ "GenSigSwitchedByIgnition" SG_ 954 FS_RemoteTarget 0;
BA_ "GenSigSendType" SG_ 954 Mem_FS_Lordose_hoch 3;
BA_ "GenSigSwitchedByIgnition" SG_ 954 Mem_FS_Lordose_hoch 0;
BA_ "GenSigSendType" SG_ 954 Mem_FS_Lordose_runter 3;
BA_ "GenSigSwitchedByIgnition" SG_ 954 Mem_FS_Lordose_runter 0;
BA_ "GenSigSendType" SG_ 954 Mem_FS_Lordose_vor 3;
BA_ "GenSigSwitchedByIgnition" SG_ 954 Mem_FS_Lordose_vor 0;
BA_ "GenSigSendType" SG_ 954 Mem_FS_Lordose_zurueck 3;
BA_ "GenSigSwitchedByIgnition" SG_ 954 Mem_FS_Lordose_zurueck 0;
BA_ "GenSigSendType" SG_ 954 Mem_FS_Massage_Geschw 3;
BA_ "GenSigSwitchedByIgnition" SG_ 954 Mem_FS_Massage_Geschw 0;
BA_ "GenSigSendType" SG_ 954 Mem_FS_Massage_Intensitaet 3;
BA_ "GenSigSwitchedByIgnition" SG_ 954 Mem_FS_Massage_Intensitaet 0;
BA_ "GenSigSendType" SG_ 954 Mem_FS_Massage_Programm 3;
BA_ "GenSigSwitchedByIgnition" SG_ 954 Mem_FS_Massage_Programm 0;
BA_ "GenSigSendType" SG_ 954 Mem_FS_SWangenLehne_beluef 3;
BA_ "GenSigSwitchedByIgnition" SG_ 954 Mem_FS_SWangenLehne_beluef 0;
BA_ "GenSigSendType" SG_ 954 Mem_FS_SWangenLehne_entlue 3;
BA_ "GenSigSwitchedByIgnition" SG_ 954 Mem_FS_SWangenLehne_entlue 0;
BA_ "GenSigSendType" SG_ 954 Mem_FS_SWangenSitz_beluef 3;
BA_ "GenSigSwitchedByIgnition" SG_ 954 Mem_FS_SWangenSitz_beluef 0;
BA_ "GenSigSendType" SG_ 954 Mem_FS_SWangenSitz_entlue 3;
BA_ "GenSigSwitchedByIgnition" SG_ 954 Mem_FS_SWangenSitz_entlue 0;
BA_ "GenSigSendType" SG_ 956 Mem_FSFo_Business_anfahren 3;
BA_ "GenSigSwitchedByIgnition" SG_ 956 Mem_FSFo_Business_anfahren 0;
BA_ "GenSigSendType" SG_ 956 Mem_FSFo_Lordose_hoch 3;
BA_ "GenSigSwitchedByIgnition" SG_ 956 Mem_FSFo_Lordose_hoch 0;
BA_ "GenSigSendType" SG_ 956 Mem_FSFo_Lordose_runter 3;
BA_ "GenSigSwitchedByIgnition" SG_ 956 Mem_FSFo_Lordose_runter 0;
BA_ "GenSigSendType" SG_ 956 Mem_FSFo_Lordose_vor 3;
BA_ "GenSigSwitchedByIgnition" SG_ 956 Mem_FSFo_Lordose_vor 0;
BA_ "GenSigSendType" SG_ 956 Mem_FSFo_Lordose_zurueck 3;
BA_ "GenSigSwitchedByIgnition" SG_ 956 Mem_FSFo_Lordose_zurueck 0;
BA_ "GenSigSendType" SG_ 956 Mem_FSFo_Massage_Geschw 3;
BA_ "GenSigSwitchedByIgnition" SG_ 956 Mem_FSFo_Massage_Geschw 0;
BA_ "GenSigSendType" SG_ 956 Mem_FSFo_Massage_Intens 3;
BA_ "GenSigSwitchedByIgnition" SG_ 956 Mem_FSFo_Massage_Intens 0;
BA_ "GenSigSendType" SG_ 956 Mem_FSFo_Massage_Prg 3;
BA_ "GenSigSwitchedByIgnition" SG_ 956 Mem_FSFo_Massage_Prg 0;
BA_ "GenSigSendType" SG_ 956 Mem_FSFo_MMB_glob_Stop 3;
BA_ "GenSigSwitchedByIgnition" SG_ 956 Mem_FSFo_MMB_glob_Stop 0;
BA_ "GenSigSendType" SG_ 956 Mem_FSFo_MMB_lokal_Stop 3;
BA_ "GenSigSwitchedByIgnition" SG_ 956 Mem_FSFo_MMB_lokal_Stop 0;
BA_ "GenSigSendType" SG_ 956 Mem_FSFo_MMB_storage 3;
BA_ "GenSigSwitchedByIgnition" SG_ 956 Mem_FSFo_MMB_storage 0;
BA_ "GenSigSendType" SG_ 956 Mem_FSFo_MMB_storage_beep 3;
BA_ "GenSigSwitchedByIgnition" SG_ 956 Mem_FSFo_MMB_storage_beep 0;
BA_ "GenSigSendType" SG_ 956 Mem_FSFo_MMB_store 3;
BA_ "GenSigSwitchedByIgnition" SG_ 956 Mem_FSFo_MMB_store 0;
BA_ "GenSigSendType" SG_ 956 Mem_FSFo_MMB_store_LED_on 3;
BA_ "GenSigSwitchedByIgnition" SG_ 956 Mem_FSFo_MMB_store_LED_on 0;
BA_ "GenSigSendType" SG_ 956 Mem_FSFo_MMB_tast 3;
BA_ "GenSigSwitchedByIgnition" SG_ 956 Mem_FSFo_MMB_tast 0;
BA_ "GenSigSendType" SG_ 956 Mem_FSFo_MMB_tipp 3;
BA_ "GenSigSwitchedByIgnition" SG_ 956 Mem_FSFo_MMB_tipp 0;
BA_ "GenSigSendType" SG_ 956 Mem_FSFo_Relax_anfahren 3;
BA_ "GenSigSwitchedByIgnition" SG_ 956 Mem_FSFo_Relax_anfahren 0;
BA_ "GenSigSendType" SG_ 956 Mem_FSFo_Sitzfahrt_aktiv 3;
BA_ "GenSigSwitchedByIgnition" SG_ 956 Mem_FSFo_Sitzfahrt_aktiv 0;
BA_ "GenSigSendType" SG_ 956 Mem_FSFo_Sitztiefe_vor 3;
BA_ "GenSigSwitchedByIgnition" SG_ 956 Mem_FSFo_Sitztiefe_vor 0;
BA_ "GenSigSendType" SG_ 956 Mem_FSFo_Sitztiefe_zur 3;
BA_ "GenSigSwitchedByIgnition" SG_ 956 Mem_FSFo_Sitztiefe_zur 0;
BA_ "GenSigSendType" SG_ 1180 Mem_Taster_BT_01_BZ 0;
BA_ "GenSigFuncType" SG_ 1180 Mem_Taster_BT_01_BZ 1;
BA_ "GenSigSwitchedByIgnition" SG_ 1180 Mem_Taster_BT_01_BZ 0;
BA_ "GenSigSendType" SG_ 1180 Mem_Taster_BT_01_CRC 0;
BA_ "GenSigFuncType" SG_ 1180 Mem_Taster_BT_01_CRC 2;
BA_ "GenSigActiveRepetitions" SG_ 1180 MTBT_M_Taste 6;
BA_ "GenSigSendType" SG_ 1180 MTBT_M_Taste 4;
BA_ "GenSigSwitchedByIgnition" SG_ 1180 MTBT_M_Taste 0;
BA_ "GenSigActiveRepetitions" SG_ 1180 MTBT_On_Off 6;
BA_ "GenSigSendType" SG_ 1180 MTBT_On_Off 4;
BA_ "GenSigSwitchedByIgnition" SG_ 1180 MTBT_On_Off 0;
BA_ "GenSigActiveRepetitions" SG_ 1180 MTBT_Pos1 6;
BA_ "GenSigSendType" SG_ 1180 MTBT_Pos1 4;
BA_ "GenSigSwitchedByIgnition" SG_ 1180 MTBT_Pos1 0;
BA_ "GenSigActiveRepetitions" SG_ 1180 MTBT_Pos2 6;
BA_ "GenSigSendType" SG_ 1180 MTBT_Pos2 4;
BA_ "GenSigSwitchedByIgnition" SG_ 1180 MTBT_Pos2 0;
BA_ "GenSigActiveRepetitions" SG_ 1180 MTBT_Pos3 6;
BA_ "GenSigSendType" SG_ 1180 MTBT_Pos3 4;
BA_ "GenSigSwitchedByIgnition" SG_ 1180 MTBT_Pos3 0;
BA_ "GenSigActiveRepetitions" SG_ 1180 MTBT_Pos4 6;
BA_ "GenSigSendType" SG_ 1180 MTBT_Pos4 4;
BA_ "GenSigSwitchedByIgnition" SG_ 1180 MTBT_Pos4 0;
BA_ "GenSigSendType" SG_ 1170 Mem_Taster_FT_01_BZ 0;
BA_ "GenSigFuncType" SG_ 1170 Mem_Taster_FT_01_BZ 1;
BA_ "GenSigSwitchedByIgnition" SG_ 1170 Mem_Taster_FT_01_BZ 0;
BA_ "GenSigSendType" SG_ 1170 Mem_Taster_FT_01_CRC 0;
BA_ "GenSigFuncType" SG_ 1170 Mem_Taster_FT_01_CRC 2;
BA_ "GenSigActiveRepetitions" SG_ 1170 MTFT_M_Taste 6;
BA_ "GenSigSendType" SG_ 1170 MTFT_M_Taste 4;
BA_ "GenSigSwitchedByIgnition" SG_ 1170 MTFT_M_Taste 0;
BA_ "GenSigActiveRepetitions" SG_ 1170 MTFT_On_Off 6;
BA_ "GenSigSendType" SG_ 1170 MTFT_On_Off 4;
BA_ "GenSigSwitchedByIgnition" SG_ 1170 MTFT_On_Off 0;
BA_ "GenSigActiveRepetitions" SG_ 1170 MTFT_Pos1_EE 6;
BA_ "GenSigSendType" SG_ 1170 MTFT_Pos1_EE 4;
BA_ "GenSigSwitchedByIgnition" SG_ 1170 MTFT_Pos1_EE 0;
BA_ "GenSigActiveRepetitions" SG_ 1170 MTFT_Pos2 6;
BA_ "GenSigSendType" SG_ 1170 MTFT_Pos2 4;
BA_ "GenSigSwitchedByIgnition" SG_ 1170 MTFT_Pos2 0;
BA_ "GenSigActiveRepetitions" SG_ 1170 MTFT_Pos3 6;
BA_ "GenSigSendType" SG_ 1170 MTFT_Pos3 4;
BA_ "GenSigSwitchedByIgnition" SG_ 1170 MTFT_Pos3 0;
BA_ "GenSigActiveRepetitions" SG_ 1170 MTFT_Pos4 6;
BA_ "GenSigSendType" SG_ 1170 MTFT_Pos4 4;
BA_ "GenSigSwitchedByIgnition" SG_ 1170 MTFT_Pos4 0;
BA_ "GenSigActiveRepetitions" SG_ 1170 MTFT_Verst_akt 6;
BA_ "GenSigSendType" SG_ 1170 MTFT_Verst_akt 4;
BA_ "GenSigSwitchedByIgnition" SG_ 1170 MTFT_Verst_akt 0;
BA_ "GenSigSendType" SG_ 1173 BFS_Kopfstuetzen_hoch 0;
BA_ "GenSigSwitchedByIgnition" SG_ 1173 BFS_Kopfstuetzen_hoch 0;
BA_ "GenSigSendType" SG_ 1173 BFS_Kopfstuetzen_runter 0;
BA_ "GenSigSwitchedByIgnition" SG_ 1173 BFS_Kopfstuetzen_runter 0;
BA_ "GenSigSendType" SG_ 1173 BFS_Laengsverst_vor 0;
BA_ "GenSigSwitchedByIgnition" SG_ 1173 BFS_Laengsverst_vor 0;
BA_ "GenSigSendType" SG_ 1173 BFS_Laengsverst_zurueck 0;
BA_ "GenSigSwitchedByIgnition" SG_ 1173 BFS_Laengsverst_zurueck 0;
BA_ "GenSigSendType" SG_ 1173 BFS_Lehnenkopf_vor 0;
BA_ "GenSigSwitchedByIgnition" SG_ 1173 BFS_Lehnenkopf_vor 0;
BA_ "GenSigSendType" SG_ 1173 BFS_Lehnenkopf_zurueck 0;
BA_ "GenSigSwitchedByIgnition" SG_ 1173 BFS_Lehnenkopf_zurueck 0;
BA_ "GenSigSendType" SG_ 1173 BFS_Lehnenneigung_vor 0;
BA_ "GenSigSwitchedByIgnition" SG_ 1173 BFS_Lehnenneigung_vor 0;
BA_ "GenSigSendType" SG_ 1173 BFS_Lehnenneigung_zurueck 0;
BA_ "GenSigSwitchedByIgnition" SG_ 1173 BFS_Lehnenneigung_zurueck 0;
BA_ "GenSigSendType" SG_ 1173 BFS_Sitzhoehe_hoch 0;
BA_ "GenSigSwitchedByIgnition" SG_ 1173 BFS_Sitzhoehe_hoch 0;
BA_ "GenSigSendType" SG_ 1173 BFS_Sitzhoehe_runter 0;
BA_ "GenSigSwitchedByIgnition" SG_ 1173 BFS_Sitzhoehe_runter 0;
BA_ "GenSigSendType" SG_ 1173 MTHBF_BZ 0;
BA_ "GenSigFuncType" SG_ 1173 MTHBF_BZ 1;
BA_ "GenSigSwitchedByIgnition" SG_ 1173 MTHBF_BZ 0;
BA_ "GenSigSendType" SG_ 1173 MTHBF_CRC 0;
BA_ "GenSigFuncType" SG_ 1173 MTHBF_CRC 2;
BA_ "GenSigSendType" SG_ 1173 MTHBF_ein 0;
BA_ "GenSigSwitchedByIgnition" SG_ 1173 MTHBF_ein 0;
BA_ "GenSigSendType" SG_ 817 MFL_Dummy_0_Signal_1 0;
BA_ "GenSigSwitchedByIgnition" SG_ 817 MFL_Dummy_0_Signal_1 0;
BA_ "GenSigSendType" SG_ 817 MFL_Dummy_0_Signal_2 0;
BA_ "GenSigSwitchedByIgnition" SG_ 817 MFL_Dummy_0_Signal_2 0;
BA_ "GenSigSendType" SG_ 817 MFL_Dummy_0_Signal_3 0;
BA_ "GenSigSwitchedByIgnition" SG_ 817 MFL_Dummy_0_Signal_3 0;
BA_ "GenSigSendType" SG_ 817 MFL_ECU_Err 0;
BA_ "GenSigSwitchedByIgnition" SG_ 817 MFL_ECU_Err 0;
BA_ "Fehlerwert" SG_ 817 MFL_ECU_Err 1;
BA_ "GenSigSendType" SG_ 817 MFL_Eventcode_1 0;
BA_ "GenSigSwitchedByIgnition" SG_ 817 MFL_Eventcode_1 0;
BA_ "GenSigSendType" SG_ 817 MFL_Eventcode_2 0;
BA_ "GenSigSwitchedByIgnition" SG_ 817 MFL_Eventcode_2 0;
BA_ "GenSigSendType" SG_ 817 MFL_Lokalaktiv 0;
BA_ "GenSigSwitchedByIgnition" SG_ 817 MFL_Lokalaktiv 0;
BA_ "GenSigSendType" SG_ 817 MFL_LR_HZG_Err 0;
BA_ "GenSigSwitchedByIgnition" SG_ 817 MFL_LR_HZG_Err 0;
BA_ "Fehlerwert" SG_ 817 MFL_LR_HZG_Err 1;
BA_ "GenSigSendType" SG_ 817 MFL_LR_HZG_Status 0;
BA_ "GenSigSwitchedByIgnition" SG_ 817 MFL_LR_HZG_Status 0;
BA_ "GenSigSendType" SG_ 817 MFL_M_Taste 0;
BA_ "GenSigSendType" SG_ 817 MFL_Marke 0;
BA_ "GenSigFuncType" SG_ 817 MFL_Marke 8;
BA_ "GenSigSwitchedByIgnition" SG_ 817 MFL_Marke 0;
BA_ "GenSigSendType" SG_ 817 MFL_Paddle_Verbau 0;
BA_ "GenSigSwitchedByIgnition" SG_ 817 MFL_Paddle_Verbau 0;
BA_ "GenSigSendType" SG_ 817 MFL_Response_Err 0;
BA_ "GenSigSwitchedByIgnition" SG_ 817 MFL_Response_Err 0;
BA_ "Fehlerwert" SG_ 817 MFL_Response_Err 1;
BA_ "GenSigSendType" SG_ 817 MFL_SatModul_links_Err 0;
BA_ "GenSigFuncType" SG_ 817 MFL_SatModul_links_Err 5;
BA_ "GenSigSwitchedByIgnition" SG_ 817 MFL_SatModul_links_Err 0;
BA_ "Fehlerwert" SG_ 817 MFL_SatModul_links_Err 1;
BA_ "GenSigSendType" SG_ 817 MFL_SatModul_rechts_Err 0;
BA_ "GenSigFuncType" SG_ 817 MFL_SatModul_rechts_Err 5;
BA_ "GenSigSwitchedByIgnition" SG_ 817 MFL_SatModul_rechts_Err 0;
BA_ "Fehlerwert" SG_ 817 MFL_SatModul_rechts_Err 1;
BA_ "GenSigSendType" SG_ 817 MFL_Signalhorn 5;
BA_ "GenSigSwitchedByIgnition" SG_ 817 MFL_Signalhorn 0;
BA_ "GenSigSendType" SG_ 817 MFL_Signalhorn_Err 0;
BA_ "GenSigSwitchedByIgnition" SG_ 817 MFL_Signalhorn_Err 0;
BA_ "Fehlerwert" SG_ 817 MFL_Signalhorn_Err 1;
BA_ "GenSigSendType" SG_ 817 MFL_Taste_links_Err 0;
BA_ "GenSigSwitchedByIgnition" SG_ 817 MFL_Taste_links_Err 0;
BA_ "Fehlerwert" SG_ 817 MFL_Taste_links_Err 1;
BA_ "GenSigSendType" SG_ 817 MFL_Taste_rechts_Err 0;
BA_ "GenSigSwitchedByIgnition" SG_ 817 MFL_Taste_rechts_Err 0;
BA_ "Fehlerwert" SG_ 817 MFL_Taste_rechts_Err 1;
BA_ "GenSigSendType" SG_ 817 MFL_Tastencode_1 0;
BA_ "GenSigSwitchedByIgnition" SG_ 817 MFL_Tastencode_1 0;
BA_ "GenSigSendType" SG_ 817 MFL_Tastencode_2 0;
BA_ "GenSigSwitchedByIgnition" SG_ 817 MFL_Tastencode_2 0;
BA_ "GenSigSendType" SG_ 817 MFL_Tip_Down 5;
BA_ "GenSigSendType" SG_ 817 MFL_Tip_links_Err 0;
BA_ "GenSigSwitchedByIgnition" SG_ 817 MFL_Tip_links_Err 0;
BA_ "Fehlerwert" SG_ 817 MFL_Tip_links_Err 1;
BA_ "GenSigSendType" SG_ 817 MFL_Tip_rechts_Err 0;
BA_ "GenSigSwitchedByIgnition" SG_ 817 MFL_Tip_rechts_Err 0;
BA_ "Fehlerwert" SG_ 817 MFL_Tip_rechts_Err 1;
BA_ "GenSigSendType" SG_ 817 MFL_Tip_Up 5;
BA_ "GenSigSendType" SG_ 817 MFL_Toggle 0;
BA_ "GenSigSwitchedByIgnition" SG_ 817 MFL_Toggle 0;
BA_ "GenSigSendType" SG_ 817 MFL_Variante 0;
BA_ "GenSigFuncType" SG_ 817 MFL_Variante 8;
BA_ "GenSigSwitchedByIgnition" SG_ 817 MFL_Variante 0;
BA_ "GenSigSendType" SG_ 817 MFL_Zaehler 0;
BA_ "GenSigSwitchedByIgnition" SG_ 817 MFL_Zaehler 0;
BA_ "GenSigSendType" SG_ 1471 MFL_Eventcode_1 1;
BA_ "GenSigSwitchedByIgnition" SG_ 1471 MFL_Eventcode_1 0;
BA_ "GenSigSendType" SG_ 1471 MFL_Eventcode_2 1;
BA_ "GenSigSwitchedByIgnition" SG_ 1471 MFL_Eventcode_2 0;
BA_ "GenSigSendType" SG_ 1471 MFL_Marke 1;
BA_ "GenSigFuncType" SG_ 1471 MFL_Marke 8;
BA_ "GenSigSwitchedByIgnition" SG_ 1471 MFL_Marke 0;
BA_ "GenSigSendType" SG_ 1471 MFL_Tastencode_1 1;
BA_ "GenSigSwitchedByIgnition" SG_ 1471 MFL_Tastencode_1 0;
BA_ "GenSigSendType" SG_ 1471 MFL_Tastencode_2 1;
BA_ "GenSigSwitchedByIgnition" SG_ 1471 MFL_Tastencode_2 0;
BA_ "GenSigSendType" SG_ 1471 MFL_Variante 1;
BA_ "GenSigFuncType" SG_ 1471 MFL_Variante 8;
BA_ "GenSigSwitchedByIgnition" SG_ 1471 MFL_Variante 0;
BA_ "GenSigSendType" SG_ 2463978670 SDF2_MIB_Fehler_Laengsrichtung 0;
BA_ "GenSigSendType" SG_ 2463978670 SDF2_MIB_Inhibitzeit 0;
BA_ "GenSigSendType" SG_ 2463978670 SDF2_MIB_Offset 0;
BA_ "GenSigSendType" SG_ 2463978670 SDF2_MIB_Segment_ID 0;
BA_ "GenSigSendType" SG_ 2463978670 SDF2_MIB_Standort_Eindeutig 0;
BA_ "GenSigSendType" SG_ 263 MO_Anzeigedrehz 0;
BA_ "GenSigSwitchedByIgnition" SG_ 263 MO_Anzeigedrehz 0;
BA_ "GenSigSendType" SG_ 263 MO_Effizienzmodus 0;
BA_ "GenSigSwitchedByIgnition" SG_ 263 MO_Effizienzmodus 0;
BA_ "GenSigSendType" SG_ 263 MO_Fehler_Oeldrucksensor 0;
BA_ "GenSigSwitchedByIgnition" SG_ 263 MO_Fehler_Oeldrucksensor 0;
BA_ "Fehlerwert" SG_ 263 MO_Fehler_Oeldrucksensor 1;
BA_ "GenSigSendType" SG_ 263 MO_Istgang 0;
BA_ "GenSigSwitchedByIgnition" SG_ 263 MO_Istgang 0;
BA_ "GenSigSendType" SG_ 263 MO_KVS 0;
BA_ "GenSigSwitchedByIgnition" SG_ 263 MO_KVS 0;
BA_ "GenSigSendType" SG_ 263 MO_KVS_Ueberlauf 0;
BA_ "GenSigSwitchedByIgnition" SG_ 263 MO_KVS_Ueberlauf 0;
BA_ "GenSigSendType" SG_ 263 MO_Ladedruck 0;
BA_ "GenSigSwitchedByIgnition" SG_ 263 MO_Ladedruck 0;
BA_ "Fehlerwert" SG_ 263 MO_Ladedruck 511;
BA_ "GenSigSendType" SG_ 263 MO_Oeldruck 0;
BA_ "GenSigStartValue" SG_ 263 MO_Oeldruck 254;
BA_ "GenSigSwitchedByIgnition" SG_ 263 MO_Oeldruck 0;
BA_ "Fehlerwert" SG_ 263 MO_Oeldruck 255;
BA_ "GenSigSendType" SG_ 263 MO_rel_Ladedruck 0;
BA_ "GenSigSwitchedByIgnition" SG_ 263 MO_rel_Ladedruck 0;
BA_ "Fehlerwert" SG_ 263 MO_rel_Ladedruck 255;
BA_ "GenSigSendType" SG_ 263 MO_Schaltempf_verfbar 0;
BA_ "GenSigSwitchedByIgnition" SG_ 263 MO_Schaltempf_verfbar 0;
BA_ "GenSigSendType" SG_ 263 MO_Sollgang 0;
BA_ "GenSigSwitchedByIgnition" SG_ 263 MO_Sollgang 0;
BA_ "GenSigSendType" SG_ 1600 MO_Absperrventil_oeffnen 0;
BA_ "GenSigSwitchedByIgnition" SG_ 1600 MO_Absperrventil_oeffnen 0;
BA_ "GenSigSendType" SG_ 1600 MO_aktives_Getriebeheizen 0;
BA_ "GenSigSwitchedByIgnition" SG_ 1600 MO_aktives_Getriebeheizen 0;
BA_ "GenSigSendType" SG_ 1600 MO_Ansaugluft_Temp 0;
BA_ "GenSigStartValue" SG_ 1600 MO_Ansaugluft_Temp 254;
BA_ "GenSigSwitchedByIgnition" SG_ 1600 MO_Ansaugluft_Temp 0;
BA_ "Fehlerwert" SG_ 1600 MO_Ansaugluft_Temp 255;
BA_ "GenSigSendType" SG_ 1600 MO_Getriebe_kuehlen 0;
BA_ "GenSigSwitchedByIgnition" SG_ 1600 MO_Getriebe_kuehlen 0;
BA_ "GenSigSendType" SG_ 1600 MO_Heizungspumpenansteuerung 0;
BA_ "GenSigStartValue" SG_ 1600 MO_Heizungspumpenansteuerung 14;
BA_ "GenSigSwitchedByIgnition" SG_ 1600 MO_Heizungspumpenansteuerung 0;
BA_ "Fehlerwert" SG_ 1600 MO_Heizungspumpenansteuerung 13;
BA_ "GenSigSendType" SG_ 1600 MO_Hoeheninfo 0;
BA_ "GenSigSwitchedByIgnition" SG_ 1600 MO_Hoeheninfo 0;
BA_ "Fehlerwert" SG_ 1600 MO_Hoeheninfo 255;
BA_ "GenSigSendType" SG_ 1600 MO_HYB_Fehler_HV_Netz 0;
BA_ "GenSigSwitchedByIgnition" SG_ 1600 MO_HYB_Fehler_HV_Netz 0;
BA_ "GenSigSendType" SG_ 1600 MO_Kennfeldk 0;
BA_ "GenSigSwitchedByIgnition" SG_ 1600 MO_Kennfeldk 0;
BA_ "GenSigSendType" SG_ 1600 MO_KL15_Abschaltempfehlung 0;
BA_ "GenSigSwitchedByIgnition" SG_ 1600 MO_KL15_Abschaltempfehlung 0;
BA_ "GenSigSendType" SG_ 1600 MO_Kuehlmittel_Temp 0;
BA_ "GenSigStartValue" SG_ 1600 MO_Kuehlmittel_Temp 254;
BA_ "GenSigSwitchedByIgnition" SG_ 1600 MO_Kuehlmittel_Temp 0;
BA_ "Fehlerwert" SG_ 1600 MO_Kuehlmittel_Temp 255;
BA_ "GenSigSendType" SG_ 1600 MO_Mom_Traegheit_02 0;
BA_ "GenSigSwitchedByIgnition" SG_ 1600 MO_Mom_Traegheit_02 0;
BA_ "GenSigSendType" SG_ 1600 MO_Nachlaufzeit_Heizungspumpe 0;
BA_ "GenSigSwitchedByIgnition" SG_ 1600 MO_Nachlaufzeit_Heizungspumpe 0;
BA_ "GenSigSendType" SG_ 1600 MO_Oel_Temp 0;
BA_ "GenSigStartValue" SG_ 1600 MO_Oel_Temp 254;
BA_ "GenSigSwitchedByIgnition" SG_ 1600 MO_Oel_Temp 0;
BA_ "Fehlerwert" SG_ 1600 MO_Oel_Temp 255;
BA_ "GenSigSendType" SG_ 1600 MO_QBit_Ansaugluft_Temp 0;
BA_ "GenSigStartValue" SG_ 1600 MO_QBit_Ansaugluft_Temp 1;
BA_ "GenSigSwitchedByIgnition" SG_ 1600 MO_QBit_Ansaugluft_Temp 0;
BA_ "GenSigSendType" SG_ 1600 MO_QBit_Hoeheninfo 0;
BA_ "GenSigStartValue" SG_ 1600 MO_QBit_Hoeheninfo 1;
BA_ "GenSigSwitchedByIgnition" SG_ 1600 MO_QBit_Hoeheninfo 0;
BA_ "GenSigSendType" SG_ 1600 MO_QBit_Kuehlmittel_Temp 0;
BA_ "GenSigStartValue" SG_ 1600 MO_QBit_Kuehlmittel_Temp 1;
BA_ "GenSigSwitchedByIgnition" SG_ 1600 MO_QBit_Kuehlmittel_Temp 0;
BA_ "GenSigSendType" SG_ 1600 MO_QBit_Oel_Temp 0;
BA_ "GenSigStartValue" SG_ 1600 MO_QBit_Oel_Temp 1;
BA_ "GenSigSwitchedByIgnition" SG_ 1600 MO_QBit_Oel_Temp 0;
BA_ "GenSigSendType" SG_ 1600 MO_SpannungsAnf 0;
BA_ "GenSigSwitchedByIgnition" SG_ 1600 MO_SpannungsAnf 0;
BA_ "GenSigSendType" SG_ 1600 MO_Versionsinfo_02 0;
BA_ "GenSigSwitchedByIgnition" SG_ 1600 MO_Versionsinfo_02 0;
BA_ "GenSigSendType" SG_ 1607 MO_CO2_Faktor 0;
BA_ "GenSigSwitchedByIgnition" SG_ 1607 MO_CO2_Faktor 0;
BA_ "Fehlerwert" SG_ 1607 MO_CO2_Faktor 4095;
BA_ "GenSigSendType" SG_ 1607 MO_E85_Sensor 0;
BA_ "GenSigStartValue" SG_ 1607 MO_E85_Sensor 14;
BA_ "GenSigSwitchedByIgnition" SG_ 1607 MO_E85_Sensor 0;
BA_ "Fehlerwert" SG_ 1607 MO_E85_Sensor 15;
BA_ "GenSigSendType" SG_ 1607 MO_Ethanol_Spuelhinweis 0;
BA_ "GenSigSwitchedByIgnition" SG_ 1607 MO_Ethanol_Spuelhinweis 0;
BA_ "GenSigSendType" SG_ 1607 MO_ITM_Kuehlmittel_Temp 0;
BA_ "GenSigStartValue" SG_ 1607 MO_ITM_Kuehlmittel_Temp 1;
BA_ "GenSigSwitchedByIgnition" SG_ 1607 MO_ITM_Kuehlmittel_Temp 0;
BA_ "Fehlerwert" SG_ 1607 MO_ITM_Kuehlmittel_Temp 2;
BA_ "GenSigSendType" SG_ 1607 MO_Kraftstofffilter_Wasser 0;
BA_ "GenSigSwitchedByIgnition" SG_ 1607 MO_Kraftstofffilter_Wasser 0;
BA_ "GenSigSwitchedByIgnition" SG_ 1607 MO_MKB_01 0;
BA_ "GenSigSwitchedByIgnition" SG_ 1607 MO_MKB_02 0;
BA_ "GenSigSwitchedByIgnition" SG_ 1607 MO_MKB_03 0;
BA_ "GenSigSwitchedByIgnition" SG_ 1607 MO_MKB_04 0;
BA_ "GenSigSendType" SG_ 1607 MO_MKB_MUX 0;
BA_ "GenSigSwitchedByIgnition" SG_ 1607 MO_MKB_MUX 0;
BA_ "GenSigSendType" SG_ 1607 SCR_Akustik 0;
BA_ "GenSigSwitchedByIgnition" SG_ 1607 SCR_Akustik 0;
BA_ "GenSigSendType" SG_ 1607 SCR_Anz_Motorstarts 0;
BA_ "GenSigStartValue" SG_ 1607 SCR_Anz_Motorstarts 15;
BA_ "GenSigSwitchedByIgnition" SG_ 1607 SCR_Anz_Motorstarts 0;
BA_ "GenSigSendType" SG_ 1607 SCR_Inducement_Strategie 0;
BA_ "GenSigSwitchedByIgnition" SG_ 1607 SCR_Inducement_Strategie 0;
BA_ "GenSigSendType" SG_ 1607 SCR_Reichweite 0;
BA_ "GenSigStartValue" SG_ 1607 SCR_Reichweite 32767;
BA_ "GenSigSwitchedByIgnition" SG_ 1607 SCR_Reichweite 0;
BA_ "GenSigSendType" SG_ 1607 SCR_Systemfehler 0;
BA_ "GenSigSwitchedByIgnition" SG_ 1607 SCR_Systemfehler 0;
BA_ "GenSigSendType" SG_ 1607 SCR_Text 0;
BA_ "GenSigSwitchedByIgnition" SG_ 1607 SCR_Text 0;
BA_ "GenSigSendType" SG_ 1607 SCR_verbaut 0;
BA_ "GenSigFuncType" SG_ 1607 SCR_verbaut 8;
BA_ "GenSigSwitchedByIgnition" SG_ 1607 SCR_verbaut 0;
BA_ "GenSigSendType" SG_ 1607 SCR_Warnstufe_1 0;
BA_ "GenSigSwitchedByIgnition" SG_ 1607 SCR_Warnstufe_1 0;
BA_ "GenSigSendType" SG_ 1607 SCR_Warnstufe_2 0;
BA_ "GenSigSwitchedByIgnition" SG_ 1607 SCR_Warnstufe_2 0;
BA_ "GenSigSendType" SG_ 167 MO_erste_Ungenauschwelle 0;
BA_ "GenSigSwitchedByIgnition" SG_ 167 MO_erste_Ungenauschwelle 0;
BA_ "GenSigSendType" SG_ 167 MO_Mom_Ist_Summe 0;
BA_ "GenSigStartValue" SG_ 167 MO_Mom_Ist_Summe 1022;
BA_ "GenSigSwitchedByIgnition" SG_ 167 MO_Mom_Ist_Summe 0;
BA_ "GenSigSendType" SG_ 167 MO_Mom_Schub 0;
BA_ "GenSigStartValue" SG_ 167 MO_Mom_Schub 510;
BA_ "GenSigSwitchedByIgnition" SG_ 167 MO_Mom_Schub 0;
BA_ "GenSigSendType" SG_ 167 MO_Mom_Soll_gefiltert 0;
BA_ "GenSigStartValue" SG_ 167 MO_Mom_Soll_gefiltert 1022;
BA_ "GenSigSwitchedByIgnition" SG_ 167 MO_Mom_Soll_gefiltert 0;
BA_ "GenSigSendType" SG_ 167 MO_Mom_Soll_Roh 0;
BA_ "GenSigStartValue" SG_ 167 MO_Mom_Soll_Roh 1022;
BA_ "GenSigSwitchedByIgnition" SG_ 167 MO_Mom_Soll_Roh 0;
BA_ "GenSigSendType" SG_ 167 MO_Mom_Traegheit_Summe 0;
BA_ "GenSigStartValue" SG_ 167 MO_Mom_Traegheit_Summe 1022;
BA_ "GenSigSwitchedByIgnition" SG_ 167 MO_Mom_Traegheit_Summe 0;
BA_ "GenSigSendType" SG_ 167 MO_QBit_Motormomente 0;
BA_ "GenSigStartValue" SG_ 167 MO_QBit_Motormomente 1;
BA_ "GenSigSwitchedByIgnition" SG_ 167 MO_QBit_Motormomente 0;
BA_ "GenSigSendType" SG_ 167 MO_Status_Normalbetrieb_01 0;
BA_ "GenSigSwitchedByIgnition" SG_ 167 MO_Status_Normalbetrieb_01 0;
BA_ "GenSigSendType" SG_ 167 Motor_11_BZ 0;
BA_ "GenSigFuncType" SG_ 167 Motor_11_BZ 1;
BA_ "GenSigSwitchedByIgnition" SG_ 167 Motor_11_BZ 0;
BA_ "GenSigSendType" SG_ 167 Motor_11_CRC 0;
BA_ "GenSigFuncType" SG_ 167 Motor_11_CRC 2;
BA_ "GenSigSwitchedByIgnition" SG_ 167 Motor_11_CRC 0;
BA_ "GenSigSendType" SG_ 168 MO_Drehzahl_01 0;
BA_ "GenSigSwitchedByIgnition" SG_ 168 MO_Drehzahl_01 0;
BA_ "GenSigSendType" SG_ 168 MO_Mom_Begr_dyn 0;
BA_ "GenSigStartValue" SG_ 168 MO_Mom_Begr_dyn 1022;
BA_ "GenSigSwitchedByIgnition" SG_ 168 MO_Mom_Begr_dyn 0;
BA_ "GenSigSendType" SG_ 168 MO_Mom_Begr_stat 0;
BA_ "GenSigStartValue" SG_ 168 MO_Mom_Begr_stat 510;
BA_ "GenSigSwitchedByIgnition" SG_ 168 MO_Mom_Begr_stat 0;
BA_ "GenSigSendType" SG_ 168 MO_Mom_neg_verfuegbar 0;
BA_ "GenSigStartValue" SG_ 168 MO_Mom_neg_verfuegbar 510;
BA_ "GenSigSwitchedByIgnition" SG_ 168 MO_Mom_neg_verfuegbar 0;
BA_ "Fehlerwert" SG_ 168 MO_Mom_neg_verfuegbar 511;
BA_ "GenSigSendType" SG_ 168 MO_Momentenintegral_02 0;
BA_ "GenSigSwitchedByIgnition" SG_ 168 MO_Momentenintegral_02 0;
BA_ "GenSigSendType" SG_ 168 MO_QBit_Drehzahl_01 0;
BA_ "GenSigStartValue" SG_ 168 MO_QBit_Drehzahl_01 1;
BA_ "GenSigSwitchedByIgnition" SG_ 168 MO_QBit_Drehzahl_01 0;
BA_ "GenSigSendType" SG_ 168 Motor_12_BZ 0;
BA_ "GenSigFuncType" SG_ 168 Motor_12_BZ 1;
BA_ "GenSigSwitchedByIgnition" SG_ 168 Motor_12_BZ 0;
BA_ "GenSigSendType" SG_ 168 Motor_12_CRC 0;
BA_ "GenSigFuncType" SG_ 168 Motor_12_CRC 2;
BA_ "GenSigSwitchedByIgnition" SG_ 168 Motor_12_CRC 0;
BA_ "GenSigSendType" SG_ 958 MO_Aussp_Anlass 3;
BA_ "GenSigSwitchedByIgnition" SG_ 958 MO_Aussp_Anlass 0;
BA_ "GenSigSendType" SG_ 958 MO_BKV_Unterdruckwarnung 0;
BA_ "GenSigSwitchedByIgnition" SG_ 958 MO_BKV_Unterdruckwarnung 0;
BA_ "GenSigSendType" SG_ 958 MO_BLS 3;
BA_ "GenSigSwitchedByIgnition" SG_ 958 MO_BLS 0;
BA_ "GenSigSendType" SG_ 958 MO_BMS_NV_Anf_stuetzen 3;
BA_ "GenSigSwitchedByIgnition" SG_ 958 MO_BMS_NV_Anf_stuetzen 0;
BA_ "GenSigSendType" SG_ 958 MO_EKlKomLeiRed 0;
BA_ "GenSigSwitchedByIgnition" SG_ 958 MO_EKlKomLeiRed 0;
BA_ "GenSigSendType" SG_ 958 MO_Ext_E_Fahrt_aktiv 3;
BA_ "NWM-WakeupAllowed" SG_ 958 MO_Ext_E_Fahrt_aktiv 1;
BA_ "GenSigSwitchedByIgnition" SG_ 958 MO_Ext_E_Fahrt_aktiv 0;
BA_ "GenSigSendType" SG_ 958 MO_Fahrer_bremst 3;
BA_ "GenSigSwitchedByIgnition" SG_ 958 MO_Fahrer_bremst 0;
BA_ "GenSigSendType" SG_ 958 MO_FMAus_aktiv 3;
BA_ "GenSigSwitchedByIgnition" SG_ 958 MO_FMAus_aktiv 0;
BA_ "GenSigSendType" SG_ 958 MO_FMAus_Startvariante 3;
BA_ "GenSigSwitchedByIgnition" SG_ 958 MO_FMAus_Startvariante 0;
BA_ "GenSigSendType" SG_ 958 MO_Freig_Anlass 3;
BA_ "GenSigSwitchedByIgnition" SG_ 958 MO_Freig_Anlass 0;
BA_ "GenSigSendType" SG_ 958 MO_Freig_Reku 0;
BA_ "GenSigSwitchedByIgnition" SG_ 958 MO_Freig_Reku 0;
BA_ "GenSigSendType" SG_ 958 MO_Freigabe_Segeln 0;
BA_ "GenSigSwitchedByIgnition" SG_ 958 MO_Freigabe_Segeln 0;
BA_ "GenSigSendType" SG_ 958 MO_Gangposition 3;
BA_ "GenSigStartValue" SG_ 958 MO_Gangposition 14;
BA_ "GenSigSwitchedByIgnition" SG_ 958 MO_Gangposition 0;
BA_ "Fehlerwert" SG_ 958 MO_Gangposition 15;
BA_ "GenSigSendType" SG_ 958 MO_Handshake_STH 0;
BA_ "GenSigSwitchedByIgnition" SG_ 958 MO_Handshake_STH 0;
BA_ "GenSigSendType" SG_ 958 MO_HYB_Fahrbereitschaft 0;
BA_ "GenSigSwitchedByIgnition" SG_ 958 MO_HYB_Fahrbereitschaft 0;
BA_ "GenSigSendType" SG_ 958 MO_HYB_VM_aktiv 3;
BA_ "GenSigSwitchedByIgnition" SG_ 958 MO_HYB_VM_aktiv 0;
BA_ "GenSigSendType" SG_ 958 MO_Interlock 3;
BA_ "GenSigSwitchedByIgnition" SG_ 958 MO_Interlock 0;
BA_ "GenSigSendType" SG_ 958 MO_Kickdown 3;
BA_ "GenSigSwitchedByIgnition" SG_ 958 MO_Kickdown 0;
BA_ "GenSigSendType" SG_ 958 MO_Kl_50 3;
BA_ "GenSigSwitchedByIgnition" SG_ 958 MO_Kl_50 0;
BA_ "GenSigSendType" SG_ 958 MO_Kl_75 3;
BA_ "GenSigSwitchedByIgnition" SG_ 958 MO_Kl_75 0;
BA_ "GenSigSendType" SG_ 958 MO_Klima_Eingr 0;
BA_ "GenSigSwitchedByIgnition" SG_ 958 MO_Klima_Eingr 0;
BA_ "GenSigSendType" SG_ 958 MO_KomFehler_ESP 3;
BA_ "GenSigSwitchedByIgnition" SG_ 958 MO_KomFehler_ESP 0;
BA_ "Fehlerwert" SG_ 958 MO_KomFehler_ESP 1;
BA_ "GenSigSendType" SG_ 958 MO_Konsistenz_Bremsped 3;
BA_ "GenSigSwitchedByIgnition" SG_ 958 MO_Konsistenz_Bremsped 0;
BA_ "GenSigSendType" SG_ 958 MO_Kuppl_schalter 3;
BA_ "GenSigSwitchedByIgnition" SG_ 958 MO_Kuppl_schalter 0;
BA_ "GenSigSendType" SG_ 958 MO_Motor_laeuft 3;
BA_ "GenSigSwitchedByIgnition" SG_ 958 MO_Motor_laeuft 0;
BA_ "GenSigSendType" SG_ 958 MO_PTC_Status 0;
BA_ "GenSigSwitchedByIgnition" SG_ 958 MO_PTC_Status 0;
BA_ "GenSigSendType" SG_ 958 MO_QBit_Fahrer_bremst 3;
BA_ "GenSigStartValue" SG_ 958 MO_QBit_Fahrer_bremst 1;
BA_ "GenSigSwitchedByIgnition" SG_ 958 MO_QBit_Fahrer_bremst 0;
BA_ "GenSigSendType" SG_ 958 MO_QBit_Gangposition 3;
BA_ "GenSigStartValue" SG_ 958 MO_QBit_Gangposition 1;
BA_ "GenSigSwitchedByIgnition" SG_ 958 MO_QBit_Gangposition 0;
BA_ "GenSigSendType" SG_ 958 MO_QBit_KL_75 3;
BA_ "GenSigStartValue" SG_ 958 MO_QBit_KL_75 1;
BA_ "GenSigSwitchedByIgnition" SG_ 958 MO_QBit_KL_75 0;
BA_ "GenSigSendType" SG_ 958 MO_Remotestart_Betrieb 3;
BA_ "GenSigSwitchedByIgnition" SG_ 958 MO_Remotestart_Betrieb 0;
BA_ "GenSigSendType" SG_ 958 MO_Remotestart_moeglich 0;
BA_ "GenSigSwitchedByIgnition" SG_ 958 MO_Remotestart_moeglich 0;
BA_ "GenSigSendType" SG_ 958 MO_Signalquelle_Gangposition 0;
BA_ "GenSigSwitchedByIgnition" SG_ 958 MO_Signalquelle_Gangposition 0;
BA_ "GenSigSendType" SG_ 958 MO_StartStopp_Fahrerwunsch 0;
BA_ "GenSigSwitchedByIgnition" SG_ 958 MO_StartStopp_Fahrerwunsch 0;
BA_ "GenSigSendType" SG_ 958 MO_StartStopp_Motorstopp 3;
BA_ "GenSigSwitchedByIgnition" SG_ 958 MO_StartStopp_Motorstopp 0;
BA_ "GenSigSendType" SG_ 958 MO_StartStopp_Status 3;
BA_ "GenSigSwitchedByIgnition" SG_ 958 MO_StartStopp_Status 0;
BA_ "GenSigSendType" SG_ 958 MO_StartStopp_Wiederstart 3;
BA_ "GenSigSwitchedByIgnition" SG_ 958 MO_StartStopp_Wiederstart 0;
BA_ "GenSigSendType" SG_ 958 MO_StartVorauss_erfuellt 3;
BA_ "GenSigStartValue" SG_ 958 MO_StartVorauss_erfuellt 1;
BA_ "GenSigSwitchedByIgnition" SG_ 958 MO_StartVorauss_erfuellt 0;
BA_ "GenSigSendType" SG_ 958 MO_Zylinderabschaltung 3;
BA_ "GenSigSwitchedByIgnition" SG_ 958 MO_Zylinderabschaltung 0;
BA_ "GenSigSendType" SG_ 958 Motor_14_BZ 0;
BA_ "GenSigFuncType" SG_ 958 Motor_14_BZ 1;
BA_ "GenSigSwitchedByIgnition" SG_ 958 Motor_14_BZ 0;
BA_ "GenSigSendType" SG_ 958 Motor_14_CRC 0;
BA_ "GenSigFuncType" SG_ 958 Motor_14_CRC 2;
BA_ "GenSigSwitchedByIgnition" SG_ 958 Motor_14_CRC 0;
BA_ "GenSigSendType" SG_ 1631 MO_Anzeige_Kaltleuchte 0;
BA_ "GenSigSwitchedByIgnition" SG_ 1631 MO_Anzeige_Kaltleuchte 0;
BA_ "GenSigSendType" SG_ 1631 MO_DPF_reg 0;
BA_ "GenSigSwitchedByIgnition" SG_ 1631 MO_DPF_reg 0;
BA_ "GenSigSendType" SG_ 1631 MO_Energieinhalt_BMS 0;
BA_ "GenSigStartValue" SG_ 1631 MO_Energieinhalt_BMS 4094;
BA_ "GenSigSwitchedByIgnition" SG_ 1631 MO_Energieinhalt_BMS 0;
BA_ "Fehlerwert" SG_ 1631 MO_Energieinhalt_BMS 4095;
BA_ "GenSigSendType" SG_ 1631 MO_Heizstrom_EKAT 0;
BA_ "GenSigSwitchedByIgnition" SG_ 1631 MO_Heizstrom_EKAT 0;
BA_ "Fehlerwert" SG_ 1631 MO_Heizstrom_EKAT 127;
BA_ "GenSigSendType" SG_ 1631 MO_Heizstrom_SCR 0;
BA_ "GenSigSwitchedByIgnition" SG_ 1631 MO_Heizstrom_SCR 0;
BA_ "Fehlerwert" SG_ 1631 MO_Heizstrom_SCR 63;
BA_ "GenSigSendType" SG_ 1631 MO_P_Generator_ungefiltert_Anf 0;
BA_ "GenSigSwitchedByIgnition" SG_ 1631 MO_P_Generator_ungefiltert_Anf 0;
BA_ "GenSigSendType" SG_ 1631 MO_SpannungsAnf_02 0;
BA_ "GenSigSwitchedByIgnition" SG_ 1631 MO_SpannungsAnf_02 0;
BA_ "GenSigSendType" SG_ 1631 TSK_Fahrzeugmasse_02 0;
BA_ "GenSigSwitchedByIgnition" SG_ 1631 TSK_Fahrzeugmasse_02 0;
BA_ "Fehlerwert" SG_ 1631 TSK_Fahrzeugmasse_02 255;
BA_ "GenSigSendType" SG_ 1631 TSK_Getriebeinfo 0;
BA_ "GenSigSwitchedByIgnition" SG_ 1631 TSK_Getriebeinfo 0;
BA_ "GenSigSendType" SG_ 1631 TSK_Grundmasse 0;
BA_ "GenSigSwitchedByIgnition" SG_ 1631 TSK_Grundmasse 0;
BA_ "GenSigSendType" SG_ 1631 TSK_QBit_Fahrzeugmasse 0;
BA_ "GenSigStartValue" SG_ 1631 TSK_QBit_Fahrzeugmasse 1;
BA_ "GenSigSwitchedByIgnition" SG_ 1631 TSK_QBit_Fahrzeugmasse 0;
BA_ "GenSigSendType" SG_ 1631 TSK_QBit_Steigung 0;
BA_ "GenSigStartValue" SG_ 1631 TSK_QBit_Steigung 1;
BA_ "GenSigSwitchedByIgnition" SG_ 1631 TSK_QBit_Steigung 0;
BA_ "GenSigSendType" SG_ 1631 TSK_Steigung_02 0;
BA_ "GenSigSwitchedByIgnition" SG_ 1631 TSK_Steigung_02 0;
BA_ "Fehlerwert" SG_ 1631 TSK_Steigung_02 255;
BA_ "GenSigSendType" SG_ 1648 MO1_Freigabe_Info_WFS 3;
BA_ "GenSigSwitchedByIgnition" SG_ 1648 MO1_Freigabe_Info_WFS 0;
BA_ "GenSigSendType" SG_ 1648 MO1_Freigabe_Verfallsinfo_WFS 3;
BA_ "GenSigSwitchedByIgnition" SG_ 1648 MO1_Freigabe_Verfallsinfo_WFS 0;
BA_ "GenSigSendType" SG_ 1648 MO1_Sperr_Info_WFS 3;
BA_ "GenSigSwitchedByIgnition" SG_ 1648 MO1_Sperr_Info_WFS 0;
BA_ "GenSigSendType" SG_ 1648 MO_Abstellzeit 0;
BA_ "GenSigStartValue" SG_ 1648 MO_Abstellzeit 254;
BA_ "GenSigSwitchedByIgnition" SG_ 1648 MO_Abstellzeit 0;
BA_ "GenSigSendType" SG_ 1648 MO_Abstellzeit_Status 0;
BA_ "GenSigSwitchedByIgnition" SG_ 1648 MO_Abstellzeit_Status 0;
BA_ "GenSigSendType" SG_ 1648 MO_ANC_Kennfeld_Anf 3;
BA_ "GenSigSwitchedByIgnition" SG_ 1648 MO_ANC_Kennfeld_Anf 0;
BA_ "GenSigSendType" SG_ 1648 MO_Anzahl_Abgesch_Zyl 3;
BA_ "GenSigSwitchedByIgnition" SG_ 1648 MO_Anzahl_Abgesch_Zyl 0;
BA_ "GenSigSendType" SG_ 1648 MO_Bremslicht_Reku 3;
BA_ "GenSigSwitchedByIgnition" SG_ 1648 MO_Bremslicht_Reku 0;
BA_ "GenSigSendType" SG_ 1648 MO_Drehzahl_Warnung 0;
BA_ "GenSigSwitchedByIgnition" SG_ 1648 MO_Drehzahl_Warnung 0;
BA_ "GenSigSendType" SG_ 1648 MO_EPCL 0;
BA_ "GenSigSwitchedByIgnition" SG_ 1648 MO_EPCL 0;
BA_ "GenSigSendType" SG_ 1648 MO_Ethanol_BS_Texte 0;
BA_ "GenSigSwitchedByIgnition" SG_ 1648 MO_Ethanol_BS_Texte 0;
BA_ "GenSigSendType" SG_ 1648 MO_Fahrzeugtyp 0;
BA_ "GenSigFuncType" SG_ 1648 MO_Fahrzeugtyp 8;
BA_ "GenSigSwitchedByIgnition" SG_ 1648 MO_Fahrzeugtyp 0;
BA_ "GenSigSendType" SG_ 1648 MO_Fehler_Zylabsch 0;
BA_ "GenSigSwitchedByIgnition" SG_ 1648 MO_Fehler_Zylabsch 0;
BA_ "GenSigSendType" SG_ 1648 MO_Hybrid_StartStopp_LED 3;
BA_ "GenSigSwitchedByIgnition" SG_ 1648 MO_Hybrid_StartStopp_LED 0;
BA_ "GenSigSendType" SG_ 1648 MO_max_Ladedruck 0;
BA_ "GenSigFuncType" SG_ 1648 MO_max_Ladedruck 8;
BA_ "GenSigSwitchedByIgnition" SG_ 1648 MO_max_Ladedruck 0;
BA_ "GenSigSendType" SG_ 1648 MO_NMAX_Schaltanzeige 3;
BA_ "GenSigSwitchedByIgnition" SG_ 1648 MO_NMAX_Schaltanzeige 0;
BA_ "GenSigSendType" SG_ 1648 MO_obere_Drehzahlgrenze 0;
BA_ "GenSigSwitchedByIgnition" SG_ 1648 MO_obere_Drehzahlgrenze 0;
BA_ "GenSigSendType" SG_ 1648 MO_StartStopp_PopUp 3;
BA_ "GenSigSwitchedByIgnition" SG_ 1648 MO_StartStopp_PopUp 0;
BA_ "GenSigSendType" SG_ 1648 MO_Zylabsch_Texte 0;
BA_ "GenSigSwitchedByIgnition" SG_ 1648 MO_Zylabsch_Texte 0;
BA_ "GenSigSendType" SG_ 1648 MO_Zylabsch_Texte_02 3;
BA_ "GenSigSwitchedByIgnition" SG_ 1648 MO_Zylabsch_Texte_02 0;
BA_ "GenSigSendType" SG_ 289 MO_Entkopplung_Sollschlupf 0;
BA_ "GenSigStartValue" SG_ 289 MO_Entkopplung_Sollschlupf 126;
BA_ "GenSigSwitchedByIgnition" SG_ 289 MO_Entkopplung_Sollschlupf 0;
BA_ "GenSigSendType" SG_ 289 MO_Fahrpedalgradient 0;
BA_ "GenSigSwitchedByIgnition" SG_ 289 MO_Fahrpedalgradient 0;
BA_ "Fehlerwert" SG_ 289 MO_Fahrpedalgradient 255;
BA_ "GenSigSendType" SG_ 289 MO_Fahrpedalrohwert_01 0;
BA_ "GenSigSwitchedByIgnition" SG_ 289 MO_Fahrpedalrohwert_01 0;
BA_ "Fehlerwert" SG_ 289 MO_Fahrpedalrohwert_01 255;
BA_ "GenSigSendType" SG_ 289 MO_Moment_im_Leerlauf 0;
BA_ "GenSigSwitchedByIgnition" SG_ 289 MO_Moment_im_Leerlauf 0;
BA_ "GenSigSendType" SG_ 289 MO_QBit_Fahrpedalwerte_01 0;
BA_ "GenSigStartValue" SG_ 289 MO_QBit_Fahrpedalwerte_01 1;
BA_ "GenSigSwitchedByIgnition" SG_ 289 MO_QBit_Fahrpedalwerte_01 0;
BA_ "GenSigSendType" SG_ 289 MO_rel_Saugrohrdruck 0;
BA_ "GenSigSwitchedByIgnition" SG_ 289 MO_rel_Saugrohrdruck 0;
BA_ "Fehlerwert" SG_ 289 MO_rel_Saugrohrdruck 63;
BA_ "GenSigSendType" SG_ 289 MO_rel_Saugrohrdruck_gem_err 0;
BA_ "GenSigSwitchedByIgnition" SG_ 289 MO_rel_Saugrohrdruck_gem_err 0;
BA_ "GenSigSendType" SG_ 289 MO_Schubabschaltung 0;
BA_ "GenSigSwitchedByIgnition" SG_ 289 MO_Schubabschaltung 0;
BA_ "GenSigSendType" SG_ 289 MO_Sig_Fahrpedalgradient 0;
BA_ "GenSigSwitchedByIgnition" SG_ 289 MO_Sig_Fahrpedalgradient 0;
BA_ "GenSigSendType" SG_ 289 MO_Solldrehz_Leerlauf 0;
BA_ "GenSigSwitchedByIgnition" SG_ 289 MO_Solldrehz_Leerlauf 0;
BA_ "GenSigSendType" SG_ 289 MO_StartStopp_StoppVorbereitung 0;
BA_ "GenSigSwitchedByIgnition" SG_ 289 MO_StartStopp_StoppVorbereitung 0;
BA_ "GenSigSendType" SG_ 289 MO_temporaere_Fahrerabwesenheit 0;
BA_ "GenSigSwitchedByIgnition" SG_ 289 MO_temporaere_Fahrerabwesenheit 0;
BA_ "GenSigSendType" SG_ 289 Motor_20_BZ 0;
BA_ "GenSigFuncType" SG_ 289 Motor_20_BZ 1;
BA_ "GenSigSwitchedByIgnition" SG_ 289 Motor_20_BZ 0;
BA_ "GenSigSendType" SG_ 289 Motor_20_CRC 0;
BA_ "GenSigFuncType" SG_ 289 Motor_20_CRC 2;
BA_ "GenSigSwitchedByIgnition" SG_ 289 Motor_20_CRC 0;
BA_ "GenSigSendType" SG_ 289 TSK_a_Soll_gradientenbegrenzt 0;
BA_ "GenSigStartValue" SG_ 289 TSK_a_Soll_gradientenbegrenzt 127;
BA_ "GenSigSwitchedByIgnition" SG_ 289 TSK_a_Soll_gradientenbegrenzt 0;
BA_ "GenSigSendType" SG_ 1654 MO_StaGluehk 3;
BA_ "GenSigSwitchedByIgnition" SG_ 1654 MO_StaGluehk 0;
BA_ "Fehlerwert" SG_ 1654 MO_StaGluehk 15;
BA_ "GenSigSendType" SG_ 1654 MO_Stoppverbot_Anz_01 3;
BA_ "GenSigSwitchedByIgnition" SG_ 1654 MO_Stoppverbot_Anz_01 0;
BA_ "GenSigSendType" SG_ 1654 MO_Stoppverbot_Anz_02 3;
BA_ "GenSigSwitchedByIgnition" SG_ 1654 MO_Stoppverbot_Anz_02 0;
BA_ "GenSigSendType" SG_ 1654 MO_Stoppverbot_Anz_03 3;
BA_ "GenSigSwitchedByIgnition" SG_ 1654 MO_Stoppverbot_Anz_03 0;
BA_ "GenSigSendType" SG_ 1654 MO_Stoppverbot_Anz_04 3;
BA_ "GenSigSwitchedByIgnition" SG_ 1654 MO_Stoppverbot_Anz_04 0;
BA_ "GenSigSendType" SG_ 1654 MO_Stoppverbot_Anz_05 3;
BA_ "GenSigSwitchedByIgnition" SG_ 1654 MO_Stoppverbot_Anz_05 0;
BA_ "GenSigSendType" SG_ 1654 MO_Stoppverbot_Anz_06 3;
BA_ "GenSigSwitchedByIgnition" SG_ 1654 MO_Stoppverbot_Anz_06 0;
BA_ "GenSigSendType" SG_ 1654 MO_Stoppverbot_Anz_07 3;
BA_ "GenSigSwitchedByIgnition" SG_ 1654 MO_Stoppverbot_Anz_07 0;
BA_ "GenSigSendType" SG_ 1654 MO_Stoppverbot_Anz_08 3;
BA_ "GenSigSwitchedByIgnition" SG_ 1654 MO_Stoppverbot_Anz_08 0;
BA_ "GenSigSendType" SG_ 1654 MO_Stoppverbot_Anz_09 3;
BA_ "GenSigSwitchedByIgnition" SG_ 1654 MO_Stoppverbot_Anz_09 0;
BA_ "GenSigSendType" SG_ 1654 MO_Stoppverbot_Anz_10 3;
BA_ "GenSigSwitchedByIgnition" SG_ 1654 MO_Stoppverbot_Anz_10 0;
BA_ "GenSigSendType" SG_ 1654 MO_Stoppverbot_Anz_11 3;
BA_ "GenSigSwitchedByIgnition" SG_ 1654 MO_Stoppverbot_Anz_11 0;
BA_ "GenSigSendType" SG_ 1654 MO_Stoppverbot_Anz_Std 3;
BA_ "GenSigSwitchedByIgnition" SG_ 1654 MO_Stoppverbot_Anz_Std 0;
BA_ "GenSigSendType" SG_ 1654 MO_Wiederstart_Anz_01 3;
BA_ "GenSigSwitchedByIgnition" SG_ 1654 MO_Wiederstart_Anz_01 0;
BA_ "GenSigSendType" SG_ 1654 MO_Wiederstart_Anz_02 3;
BA_ "GenSigSwitchedByIgnition" SG_ 1654 MO_Wiederstart_Anz_02 0;
BA_ "GenSigSendType" SG_ 1654 MO_Wiederstart_Anz_03 3;
BA_ "GenSigSwitchedByIgnition" SG_ 1654 MO_Wiederstart_Anz_03 0;
BA_ "GenSigSendType" SG_ 1654 MO_Wiederstart_Anz_Std 3;
BA_ "GenSigSwitchedByIgnition" SG_ 1654 MO_Wiederstart_Anz_Std 0;
BA_ "GenSigSendType" SG_ 1654 StSt_Koord_Status_Bremspedalkzpt 3;
BA_ "GenSigSwitchedByIgnition" SG_ 1654 StSt_Koord_Status_Bremspedalkzpt 0;
BA_ "GenSigSendType" SG_ 1654 StSt_Koord_Stoppverbot_Anz_01 3;
BA_ "GenSigSwitchedByIgnition" SG_ 1654 StSt_Koord_Stoppverbot_Anz_01 0;
BA_ "GenSigSendType" SG_ 1654 StSt_Koord_Stoppverbot_Anz_02 3;
BA_ "GenSigSwitchedByIgnition" SG_ 1654 StSt_Koord_Stoppverbot_Anz_02 0;
BA_ "GenSigSendType" SG_ 1654 StSt_Koord_Stoppverbot_Anz_03 3;
BA_ "GenSigSwitchedByIgnition" SG_ 1654 StSt_Koord_Stoppverbot_Anz_03 0;
BA_ "GenSigSendType" SG_ 1654 StSt_Koord_Stoppverbot_Anz_04 3;
BA_ "GenSigSwitchedByIgnition" SG_ 1654 StSt_Koord_Stoppverbot_Anz_04 0;
BA_ "GenSigSendType" SG_ 1654 StSt_Koord_Stoppverbot_Anz_05 3;
BA_ "GenSigSwitchedByIgnition" SG_ 1654 StSt_Koord_Stoppverbot_Anz_05 0;
BA_ "GenSigSendType" SG_ 1654 StSt_Koord_Stoppverbot_Anz_06 3;
BA_ "GenSigSwitchedByIgnition" SG_ 1654 StSt_Koord_Stoppverbot_Anz_06 0;
BA_ "GenSigSendType" SG_ 1654 StSt_Koord_Stoppverbot_Anz_07 3;
BA_ "GenSigSwitchedByIgnition" SG_ 1654 StSt_Koord_Stoppverbot_Anz_07 0;
BA_ "GenSigSendType" SG_ 1654 StSt_Koord_Stoppverbot_Anz_08 3;
BA_ "GenSigSwitchedByIgnition" SG_ 1654 StSt_Koord_Stoppverbot_Anz_08 0;
BA_ "GenSigSendType" SG_ 1654 StSt_Koord_Stoppverbot_Anz_09 3;
BA_ "GenSigSwitchedByIgnition" SG_ 1654 StSt_Koord_Stoppverbot_Anz_09 0;
BA_ "GenSigSendType" SG_ 1654 StSt_Koord_Stoppverbot_Anz_10 3;
BA_ "GenSigSwitchedByIgnition" SG_ 1654 StSt_Koord_Stoppverbot_Anz_10 0;
BA_ "GenSigSendType" SG_ 1654 StSt_Koord_Stoppverbot_Anz_11 3;
BA_ "GenSigSwitchedByIgnition" SG_ 1654 StSt_Koord_Stoppverbot_Anz_11 0;
BA_ "GenSigSendType" SG_ 1654 StSt_Koord_Stoppverbot_Anz_12 3;
BA_ "GenSigSwitchedByIgnition" SG_ 1654 StSt_Koord_Stoppverbot_Anz_12 0;
BA_ "GenSigSendType" SG_ 1654 StSt_Koord_Stoppverbot_Anz_13 3;
BA_ "GenSigSwitchedByIgnition" SG_ 1654 StSt_Koord_Stoppverbot_Anz_13 0;
BA_ "GenSigSendType" SG_ 1654 StSt_Koord_Stoppverbot_Anz_14 3;
BA_ "GenSigSwitchedByIgnition" SG_ 1654 StSt_Koord_Stoppverbot_Anz_14 0;
BA_ "GenSigSendType" SG_ 1654 StSt_Koord_Stoppverbot_Anz_15 3;
BA_ "GenSigSwitchedByIgnition" SG_ 1654 StSt_Koord_Stoppverbot_Anz_15 0;
BA_ "GenSigSendType" SG_ 1654 StSt_Koord_Stoppverbot_Anz_16 3;
BA_ "GenSigSwitchedByIgnition" SG_ 1654 StSt_Koord_Stoppverbot_Anz_16 0;
BA_ "GenSigSendType" SG_ 1654 StSt_Koord_Stoppverbot_Anz_17 3;
BA_ "GenSigSwitchedByIgnition" SG_ 1654 StSt_Koord_Stoppverbot_Anz_17 0;
BA_ "GenSigSendType" SG_ 1654 StSt_Koord_Stoppverbot_Anz_18 3;
BA_ "GenSigSwitchedByIgnition" SG_ 1654 StSt_Koord_Stoppverbot_Anz_18 0;
BA_ "GenSigSendType" SG_ 1654 StSt_Koord_Stoppverbot_Anz_19 3;
BA_ "GenSigSwitchedByIgnition" SG_ 1654 StSt_Koord_Stoppverbot_Anz_19 0;
BA_ "GenSigSendType" SG_ 1654 StSt_Koord_Stoppverbot_Anz_20 3;
BA_ "GenSigSwitchedByIgnition" SG_ 1654 StSt_Koord_Stoppverbot_Anz_20 0;
BA_ "GenSigSendType" SG_ 1654 StSt_Koord_Stoppverbot_Anz_21 3;
BA_ "GenSigSwitchedByIgnition" SG_ 1654 StSt_Koord_Stoppverbot_Anz_21 0;
BA_ "GenSigSendType" SG_ 1654 StSt_Koord_Stoppverbot_Anz_Std 3;
BA_ "GenSigSwitchedByIgnition" SG_ 1654 StSt_Koord_Stoppverbot_Anz_Std 0;
BA_ "GenSigSendType" SG_ 1654 StSt_Koord_Wiederstart_Anz_01 3;
BA_ "GenSigSwitchedByIgnition" SG_ 1654 StSt_Koord_Wiederstart_Anz_01 0;
BA_ "GenSigSendType" SG_ 1654 StSt_Koord_Wiederstart_Anz_02 3;
BA_ "GenSigSwitchedByIgnition" SG_ 1654 StSt_Koord_Wiederstart_Anz_02 0;
BA_ "GenSigSendType" SG_ 1654 StSt_Koord_Wiederstart_Anz_03 3;
BA_ "GenSigSwitchedByIgnition" SG_ 1654 StSt_Koord_Wiederstart_Anz_03 0;
BA_ "GenSigSendType" SG_ 1654 StSt_Koord_Wiederstart_Anz_04 3;
BA_ "GenSigSwitchedByIgnition" SG_ 1654 StSt_Koord_Wiederstart_Anz_04 0;
BA_ "GenSigSendType" SG_ 1654 StSt_Koord_Wiederstart_Anz_05 3;
BA_ "GenSigSwitchedByIgnition" SG_ 1654 StSt_Koord_Wiederstart_Anz_05 0;
BA_ "GenSigSendType" SG_ 1654 StSt_Koord_Wiederstart_Anz_06 3;
BA_ "GenSigSwitchedByIgnition" SG_ 1654 StSt_Koord_Wiederstart_Anz_06 0;
BA_ "GenSigSendType" SG_ 1654 StSt_Koord_Wiederstart_Anz_07 3;
BA_ "GenSigSwitchedByIgnition" SG_ 1654 StSt_Koord_Wiederstart_Anz_07 0;
BA_ "GenSigSendType" SG_ 1654 StSt_Koord_Wiederstart_Anz_08 3;
BA_ "GenSigSwitchedByIgnition" SG_ 1654 StSt_Koord_Wiederstart_Anz_08 0;
BA_ "GenSigSendType" SG_ 1654 StSt_Koord_Wiederstart_Anz_09 3;
BA_ "GenSigSwitchedByIgnition" SG_ 1654 StSt_Koord_Wiederstart_Anz_09 0;
BA_ "GenSigSendType" SG_ 1654 StSt_Koord_Wiederstart_Anz_10 3;
BA_ "GenSigSwitchedByIgnition" SG_ 1654 StSt_Koord_Wiederstart_Anz_10 0;
BA_ "GenSigSendType" SG_ 1654 StSt_Koord_Wiederstart_Anz_11 3;
BA_ "GenSigSwitchedByIgnition" SG_ 1654 StSt_Koord_Wiederstart_Anz_11 0;
BA_ "GenSigSendType" SG_ 1654 StSt_Koord_Wiederstart_Anz_Std 3;
BA_ "GenSigSwitchedByIgnition" SG_ 1654 StSt_Koord_Wiederstart_Anz_Std 0;
BA_REL_ "GenSigTimeoutTime" BU_SG_REL_ BedienSG_hi SG_ 1600 MO_QBit_Oel_Temp 3200;
BA_REL_ "GenSigTimeoutTime" BU_SG_REL_ BedienSG_hi SG_ 1600 MO_QBit_Kuehlmittel_Temp 3200;
BA_REL_ "GenSigTimeoutTime" BU_SG_REL_ BedienSG_hi SG_ 1600 MO_Oel_Temp 3200;
BA_REL_ "GenSigTimeoutTime" BU_SG_REL_ BedienSG_hi SG_ 1600 MO_Kuehlmittel_Temp 3200;
BA_REL_ "GenSigTimeoutTime" BU_SG_REL_ BedienSG_hi SG_ 168 MO_Drehzahl_01 500;
BA_REL_ "GenSigTimeoutTime" BU_SG_REL_ BedienSG_hi SG_ 958 MO_StartStopp_Status 1000;
BA_REL_ "GenSigTimeoutTime" BU_SG_REL_ BedienSG_hi SG_ 958 MO_StartStopp_Motorstopp 1000;
BA_REL_ "GenSigTimeoutTime" BU_SG_REL_ DDA SG_ 958 MO_Motor_laeuft 1000;
BA_REL_ "GenSigTimeoutTime" BU_SG_REL_ DDA SG_ 958 MO_Remotestart_Betrieb 1000;
BA_REL_ "GenSigTimeoutTime" BU_SG_REL_ OTA_FC SG_ 817 MFL_Signalhorn 5000;
BA_REL_ "GenSigTimeoutTime" BU_SG_REL_ OTA_FC SG_ 263 MO_KVS 500;
BA_REL_ "GenSigTimeoutTime" BU_SG_REL_ OTA_FC SG_ 1600 MO_Ansaugluft_Temp 3200;
BA_REL_ "GenSigTimeoutTime" BU_SG_REL_ OTA_FC SG_ 1600 MO_Oel_Temp 3200;
BA_REL_ "GenSigTimeoutTime" BU_SG_REL_ OTA_FC SG_ 1600 MO_Kuehlmittel_Temp 3200;
BA_REL_ "GenSigTimeoutTime" BU_SG_REL_ OTA_FC SG_ 1600 MO_Hoeheninfo 3200;
BA_REL_ "GenSigTimeoutTime" BU_SG_REL_ OTA_FC SG_ 1600 MO_Getriebe_kuehlen 3200;
BA_REL_ "GenSigTimeoutTime" BU_SG_REL_ OTA_FC SG_ 1607 MO_ITM_Kuehlmittel_Temp 3200;
BA_REL_ "GenSigTimeoutTime" BU_SG_REL_ OTA_FC SG_ 167 MO_Mom_Ist_Summe 2000;
BA_REL_ "GenSigTimeoutTime" BU_SG_REL_ OTA_FC SG_ 167 MO_Mom_Soll_gefiltert 2000;
BA_REL_ "GenSigTimeoutTime" BU_SG_REL_ OTA_FC SG_ 168 MO_Mom_Begr_dyn 500;
BA_REL_ "GenSigTimeoutTime" BU_SG_REL_ OTA_FC SG_ 168 MO_Drehzahl_01 500;
BA_REL_ "GenSigTimeoutTime" BU_SG_REL_ OTA_FC SG_ 958 MO_StartStopp_Wiederstart 1000;
BA_REL_ "GenSigTimeoutTime" BU_SG_REL_ OTA_FC SG_ 958 MO_Gangposition 1000;
BA_REL_ "GenSigTimeoutTime" BU_SG_REL_ OTA_FC SG_ 958 MO_Ext_E_Fahrt_aktiv 1000;
BA_REL_ "GenSigTimeoutTime" BU_SG_REL_ OTA_FC SG_ 958 MO_Kickdown 1000;
BA_REL_ "GenSigTimeoutTime" BU_SG_REL_ OTA_FC SG_ 1631 TSK_Fahrzeugmasse_02 3200;
BA_REL_ "GenSigTimeoutTime" BU_SG_REL_ OTA_FC SG_ 1631 TSK_Steigung_02 3200;
BA_REL_ "GenSigTimeoutTime" BU_SG_REL_ OTA_FC SG_ 289 MO_Fahrpedalrohwert_01 2000;
BA_REL_ "GenSigTimeoutTime" BU_SG_REL_ OTA_FC SG_ 289 MO_Fahrpedalgradient 2000;
BA_REL_ "GenSigTimeoutTime" BU_SG_REL_ OTA_FC SG_ 289 MO_StartStopp_StoppVorbereitung 2000;
BA_REL_ "GenSigTimeoutTime" BU_SG_REL_ ZR_High SG_ 1178 FS_Fond_Bed_enable 1000;
BA_REL_ "GenSigTimeoutTime" BU_SG_REL_ ZR_High SG_ 1178 FS_Lehne_nicht_verriegelt 1000;
BA_REL_ "GenSigTimeoutTime" BU_SG_REL_ ZR_High SG_ 1178 FS_Spezialposition_anfahren 1000;
BA_REL_ "GenSigTimeoutTime" BU_SG_REL_ ZR_High SG_ 1178 FS_Gurtbringer_Sperre 1000;
BA_REL_ "GenSigTimeoutTime" BU_SG_REL_ ZR_High SG_ 1178 FS_BFS_Sitzsym_Anfahrt 1000;
BA_REL_ "GenSigTimeoutTime" BU_SG_REL_ ZR_High SG_ 1178 FS_Sitzfahrt_aktiv 1000;
BA_REL_ "GenSigTimeoutTime" BU_SG_REL_ ZR_High SG_ 1178 FS_SLV_aktiv 1000;
BA_REL_ "GenSigTimeoutTime" BU_SG_REL_ ZR_High SG_ 1178 FS_SHV_aktiv 1000;
BA_REL_ "GenSigTimeoutTime" BU_SG_REL_ ZR_High SG_ 1178 FS_LNV_aktiv 1000;
BA_REL_ "GenSigTimeoutTime" BU_SG_REL_ ZR_High SG_ 1178 FS_SNV_aktiv 1000;
BA_REL_ "GenSigTimeoutTime" BU_SG_REL_ ZR_High SG_ 1178 FS_KSV_aktiv 1000;
BA_REL_ "GenSigTimeoutTime" BU_SG_REL_ ZR_High SG_ 1178 FS_LKV_aktiv 1000;
BA_REL_ "GenSigTimeoutTime" BU_SG_REL_ ZR_High SG_ 1178 FS_STV_aktiv 1000;
BA_REL_ "GenSigTimeoutTime" BU_SG_REL_ ZR_High SG_ 1178 FS_LHV_aktiv 1000;
BA_REL_ "GenSigTimeoutTime" BU_SG_REL_ ZR_High SG_ 1178 FS_LWV_aktiv 1000;
BA_REL_ "GenSigTimeoutTime" BU_SG_REL_ ZR_High SG_ 1178 FS_GHV_aktiv 1000;
BA_REL_ "GenSigTimeoutTime" BU_SG_REL_ ZR_High SG_ 1178 FS_BFS_KSS_Anfahrt 1000;
BA_REL_ "GenSigTimeoutTime" BU_SG_REL_ ZR_High SG_ 1178 FS_MMB_lokal_Stop 1000;
BA_REL_ "GenSigTimeoutTime" BU_SG_REL_ ZR_High SG_ 1178 FS_MMB_storage 1000;
BA_REL_ "GenSigTimeoutTime" BU_SG_REL_ ZR_High SG_ 1178 FS_MMB_tipp 1000;
BA_REL_ "GenSigTimeoutTime" BU_SG_REL_ ZR_High SG_ 1178 FS_MMB_tast 1000;
BA_REL_ "GenSigTimeoutTime" BU_SG_REL_ ZR_High SG_ 1178 FS_MMB_store_LED_on 1000;
BA_REL_ "GenSigTimeoutTime" BU_SG_REL_ ZR_High SG_ 1178 FS_MMB_store 1000;
BA_REL_ "GenSigTimeoutTime" BU_SG_REL_ ZR_High SG_ 1178 FS_MMB_glob_stop 1000;
BA_REL_ "GenSigTimeoutTime" BU_SG_REL_ ZR_High SG_ 1178 FS_EE_Fond_FS_enable 1000;
BA_REL_ "GenSigTimeoutTime" BU_SG_REL_ ZR_High SG_ 1178 FS_EE_Fond_BFS_enable 1000;
BA_REL_ "GenSigTimeoutTime" BU_SG_REL_ ZR_High SG_ 1178 FS_BFS_Fond_Verst_enable 1000;
BA_REL_ "GenSigTimeoutTime" BU_SG_REL_ ZR_High SG_ 1178 FS_EE_BFS_enable 1000;
BA_REL_ "GenSigTimeoutTime" BU_SG_REL_ ZR_High SG_ 954 Mem_FS_Lordose_hoch 1000;
BA_REL_ "GenSigTimeoutTime" BU_SG_REL_ ZR_High SG_ 954 Mem_FS_Lordose_runter 1000;
BA_REL_ "GenSigTimeoutTime" BU_SG_REL_ ZR_High SG_ 954 Mem_FS_Lordose_vor 1000;
BA_REL_ "GenSigTimeoutTime" BU_SG_REL_ ZR_High SG_ 954 Mem_FS_Lordose_zurueck 1000;
BA_REL_ "GenSigTimeoutTime" BU_SG_REL_ ZR_High SG_ 954 Mem_FS_Massage_Geschw 1000;
BA_REL_ "GenSigTimeoutTime" BU_SG_REL_ ZR_High SG_ 954 Mem_FS_Massage_Intensitaet 1000;
BA_REL_ "GenSigTimeoutTime" BU_SG_REL_ ZR_High SG_ 954 Mem_FS_SWangenLehne_beluef 1000;
BA_REL_ "GenSigTimeoutTime" BU_SG_REL_ ZR_High SG_ 954 Mem_FS_SWangenLehne_entlue 1000;
BA_REL_ "GenSigTimeoutTime" BU_SG_REL_ ZR_High SG_ 954 Mem_FS_SWangenSitz_beluef 1000;
BA_REL_ "GenSigTimeoutTime" BU_SG_REL_ ZR_High SG_ 954 Mem_FS_SWangenSitz_entlue 1000;
BA_REL_ "GenSigTimeoutTime" BU_SG_REL_ ZR_High SG_ 954 FS_BFS_aufraeumen 1000;
BA_REL_ "GenSigTimeoutTime" BU_SG_REL_ ZR_High SG_ 954 FS_BFSFo_aufraeumen 1000;
BA_REL_ "GenSigTimeoutTime" BU_SG_REL_ ZR_High SG_ 954 FS_FSFo_aufraeumen 1000;
BA_REL_ "GenSigTimeoutTime" BU_SG_REL_ ZR_High SG_ 954 FS_Remote_Multif_Taster_hoch 1000;
BA_REL_ "GenSigTimeoutTime" BU_SG_REL_ ZR_High SG_ 954 FS_Remote_Multif_Taster_tief 1000;
BA_REL_ "GenSigTimeoutTime" BU_SG_REL_ ZR_High SG_ 954 FS_Remote_Multif_Taster_vor 1000;
BA_REL_ "GenSigTimeoutTime" BU_SG_REL_ ZR_High SG_ 954 FS_Remote_Multif_Taster_zurueck 1000;
BA_REL_ "GenSigTimeoutTime" BU_SG_REL_ ZR_High SG_ 954 FS_Remote_Programmwippe_hoch 1000;
BA_REL_ "GenSigTimeoutTime" BU_SG_REL_ ZR_High SG_ 954 FS_Remote_Programmwippe_tief 1000;
BA_REL_ "GenSigTimeoutTime" BU_SG_REL_ ZR_High SG_ 954 FS_Remote_SHV_Taste_hoch 1000;
BA_REL_ "GenSigTimeoutTime" BU_SG_REL_ ZR_High SG_ 954 FS_Remote_SHV_Taste_tief 1000;
BA_REL_ "GenSigTimeoutTime" BU_SG_REL_ ZR_High SG_ 954 FS_Remote_SLV_Taste_vor 1000;
BA_REL_ "GenSigTimeoutTime" BU_SG_REL_ ZR_High SG_ 954 FS_Remote_SLV_Taste_zurueck 1000;
BA_REL_ "GenSigTimeoutTime" BU_SG_REL_ ZR_High SG_ 954 FS_Remote_SNV_Taste_hoch 1000;
BA_REL_ "GenSigTimeoutTime" BU_SG_REL_ ZR_High SG_ 954 FS_Remote_SNV_Taste_tief 1000;
BA_REL_ "GenSigTimeoutTime" BU_SG_REL_ ZR_High SG_ 954 FS_Remote_KSV_Taste_hoch 1000;
BA_REL_ "GenSigTimeoutTime" BU_SG_REL_ ZR_High SG_ 954 FS_Remote_KSV_Taste_tief 1000;
BA_REL_ "GenSigTimeoutTime" BU_SG_REL_ ZR_High SG_ 954 FS_Remote_LNV_Taste_vor 1000;
BA_REL_ "GenSigTimeoutTime" BU_SG_REL_ ZR_High SG_ 954 FS_Remote_LNV_Taste_zurueck 1000;
BA_REL_ "GenSigTimeoutTime" BU_SG_REL_ ZR_High SG_ 954 FS_Remote_Massage_Taste 1000;
BA_REL_ "GenSigTimeoutTime" BU_SG_REL_ ZR_High SG_ 954 FS_RemoteTarget 1000;
BA_REL_ "GenSigTimeoutTime" BU_SG_REL_ ZR_High SG_ 954 FS_Remote_KSV_Taste_vor 1000;
BA_REL_ "GenSigTimeoutTime" BU_SG_REL_ ZR_High SG_ 954 FS_Remote_KSV_Taste_zurueck 1000;
BA_REL_ "GenSigTimeoutTime" BU_SG_REL_ ZR_High SG_ 954 FS_Remote_STV_Taste_vor 1000;
BA_REL_ "GenSigTimeoutTime" BU_SG_REL_ ZR_High SG_ 954 FS_Remote_STV_Taste_zurueck 1000;
BA_REL_ "GenSigTimeoutTime" BU_SG_REL_ ZR_High SG_ 954 FS_Remote_SWV_Taste_eng 1000;
BA_REL_ "GenSigTimeoutTime" BU_SG_REL_ ZR_High SG_ 954 FS_Remote_SWV_Taste_breit 1000;
BA_REL_ "GenSigTimeoutTime" BU_SG_REL_ ZR_High SG_ 954 FS_Remote_LWV_Taste_eng 1000;
BA_REL_ "GenSigTimeoutTime" BU_SG_REL_ ZR_High SG_ 954 FS_Remote_LWV_Taste_breit 1000;
BA_REL_ "GenSigTimeoutTime" BU_SG_REL_ ZR_High SG_ 954 FS_Remote_LKV_Taste_vor 1000;
BA_REL_ "GenSigTimeoutTime" BU_SG_REL_ ZR_High SG_ 954 FS_Remote_LKV_Taste_zurueck 1000;
BA_REL_ "GenSigTimeoutTime" BU_SG_REL_ ZR_High SG_ 954 FS_MMB_Sys_Fahrt_aktiv 1000;
BA_REL_ "GenSigTimeoutTime" BU_SG_REL_ ZR_High SG_ 956 Mem_FSFo_Lordose_hoch 1000;
BA_REL_ "GenSigTimeoutTime" BU_SG_REL_ ZR_High SG_ 956 Mem_FSFo_Lordose_runter 1000;
BA_REL_ "GenSigTimeoutTime" BU_SG_REL_ ZR_High SG_ 956 Mem_FSFo_Lordose_vor 1000;
BA_REL_ "GenSigTimeoutTime" BU_SG_REL_ ZR_High SG_ 956 Mem_FSFo_Lordose_zurueck 1000;
BA_REL_ "GenSigTimeoutTime" BU_SG_REL_ ZR_High SG_ 956 Mem_FSFo_Massage_Geschw 1000;
BA_REL_ "GenSigTimeoutTime" BU_SG_REL_ ZR_High SG_ 956 Mem_FSFo_Massage_Intens 1000;
BA_REL_ "GenSigTimeoutTime" BU_SG_REL_ ZR_High SG_ 956 Mem_FSFo_MMB_storage 1000;
BA_REL_ "GenSigTimeoutTime" BU_SG_REL_ ZR_High SG_ 956 Mem_FSFo_Massage_Prg 1000;
BA_REL_ "GenSigTimeoutTime" BU_SG_REL_ ZR_High SG_ 956 Mem_FSFo_MMB_tast 1000;
BA_REL_ "GenSigTimeoutTime" BU_SG_REL_ ZR_High SG_ 956 Mem_FSFo_MMB_tipp 1000;
BA_REL_ "GenSigTimeoutTime" BU_SG_REL_ ZR_High SG_ 956 Mem_FSFo_MMB_glob_Stop 1000;
BA_REL_ "GenSigTimeoutTime" BU_SG_REL_ ZR_High SG_ 956 Mem_FSFo_Sitztiefe_vor 1000;
BA_REL_ "GenSigTimeoutTime" BU_SG_REL_ ZR_High SG_ 956 Mem_FSFo_Sitztiefe_zur 1000;
BA_REL_ "GenSigTimeoutTime" BU_SG_REL_ ZR_High SG_ 956 Mem_FSFo_MMB_store 1000;
BA_REL_ "GenSigTimeoutTime" BU_SG_REL_ ZR_High SG_ 956 Mem_FSFo_MMB_storage_beep 1000;
BA_REL_ "GenSigTimeoutTime" BU_SG_REL_ ZR_High SG_ 956 Mem_FSFo_MMB_store_LED_on 1000;
BA_REL_ "GenSigTimeoutTime" BU_SG_REL_ ZR_High SG_ 956 Mem_FSFo_MMB_lokal_Stop 1000;
BA_REL_ "GenSigTimeoutTime" BU_SG_REL_ ZR_High SG_ 956 Mem_FSFo_Sitzfahrt_aktiv 1000;
BA_REL_ "GenSigTimeoutTime" BU_SG_REL_ ZR_High SG_ 956 Mem_FSFo_Business_anfahren 1000;
BA_REL_ "GenSigTimeoutTime" BU_SG_REL_ ZR_High SG_ 956 Mem_FSFo_Relax_anfahren 1000;
BA_REL_ "GenSigTimeoutTime" BU_SG_REL_ ZR_High SG_ 1180 MTBT_Pos1 1000;
BA_REL_ "GenSigTimeoutTime" BU_SG_REL_ ZR_High SG_ 1180 MTBT_Pos2 1000;
BA_REL_ "GenSigTimeoutTime" BU_SG_REL_ ZR_High SG_ 1180 MTBT_Pos3 1000;
BA_REL_ "GenSigTimeoutTime" BU_SG_REL_ ZR_High SG_ 1180 MTBT_Pos4 1000;
BA_REL_ "GenSigTimeoutTime" BU_SG_REL_ ZR_High SG_ 1180 MTBT_On_Off 1000;
BA_REL_ "GenSigTimeoutTime" BU_SG_REL_ ZR_High SG_ 1180 MTBT_M_Taste 1000;
BA_REL_ "GenSigTimeoutTime" BU_SG_REL_ ZR_High SG_ 1170 MTFT_Pos1_EE 1000;
BA_REL_ "GenSigTimeoutTime" BU_SG_REL_ ZR_High SG_ 1170 MTFT_Pos2 1000;
BA_REL_ "GenSigTimeoutTime" BU_SG_REL_ ZR_High SG_ 1170 MTFT_Pos3 1000;
BA_REL_ "GenSigTimeoutTime" BU_SG_REL_ ZR_High SG_ 1170 MTFT_Pos4 1000;
BA_REL_ "GenSigTimeoutTime" BU_SG_REL_ ZR_High SG_ 1170 MTFT_On_Off 1000;
BA_REL_ "GenSigTimeoutTime" BU_SG_REL_ ZR_High SG_ 1170 MTFT_Verst_akt 1000;
BA_REL_ "GenSigTimeoutTime" BU_SG_REL_ ZR_High SG_ 1170 MTFT_M_Taste 1000;
BA_REL_ "GenSigTimeoutTime" BU_SG_REL_ ZR_High SG_ 1173 BFS_Sitzhoehe_hoch 1000;
BA_REL_ "GenSigTimeoutTime" BU_SG_REL_ ZR_High SG_ 1173 BFS_Sitzhoehe_runter 1000;
BA_REL_ "GenSigTimeoutTime" BU_SG_REL_ ZR_High SG_ 1173 MTHBF_ein 1000;
BA_REL_ "GenSigTimeoutTime" BU_SG_REL_ ZR_High SG_ 1173 BFS_Laengsverst_vor 1000;
BA_REL_ "GenSigTimeoutTime" BU_SG_REL_ ZR_High SG_ 1173 BFS_Laengsverst_zurueck 1000;
BA_REL_ "GenSigTimeoutTime" BU_SG_REL_ ZR_High SG_ 1173 BFS_Lehnenneigung_vor 1000;
BA_REL_ "GenSigTimeoutTime" BU_SG_REL_ ZR_High SG_ 1173 BFS_Lehnenneigung_zurueck 1000;
BA_REL_ "GenSigTimeoutTime" BU_SG_REL_ ZR_High SG_ 1173 BFS_Lehnenkopf_vor 1000;
BA_REL_ "GenSigTimeoutTime" BU_SG_REL_ ZR_High SG_ 1173 BFS_Lehnenkopf_zurueck 1000;
BA_REL_ "GenSigTimeoutTime" BU_SG_REL_ ZR_High SG_ 1173 BFS_Kopfstuetzen_hoch 1000;
BA_REL_ "GenSigTimeoutTime" BU_SG_REL_ ZR_High SG_ 1173 BFS_Kopfstuetzen_runter 1000;
BA_REL_ "GenSigTimeoutTime" BU_SG_REL_ ZR_High SG_ 817 MFL_M_Taste 5000;
BA_REL_ "GenSigTimeoutTime" BU_SG_REL_ ZR_High SG_ 817 MFL_Paddle_Verbau 5000;
BA_REL_ "GenSigTimeoutTime" BU_SG_REL_ ZR_High SG_ 817 MFL_Tip_Down 5000;
BA_REL_ "GenSigTimeoutTime" BU_SG_REL_ ZR_High SG_ 817 MFL_Tip_Up 5000;
BA_REL_ "GenSigTimeoutTime" BU_SG_REL_ ZR_High SG_ 817 MFL_SatModul_links_Err 5000;
BA_REL_ "GenSigTimeoutTime" BU_SG_REL_ ZR_High SG_ 817 MFL_SatModul_rechts_Err 5000;
BA_REL_ "GenSigTimeoutTime" BU_SG_REL_ ZR_High SG_ 817 MFL_LR_HZG_Status 5000;
BA_REL_ "GenSigTimeoutTime" BU_SG_REL_ ZR_High SG_ 817 MFL_LR_HZG_Err 5000;
BA_REL_ "GenSigTimeoutTime" BU_SG_REL_ ZR_High SG_ 817 MFL_Signalhorn 5000;
BA_REL_ "GenSigTimeoutTime" BU_SG_REL_ ZR_High SG_ 817 MFL_Signalhorn_Err 5000;
BA_REL_ "GenSigTimeoutTime" BU_SG_REL_ ZR_High SG_ 817 MFL_Tip_links_Err 5000;
BA_REL_ "GenSigTimeoutTime" BU_SG_REL_ ZR_High SG_ 817 MFL_Tip_rechts_Err 5000;
BA_REL_ "GenSigTimeoutTime" BU_SG_REL_ ZR_High SG_ 817 MFL_Taste_links_Err 5000;
BA_REL_ "GenSigTimeoutTime" BU_SG_REL_ ZR_High SG_ 817 MFL_Taste_rechts_Err 5000;
BA_REL_ "GenSigTimeoutTime" BU_SG_REL_ ZR_High SG_ 817 MFL_ECU_Err 5000;
BA_REL_ "GenSigTimeoutTime" BU_SG_REL_ ZR_High SG_ 263 MO_rel_Ladedruck 500;
BA_REL_ "GenSigTimeoutTime" BU_SG_REL_ ZR_High SG_ 263 MO_Istgang 500;
BA_REL_ "GenSigTimeoutTime" BU_SG_REL_ ZR_High SG_ 263 MO_Sollgang 500;
BA_REL_ "GenSigTimeoutTime" BU_SG_REL_ ZR_High SG_ 263 MO_Anzeigedrehz 500;
BA_REL_ "GenSigTimeoutTime" BU_SG_REL_ ZR_High SG_ 263 MO_Schaltempf_verfbar 500;
BA_REL_ "GenSigTimeoutTime" BU_SG_REL_ ZR_High SG_ 1600 MO_Oel_Temp 3200;
BA_REL_ "GenSigTimeoutTime" BU_SG_REL_ ZR_High SG_ 1600 MO_Kuehlmittel_Temp 3200;
BA_REL_ "GenSigTimeoutTime" BU_SG_REL_ ZR_High SG_ 1600 MO_Hoeheninfo 3200;
BA_REL_ "GenSigTimeoutTime" BU_SG_REL_ ZR_High SG_ 1600 MO_QBit_Hoeheninfo 3200;
BA_REL_ "GenSigTimeoutTime" BU_SG_REL_ ZR_High SG_ 1607 MO_ITM_Kuehlmittel_Temp 3200;
BA_REL_ "GenSigTimeoutTime" BU_SG_REL_ ZR_High SG_ 1607 SCR_Reichweite 3200;
BA_REL_ "GenSigTimeoutTime" BU_SG_REL_ ZR_High SG_ 1607 SCR_Warnstufe_1 3200;
BA_REL_ "GenSigTimeoutTime" BU_SG_REL_ ZR_High SG_ 1607 SCR_Warnstufe_2 3200;
BA_REL_ "GenSigTimeoutTime" BU_SG_REL_ ZR_High SG_ 1607 SCR_verbaut 3200;
BA_REL_ "GenSigTimeoutTime" BU_SG_REL_ ZR_High SG_ 1607 MO_Kraftstofffilter_Wasser 3200;
BA_REL_ "GenSigTimeoutTime" BU_SG_REL_ ZR_High SG_ 1607 SCR_Systemfehler 3200;
BA_REL_ "GenSigTimeoutTime" BU_SG_REL_ ZR_High SG_ 1607 MO_MKB_MUX 3200;
BA_REL_ "GenSigTimeoutTime" BU_SG_REL_ ZR_High SG_ 1607 MO_MKB_01 3200;
BA_REL_ "GenSigTimeoutTime" BU_SG_REL_ ZR_High SG_ 1607 MO_MKB_02 3200;
BA_REL_ "GenSigTimeoutTime" BU_SG_REL_ ZR_High SG_ 1607 MO_MKB_03 3200;
BA_REL_ "GenSigTimeoutTime" BU_SG_REL_ ZR_High SG_ 1607 MO_MKB_04 3200;
BA_REL_ "GenSigTimeoutTime" BU_SG_REL_ ZR_High SG_ 167 MO_Mom_Ist_Summe 2000;
BA_REL_ "GenSigTimeoutTime" BU_SG_REL_ ZR_High SG_ 168 MO_Drehzahl_01 500;
BA_REL_ "GenSigTimeoutTime" BU_SG_REL_ ZR_High SG_ 958 MO_StartStopp_Wiederstart 1000;
BA_REL_ "GenSigTimeoutTime" BU_SG_REL_ ZR_High SG_ 958 MO_StartStopp_Motorstopp 1000;
BA_REL_ "GenSigTimeoutTime" BU_SG_REL_ ZR_High SG_ 958 MO_Kl_75 1000;
BA_REL_ "GenSigTimeoutTime" BU_SG_REL_ ZR_High SG_ 958 MO_Kl_50 1000;
BA_REL_ "GenSigTimeoutTime" BU_SG_REL_ ZR_High SG_ 958 MO_Gangposition 1000;
BA_REL_ "GenSigTimeoutTime" BU_SG_REL_ ZR_High SG_ 958 MO_StartStopp_Fahrerwunsch 1000;
BA_REL_ "GenSigTimeoutTime" BU_SG_REL_ ZR_High SG_ 958 MO_Ext_E_Fahrt_aktiv 1000;
BA_REL_ "GenSigTimeoutTime" BU_SG_REL_ ZR_High SG_ 958 MO_Fahrer_bremst 1000;
BA_REL_ "GenSigTimeoutTime" BU_SG_REL_ ZR_High SG_ 958 MO_QBit_Fahrer_bremst 1000;
BA_REL_ "GenSigTimeoutTime" BU_SG_REL_ ZR_High SG_ 958 MO_BLS 1000;
BA_REL_ "GenSigTimeoutTime" BU_SG_REL_ ZR_High SG_ 958 MO_Kuppl_schalter 1000;
BA_REL_ "GenSigTimeoutTime" BU_SG_REL_ ZR_High SG_ 958 MO_Kickdown 1000;
BA_REL_ "GenSigTimeoutTime" BU_SG_REL_ ZR_High SG_ 958 MO_QBit_KL_75 1000;
BA_REL_ "GenSigTimeoutTime" BU_SG_REL_ ZR_High SG_ 958 MO_Zylinderabschaltung 1000;
BA_REL_ "GenSigTimeoutTime" BU_SG_REL_ ZR_High SG_ 1631 TSK_Grundmasse 3200;
BA_REL_ "GenSigTimeoutTime" BU_SG_REL_ ZR_High SG_ 1631 TSK_QBit_Fahrzeugmasse 3200;
BA_REL_ "GenSigTimeoutTime" BU_SG_REL_ ZR_High SG_ 1631 MO_DPF_reg 3200;
BA_REL_ "GenSigTimeoutTime" BU_SG_REL_ ZR_High SG_ 1631 TSK_Fahrzeugmasse_02 3200;
BA_REL_ "GenSigTimeoutTime" BU_SG_REL_ ZR_High SG_ 1648 MO_max_Ladedruck 5000;
BA_REL_ "GenSigTimeoutTime" BU_SG_REL_ ZR_High SG_ 289 MO_Fahrpedalrohwert_01 2000;
BA_REL_ "GenSigTimeoutTime" BU_SG_REL_ ZR_High SG_ 289 MO_QBit_Fahrpedalwerte_01 2000;
BA_REL_ "GenSigTimeoutTime" BU_SG_REL_ ZR_High SG_ 289 MO_Fahrpedalgradient 2000;
BA_REL_ "GenSigTimeoutTime" BU_SG_REL_ ZR_High SG_ 289 MO_Sig_Fahrpedalgradient 2000;
BA_REL_ "GenSigTimeoutTime" BU_SG_REL_ ZR_High SG_ 289 MO_Moment_im_Leerlauf 2000;
BA_REL_ "GenSigTimeoutTime" BU_SG_REL_ ZR_High SG_ 1654 MO_Wiederstart_Anz_01 5000;
BA_REL_ "GenSigTimeoutTime" BU_SG_REL_ ZR_High SG_ 1654 MO_Wiederstart_Anz_02 5000;
BA_REL_ "GenSigTimeoutTime" BU_SG_REL_ ZR_High SG_ 1654 MO_Wiederstart_Anz_03 5000;
BA_REL_ "GenSigTimeoutTime" BU_SG_REL_ ZR_High SG_ 1654 MO_Wiederstart_Anz_Std 5000;
BA_REL_ "GenSigTimeoutTime" BU_SG_REL_ ZR_High SG_ 1654 MO_Stoppverbot_Anz_01 5000;
BA_REL_ "GenSigTimeoutTime" BU_SG_REL_ ZR_High SG_ 1654 MO_Stoppverbot_Anz_02 5000;
BA_REL_ "GenSigTimeoutTime" BU_SG_REL_ ZR_High SG_ 1654 MO_Stoppverbot_Anz_03 5000;
BA_REL_ "GenSigTimeoutTime" BU_SG_REL_ ZR_High SG_ 1654 MO_Stoppverbot_Anz_04 5000;
BA_REL_ "GenSigTimeoutTime" BU_SG_REL_ ZR_High SG_ 1654 MO_Stoppverbot_Anz_05 5000;
BA_REL_ "GenSigTimeoutTime" BU_SG_REL_ ZR_High SG_ 1654 MO_Stoppverbot_Anz_06 5000;
BA_REL_ "GenSigTimeoutTime" BU_SG_REL_ ZR_High SG_ 1654 MO_Stoppverbot_Anz_07 5000;
BA_REL_ "GenSigTimeoutTime" BU_SG_REL_ ZR_High SG_ 1654 MO_Stoppverbot_Anz_08 5000;
BA_REL_ "GenSigTimeoutTime" BU_SG_REL_ ZR_High SG_ 1654 MO_Stoppverbot_Anz_09 5000;
BA_REL_ "GenSigTimeoutTime" BU_SG_REL_ ZR_High SG_ 1654 MO_Stoppverbot_Anz_10 5000;
BA_REL_ "GenSigTimeoutTime" BU_SG_REL_ ZR_High SG_ 1654 MO_Stoppverbot_Anz_11 5000;
BA_REL_ "GenSigTimeoutTime" BU_SG_REL_ ZR_High SG_ 1654 MO_Stoppverbot_Anz_Std 5000;
BA_REL_ "GenSigTimeoutTime" BU_SG_REL_ ZR_High SG_ 1654 StSt_Koord_Status_Bremspedalkzpt 5000;
BA_REL_ "GenSigTimeoutTime" BU_SG_REL_ ZR_High SG_ 1654 StSt_Koord_Stoppverbot_Anz_01 5000;
BA_REL_ "GenSigTimeoutTime" BU_SG_REL_ ZR_High SG_ 1654 StSt_Koord_Stoppverbot_Anz_02 5000;
BA_REL_ "GenSigTimeoutTime" BU_SG_REL_ ZR_High SG_ 1654 StSt_Koord_Stoppverbot_Anz_03 5000;
BA_REL_ "GenSigTimeoutTime" BU_SG_REL_ ZR_High SG_ 1654 StSt_Koord_Stoppverbot_Anz_04 5000;
BA_REL_ "GenSigTimeoutTime" BU_SG_REL_ ZR_LIMU SG_ 263 MO_rel_Ladedruck 500;
BA_REL_ "GenSigTimeoutTime" BU_SG_REL_ ZR_LIMU SG_ 263 MO_Istgang 500;
BA_REL_ "GenSigTimeoutTime" BU_SG_REL_ ZR_LIMU SG_ 263 MO_Sollgang 500;
BA_REL_ "GenSigTimeoutTime" BU_SG_REL_ ZR_LIMU SG_ 263 MO_Anzeigedrehz 500;
BA_REL_ "GenSigTimeoutTime" BU_SG_REL_ ZR_LIMU SG_ 263 MO_Schaltempf_verfbar 500;
BA_REL_ "GenSigTimeoutTime" BU_SG_REL_ ZR_LIMU SG_ 168 MO_QBit_Drehzahl_01 500;
BA_REL_ "GenSigTimeoutTime" BU_SG_REL_ ZR_LIMU SG_ 168 MO_Drehzahl_01 500;
BA_REL_ "GenSigTimeoutTime" BU_SG_REL_ ZR_LIMU SG_ 958 MO_StartStopp_Wiederstart 1000;
BA_REL_ "GenSigTimeoutTime" BU_SG_REL_ ZR_LIMU SG_ 958 MO_Kl_75 1000;
BA_REL_ "GenSigTimeoutTime" BU_SG_REL_ ZR_LIMU SG_ 958 MO_Kl_50 1000;
BA_REL_ "GenSigTimeoutTime" BU_SG_REL_ ZR_LIMU SG_ 958 MO_Fahrer_bremst 1000;
BA_REL_ "GenSigTimeoutTime" BU_SG_REL_ ZR_LIMU SG_ 958 MO_QBit_Fahrer_bremst 1000;
BA_REL_ "GenSigTimeoutTime" BU_SG_REL_ ZR_LIMU SG_ 958 MO_Kuppl_schalter 1000;
BA_REL_ "GenSigTimeoutTime" BU_SG_REL_ ZR_LIMU SG_ 958 MO_Kickdown 1000;
BA_REL_ "GenSigTimeoutTime" BU_SG_REL_ ZR_LIMU SG_ 1648 MO_max_Ladedruck 5000;
BA_REL_ "GenSigTimeoutTime" BU_SG_REL_ ZR_LIMU SG_ 1648 MO_ANC_Kennfeld_Anf 5000;
BA_REL_ "GenSigTimeoutTime" BU_SG_REL_ ZR_LIMU SG_ 1648 MO_Fehler_Zylabsch 5000;
BA_REL_ "GenSigTimeoutTime" BU_SG_REL_ ZR_LIMU SG_ 289 MO_Fahrpedalrohwert_01 2000;
BA_REL_ "GenSigTimeoutTime" BU_SG_REL_ ZR_LIMU SG_ 289 MO_QBit_Fahrpedalwerte_01 2000;
BA_REL_ "GenSigTimeoutTime" BU_SG_REL_ ZR_MIB_TOP_ab_Gen3 SG_ 263 MO_rel_Ladedruck 500;
BA_REL_ "GenSigTimeoutTime" BU_SG_REL_ ZR_MIB_TOP_ab_Gen3 SG_ 263 MO_Istgang 500;
BA_REL_ "GenSigTimeoutTime" BU_SG_REL_ ZR_MIB_TOP_ab_Gen3 SG_ 263 MO_Sollgang 500;
BA_REL_ "GenSigTimeoutTime" BU_SG_REL_ ZR_MIB_TOP_ab_Gen3 SG_ 263 MO_Anzeigedrehz 500;
BA_REL_ "GenSigTimeoutTime" BU_SG_REL_ ZR_MIB_TOP_ab_Gen3 SG_ 263 MO_Schaltempf_verfbar 500;
BA_REL_ "GenSigTimeoutTime" BU_SG_REL_ ZR_MIB_TOP_ab_Gen3 SG_ 168 MO_QBit_Drehzahl_01 500;
BA_REL_ "GenSigTimeoutTime" BU_SG_REL_ ZR_MIB_TOP_ab_Gen3 SG_ 168 MO_Drehzahl_01 500;
BA_REL_ "GenSigTimeoutTime" BU_SG_REL_ ZR_MIB_TOP_ab_Gen3 SG_ 958 MO_Kl_75 1000;
BA_REL_ "GenSigTimeoutTime" BU_SG_REL_ ZR_MIB_TOP_ab_Gen3 SG_ 958 MO_Kl_50 1000;
BA_REL_ "GenSigTimeoutTime" BU_SG_REL_ ZR_MIB_TOP_ab_Gen3 SG_ 958 MO_Fahrer_bremst 1000;
BA_REL_ "GenSigTimeoutTime" BU_SG_REL_ ZR_MIB_TOP_ab_Gen3 SG_ 958 MO_QBit_Fahrer_bremst 1000;
BA_REL_ "GenSigTimeoutTime" BU_SG_REL_ ZR_MIB_TOP_ab_Gen3 SG_ 958 MO_Kuppl_schalter 1000;
BA_REL_ "GenSigTimeoutTime" BU_SG_REL_ ZR_MIB_TOP_ab_Gen3 SG_ 958 MO_Kickdown 1000;
BA_REL_ "GenSigTimeoutTime" BU_SG_REL_ ZR_MIB_TOP_ab_Gen3 SG_ 1648 MO_max_Ladedruck 5000;
BA_REL_ "GenSigTimeoutTime" BU_SG_REL_ ZR_MIB_TOP_ab_Gen3 SG_ 1648 MO_ANC_Kennfeld_Anf 5000;
BA_REL_ "GenSigTimeoutTime" BU_SG_REL_ ZR_MIB_TOP_ab_Gen3 SG_ 1648 MO_Fehler_Zylabsch 5000;
BA_REL_ "GenSigTimeoutTime" BU_SG_REL_ ZR_MIB_TOP_ab_Gen3 SG_ 289 MO_Fahrpedalrohwert_01 2000;
BA_REL_ "GenSigTimeoutTime" BU_SG_REL_ ZR_MIB_TOP_ab_Gen3 SG_ 289 MO_QBit_Fahrpedalwerte_01 2000;
BA_REL_ "GenSigTimeoutTime" BU_SG_REL_ ZR_Standard SG_ 263 MO_rel_Ladedruck 500;
BA_REL_ "GenSigTimeoutTime" BU_SG_REL_ ZR_Standard SG_ 263 MO_Istgang 500;
BA_REL_ "GenSigTimeoutTime" BU_SG_REL_ ZR_Standard SG_ 263 MO_Sollgang 500;
BA_REL_ "GenSigTimeoutTime" BU_SG_REL_ ZR_Standard SG_ 263 MO_Anzeigedrehz 500;
BA_REL_ "GenSigTimeoutTime" BU_SG_REL_ ZR_Standard SG_ 263 MO_Schaltempf_verfbar 500;
BA_REL_ "GenSigTimeoutTime" BU_SG_REL_ ZR_Standard SG_ 167 MO_Mom_Ist_Summe 2000;
BA_REL_ "GenSigTimeoutTime" BU_SG_REL_ ZR_Standard SG_ 168 MO_Drehzahl_01 500;
BA_REL_ "GenSigTimeoutTime" BU_SG_REL_ ZR_Standard SG_ 958 MO_Kl_75 1000;
BA_REL_ "GenSigTimeoutTime" BU_SG_REL_ ZR_Standard SG_ 958 MO_Kl_50 1000;
BA_REL_ "GenSigTimeoutTime" BU_SG_REL_ ZR_Standard SG_ 958 MO_Fahrer_bremst 1000;
BA_REL_ "GenSigTimeoutTime" BU_SG_REL_ ZR_Standard SG_ 958 MO_QBit_Fahrer_bremst 1000;
BA_REL_ "GenSigTimeoutTime" BU_SG_REL_ ZR_Standard SG_ 958 MO_Kuppl_schalter 1000;
BA_REL_ "GenSigTimeoutTime" BU_SG_REL_ ZR_Standard SG_ 958 MO_Kickdown 1000;
BA_REL_ "GenSigTimeoutTime" BU_SG_REL_ ZR_Standard SG_ 1648 MO_max_Ladedruck 5000;
BA_REL_ "GenSigTimeoutTime" BU_SG_REL_ ZR_Standard SG_ 289 MO_Fahrpedalrohwert_01 2000;
BA_REL_ "GenSigTimeoutTime" BU_SG_REL_ ZR_Standard SG_ 289 MO_QBit_Fahrpedalwerte_01 2000;
VAL_ 1178 FS_Fond_Bed_enable 0 "disable" 1 "enable" ;
VAL_ 1178 FS_Lehne_nicht_verriegelt 0 "keine Anzeige" 1 "Lehne_nicht_verriegelt" ;
VAL_ 1178 FS_Spezialposition_anfahren 0 "Fkt_inaktiv" 1 "Fkt_aktiv" ;
VAL_ 1178 FS_Gurtbringer_Sperre 0 "Gurtzubringer_freigegeben" 1 "Gurtzubringer_gesperrt" ;
VAL_ 1178 FS_BFS_Sitzsym_Anfahrt 0 "keine Sitzsymetrie Anfahrt BFS" 1 "Sitzsymetrie Anfahrt BFS" ;
VAL_ 1178 FS_Sitzfahrt_aktiv 0 "Sitz_nicht_in_Bewegung" 1 "Sitz_in_Bewegung" ;
VAL_ 1178 FS_SLV_aktiv 0 "nicht_aktiv" 1 "Sitzlaengsverstellung aktiv" ;
VAL_ 1178 FS_SHV_aktiv 0 "nicht_aktiv" 1 "Sitzhoehenverstellung aktiv" ;
VAL_ 1178 FS_LNV_aktiv 0 "nicht_aktiv" 1 "Lehnenneigungverstellung aktiv" ;
VAL_ 1178 FS_SNV_aktiv 0 "nicht_aktiv" 1 "Sitzneigungsverstellung_aktiv" ;
VAL_ 1178 FS_KSV_aktiv 0 "nicht_aktiv" 1 "Kopfstuetzenverstellung aktiv" ;
VAL_ 1178 FS_LKV_aktiv 0 "nicht_aktiv" 1 "Lehnenkopfverstellung aktiv" ;
VAL_ 1178 FS_STV_aktiv 0 "nicht_aktiv" 1 "Sitztiefeverstellung aktiv" ;
VAL_ 1178 FS_LHV_aktiv 0 "nicht_aktiv" 1 "Lordose Höhe Verstellung aktiv" ;
VAL_ 1178 FS_LWV_aktiv 0 "nicht_aktiv" 1 "Lordose W Verstellung aktiv" ;
VAL_ 1178 FS_GHV_aktiv 0 "nicht_aktiv" 1 "Gurthoehenverstellung aktiv" ;
VAL_ 1178 FS_BFS_KSS_Anfahrt 0 "keine Anfahrt KSS BFS" 1 "Anfahrt KSS BFS" ;
VAL_ 1178 FS_MMB_lokal_Stop 0 "kein_Abbruch" 1 "lokaler_Abbruch" ;
VAL_ 1178 FS_NFA_einfahren 0 "uneingeschraenkt" 1 "NFA_einfahren" ;
VAL_ 1178 FS_Kollisionsbereich_Windschott 0 "Ausserhalb_Kollisionsbereich" 1 "Innerhalb_Kollisionsbereich" ;
VAL_ 1178 FS_MMB_storage 0 "keine_Zuweisung" 1 "P1_FP1_Pos_Zuweisung" 2 "P2_FP2_Pos_Zuweisung" 3 "P3_FP3_Pos_Zuweisung" 4 "P4_FP4_Pos_Zuweisung" 5 "FS1_bzw_Benutzerkonto_1" 6 "FS2_bzw_Benutzerkonto_2" 7 "FS3_bzw_Benutzerkonto_3" 8 "FS4_bzw_Benutzerkonto_4" 9 "FS5_bzw_Benutzerkonto_5" 10 "FS6_bzw_Benutzerkonto_6" 11 "FS7_bzw_Benutzerkonto_7" ;
VAL_ 1178 FS_MMB_tipp 0 "kein_Tippbetrieb" 1 "Tippbetrieb__automatisches Funkschlüsselmemory aktivieren;" ;
VAL_ 1178 FS_MMB_tast 0 "kein_Tastbetrieb" 1 "Tastbetrieb__Fingerprintautomatismus aktivieren über MMI" ;
VAL_ 1178 FS_MMB_store_LED_on 0 "LED_aus" 1 "LED_ein" ;
VAL_ 1178 FS_MMB_storage_beep 0 "beep aus" 1 "beep ein" ;
VAL_ 1178 FS_MMB_store 0 "nicht speichern__kein keyless verbaut" 1 "abspeichern__keyless verbaut" ;
VAL_ 1178 FS_MMB_glob_stop 0 "kein globaler Abbrucht" 1 "globaler Abbruch" ;
VAL_ 1178 FS_EE_Fond_FS_enable 0 "EE Fond links deaktiv" 1 "EE Fond links aktiv (default) vom MMI" ;
VAL_ 1178 FS_EE_Fond_BFS_enable 0 "EE Fond rechts deaktiv" 1 "EE Fond rechts aktiv (default) vom MMI" ;
VAL_ 1178 FS_EE_BFS_enable 0 "keine_EE_Freigabe" 1 "EE_Freigabe" ;
VAL_ 1178 FS_Kollisionsgefahr_Windschott 0 "Keine_Kombimeldung_anzeigen" 1 "Kombimeldung_anzeigen" ;
VAL_ 954 Mem_FS_Lordose_hoch 0 "Aus" 1 "Ein" ;
VAL_ 954 Mem_FS_Lordose_runter 0 "Aus" 1 "Ein" ;
VAL_ 954 Mem_FS_Lordose_vor 0 "Aus" 1 "Ein" ;
VAL_ 954 Mem_FS_Lordose_zurueck 0 "Aus" 1 "Ein" ;
VAL_ 954 Mem_FS_Massage_Geschw 0 "Aus" 1 "Stufe1" 2 "Stufe2" 3 "Stufe3" 4 "Stufe4" 5 "Stufe5" ;
VAL_ 954 Mem_FS_Massage_Intensitaet 0 "Aus" 1 "Stufe1" 2 "Stufe2" 3 "Stufe3" 4 "Stufe4" 5 "Stufe5" ;
VAL_ 954 Mem_FS_SWangenLehne_beluef 0 "Aus" 1 "Ein" ;
VAL_ 954 Mem_FS_SWangenLehne_entlue 0 "Aus" 1 "Ein" ;
VAL_ 954 Mem_FS_Massage_Programm 0 "Aus" 1 "Programm1" 2 "Programm2" 3 "Programm3" 4 "Programm4" 5 "Programm5" ;
VAL_ 954 Mem_FS_SWangenSitz_beluef 0 "Aus" 1 "Ein" ;
VAL_ 954 Mem_FS_SWangenSitz_entlue 0 "Aus" 1 "Ein" ;
VAL_ 954 FS_BFS_aufraeumen 0 "unbetaetigt" 1 "betaetigt" ;
VAL_ 954 FS_BFSFo_aufraeumen 0 "unbetaetigt" 1 "betaetigt" ;
VAL_ 954 FS_FSFo_aufraeumen 0 "unbetaetigt" 1 "betaetigt" ;
VAL_ 954 FS_Remote_Multif_Taster_hoch 0 "inaktiv" 1 "aktiv" ;
VAL_ 954 FS_Remote_Multif_Taster_tief 0 "inaktiv" 1 "aktiv" ;
VAL_ 954 FS_Remote_Multif_Taster_vor 0 "inaktiv" 1 "aktiv" ;
VAL_ 954 FS_Remote_Multif_Taster_zurueck 0 "inaktiv" 1 "aktiv" ;
VAL_ 954 FS_Remote_Programmwippe_hoch 0 "inaktiv" 1 "aktiv" ;
VAL_ 954 FS_Remote_Programmwippe_tief 0 "inaktiv" 1 "aktiv" ;
VAL_ 954 FS_Remote_SHV_Taste_hoch 0 "inaktiv" 1 "aktiv" ;
VAL_ 954 FS_Remote_SHV_Taste_tief 0 "inaktiv" 1 "aktiv" ;
VAL_ 954 FS_Remote_SLV_Taste_vor 0 "inaktiv" 1 "aktiv" ;
VAL_ 954 FS_Remote_SLV_Taste_zurueck 0 "inaktiv" 1 "aktiv" ;
VAL_ 954 FS_Remote_SNV_Taste_hoch 0 "inaktiv" 1 "aktiv" ;
VAL_ 954 FS_Remote_SNV_Taste_tief 0 "inaktiv" 1 "aktiv" ;
VAL_ 954 FS_Remote_KSV_Taste_hoch 0 "inaktiv" 1 "aktiv" ;
VAL_ 954 FS_Remote_KSV_Taste_tief 0 "inaktiv" 1 "aktiv" ;
VAL_ 954 FS_Remote_LNV_Taste_vor 0 "inaktiv" 1 "aktiv" ;
VAL_ 954 FS_Remote_LNV_Taste_zurueck 0 "inaktiv" 1 "aktiv" ;
VAL_ 954 FS_Remote_Massage_Taste 0 "inaktiv" 1 "aktiv" ;
VAL_ 954 FS_RemoteTarget 0 "Init_oder_Beifahrerseite_Front" 1 "Fahrerseite_Fond" 2 "Beifahrerseite_Fond" ;
VAL_ 954 FS_Remote_KSV_Taste_vor 0 "inaktiv" 1 "aktiv" ;
VAL_ 954 FS_Remote_KSV_Taste_zurueck 0 "inaktiv" 1 "aktiv" ;
VAL_ 954 FS_Remote_STV_Taste_vor 0 "inaktiv" 1 "aktiv" ;
VAL_ 954 FS_Remote_STV_Taste_zurueck 0 "inaktiv" 1 "aktiv" ;
VAL_ 954 FS_Remote_SWV_Taste_eng 0 "inaktiv" 1 "aktiv" ;
VAL_ 954 FS_Remote_SWV_Taste_breit 0 "inaktiv" 1 "aktiv" ;
VAL_ 954 FS_Remote_LWV_Taste_eng 0 "inaktiv" 1 "aktiv" ;
VAL_ 954 FS_Remote_LWV_Taste_breit 0 "inaktiv" 1 "aktiv" ;
VAL_ 954 FS_Remote_LKV_Taste_vor 0 "inaktiv" 1 "aktiv" ;
VAL_ 954 FS_Remote_LKV_Taste_zurueck 0 "inaktiv" 1 "aktiv" ;
VAL_ 954 FS_MMB_Sys_Fahrt_aktiv 0 "inaktiv" 1 "aktiv" ;
VAL_ 956 Mem_FSFo_Lordose_hoch 0 "Aus" 1 "Ein" ;
VAL_ 956 Mem_FSFo_Lordose_runter 0 "Aus" 1 "Ein" ;
VAL_ 956 Mem_FSFo_Lordose_vor 0 "Aus" 1 "Ein" ;
VAL_ 956 Mem_FSFo_Lordose_zurueck 0 "Aus" 1 "Ein" ;
VAL_ 956 Mem_FSFo_Massage_Geschw 0 "Aus" 1 "Stufe1" 2 "Stufe2" 3 "Stufe3" 4 "Stufe4" 5 "Stufe5" ;
VAL_ 956 Mem_FSFo_Massage_Intens 0 "Aus" 1 "Stufe1" 2 "Stufe2" 3 "Stufe3" 4 "Stufe4" 5 "Stufe5" ;
VAL_ 956 Mem_FSFo_MMB_storage 0 "keine_Zuweisung" 1 "P1/FP1_MemoryPos" 2 "P2/FP2_MemoryPos" 3 "P3/FP3_MemoryPos" ;
VAL_ 956 Mem_FSFo_Massage_Prg 0 "Aus" 1 "Programm1" 2 "Programm2" 3 "Programm3" 4 "Programm4" 5 "Programm5" ;
VAL_ 956 Mem_FSFo_MMB_tast 0 "kein_Tastbetrieb" 1 "Tastbetrieb" ;
VAL_ 956 Mem_FSFo_MMB_tipp 0 "kein_Tippbetrieb" 1 "Tippbetrieb" ;
VAL_ 956 Mem_FSFo_MMB_glob_Stop 0 "kein_Abbruch" 1 "Abbruch" ;
VAL_ 956 Mem_FSFo_Sitztiefe_vor 0 "Aus" 1 "Ein" ;
VAL_ 956 Mem_FSFo_Sitztiefe_zur 0 "Aus" 1 "Ein" ;
VAL_ 956 Mem_FSFo_MMB_store 0 "nicht_speichern" 1 "speichern" ;
VAL_ 956 Mem_FSFo_MMB_storage_beep 0 "Beep_aus" 1 "Beep_ein" ;
VAL_ 956 Mem_FSFo_MMB_store_LED_on 0 "LED_aus" 1 "LED_ein" ;
VAL_ 956 Mem_FSFo_MMB_lokal_Stop 0 "kein_Abbruch" 1 "lokaler_Abbruch" ;
VAL_ 956 Mem_FSFo_Sitzfahrt_aktiv 0 "nicht_aktiv" 1 "Sitzfahrt_Aktiv" ;
VAL_ 956 Mem_FSFo_Business_anfahren 0 "inaktiv" 1 "Business_anfahren" ;
VAL_ 956 Mem_FSFo_Relax_anfahren 0 "inaktiv" 1 "Relax_aktivieren" ;
VAL_ 1180 MTBT_Pos1 0 "Taste_nicht_gedrueckt" 1 "Postionstaste_1_BT_gedrueckt" ;
VAL_ 1180 MTBT_Pos2 0 "Taste_nicht_gedrueckt" 1 "Postionstaste_2_BT_gedrueckt" ;
VAL_ 1180 MTBT_Pos3 0 "Taste_nicht_gedrueckt" 1 "Postionstaste_3_BT_gedrueckt" ;
VAL_ 1180 MTBT_Pos4 0 "Taste_nicht_gedrueckt" 1 "Postionstaste_4_BT_gedrueckt" ;
VAL_ 1180 MTBT_On_Off 0 "Taste_nicht_gedrueckt" 1 "On-Off Taste BT gedrückt" ;
VAL_ 1180 MTBT_M_Taste 0 "Taste_nicht_gedrueckt" 1 "MTaste_BT_gedrueckt" ;
VAL_ 1170 MTFT_Pos1_EE 0 "Taste_nicht_gedrueckt" 1 "Postionstaste 1 FT gedrückt" ;
VAL_ 1170 MTFT_Pos2 0 "Taste_nicht_gedrueckt" 1 "Postionstaste 2 FT gedrückt" ;
VAL_ 1170 MTFT_Pos3 0 "Taste_nicht_gedrueckt" 1 "Postionstaste 3 FT gedrückt" ;
VAL_ 1170 MTFT_Pos4 0 "Taste_nicht_gedrueckt" 1 "Postionstaste 4 FT gedrückt" ;
VAL_ 1170 MTFT_On_Off 0 "Taste_nicht_gedrueckt" 1 "On-Off Taste FT gedrückt" ;
VAL_ 1170 MTFT_Verst_akt 0 "Verstellung nicht aktiv" 1 "Verstellung aktiv" ;
VAL_ 1170 MTFT_M_Taste 0 "Taste_nicht_gedrueckt" 1 "MTaste_FT_gedrueckt" ;
VAL_ 1173 BFS_Sitzhoehe_hoch 0 "aus" 1 "hoch" ;
VAL_ 1173 BFS_Sitzhoehe_runter 0 "aus" 1 "runter" ;
VAL_ 1173 MTHBF_ein 0 "aus" 1 "ein" ;
VAL_ 1173 BFS_Laengsverst_vor 0 "Taste_nicht_gedrueckt" 1 "Längsverstellung vor" ;
VAL_ 1173 BFS_Laengsverst_zurueck 0 "Taste_nicht_gedrueckt" 1 "Längsverstellung zurück (Wird bei Rechtslenker vom TSG HL gesendet)" ;
VAL_ 1173 BFS_Lehnenneigung_vor 0 "Taste_nicht_gedrueckt" 1 "Lehnenneigung vor (Wird bei Rechtslenker vom TSG HL gesendet)" ;
VAL_ 1173 BFS_Lehnenneigung_zurueck 0 "Taste_nicht_gedrueckt" 1 "Lehnenneigung zurück" ;
VAL_ 1173 BFS_Lehnenkopf_vor 0 "Taste_nicht_gedrueckt" 1 "Lehnenkopf vor " ;
VAL_ 1173 BFS_Lehnenkopf_zurueck 0 "Taste_nicht_gedrueckt" 1 "Lehnenkopf zurück" ;
VAL_ 1173 BFS_Kopfstuetzen_hoch 0 "Taste_nicht_gedrueckt" 1 "Kopfstützen hoch" ;
VAL_ 1173 BFS_Kopfstuetzen_runter 0 "Taste_nicht_gedrueckt" 1 "Kopfstützen runter" ;
VAL_ 817 MFL_Lokalaktiv 0 "war_nicht_lokal_aktiv" 1 "war_lokal_aktiv" ;
VAL_ 817 MFL_M_Taste 0 "nicht_betaetigt" 1 "betaetigt" ;
VAL_ 817 MFL_Paddle_Verbau 0 "verbaut" 1 "nicht_verbaut" ;
VAL_ 817 MFL_Tastencode_1 0 "Key_Released__No_Key" 1 "Context_Menu" 2 "Menu_Up__Next_Screen" 3 "Menu_Down__Previous_Screen" 4 "Up" 5 "Down" 6 "Up__Down_ThumbWheel" 7 "OK__ThumbWheel_Button" 8 "Cancel__Escape" 9 "Main_Menu" 10 "Side_Menu_left" 11 "Side_Menu_right" 12 "FAS_Menu" 13 "Left__Right_ThumbWheel" 16 "Volume_Up" 17 "Volume_Down" 18 "Volume_Up__Down_ThumbWheel" 19 "Volume_ThumbWheel_Button" 20 "Audio_Source" 21 "Arrow_A_Up__Right" 22 "Arrow_A_Down__Left" 23 "Arrow_B_Up__Right" 24 "Arrow_B_Down__Left" 25 "PTT__PushToTalk" 26 "PTT_Cancel" 27 "Route_Info" 28 "Hook" 29 "Hang_Up" 30 "Off_Hook" 31 "Light_On__Off" 32 "Mute" 33 "Joker1" 34 "Joker2" 35 "View" 36 "Arrow_A_Up__Down_ThumbWheel" 37 "Lenkradheizung" 38 "Rekuperation" 39 "Tube_Toggle" 100 "MAP" 101 "MAP_Boost" 102 "Turn_signal_left" 103 "Turn_signal_right" 104 "Turn_signal_off" 105 "Flashlight" 106 "Highbeam" 107 "Washer_button" 108 "Wiper_button_left" 109 "Wiper_button_right" 110 "Wiper_button_cancel" 111 "Exhaust_Sound" 112 "Drive_Select_button" 113 "Sport_button" 114 "ESP_Drift_Selection_ThumbWheel" 115 "PTT_special_vehicle" 116 "TravelAssist" 240 "Startup_Reset" 241 "Initialization" ;
VAL_ 817 MFL_Tastencode_2 0 "Key_Released__No_Key" 1 "Context_Menu" 2 "Menu_Up__Next_Screen" 3 "Menu_Down__Previous_Screen" 4 "Up" 5 "Down" 6 "Up__Down_ThumbWheel" 7 "OK__ThumbWheel_Button" 8 "Cancel__Escape" 9 "Main_Menu" 10 "Side_Menu_left" 11 "Side_Menu_right" 12 "FAS_Menu" 13 "Left__Right_ThumbWheel" 16 "Volume_Up" 17 "Volume_Down" 18 "Volume_Up__Down_ThumbWheel" 19 "Volume_ThumbWheel_Button" 20 "Audio_Source" 21 "Arrow_A_Up__Right" 22 "Arrow_A_Down__Left" 23 "Arrow_B_Up__Right" 24 "Arrow_B_Down__Left" 25 "PTT__PushToTalk" 26 "PTT_Cancel" 27 "Route_Info" 28 "Hook" 29 "Hang_Up" 30 "Off_Hook" 31 "Light_On__Off" 32 "Mute" 33 "Joker1" 34 "Joker2" 35 "View" 36 "Arrow_A_Up_Right_Down_Left_ThumbWheel" 37 "Lenkradheizung" 38 "Rekuperation" 39 "Tube_Toggle" 100 "MAP" 101 "MAP_Boost" 102 "Turn_signal_left" 103 "Turn_signal_right" 104 "Turn_signal_off" 105 "Flashlight" 106 "Highbeam" 107 "Washer_button" 108 "Wiper_button_left" 109 "Wiper_button_right" 110 "Wiper_button_cancel" 111 "Exhaust_Sound" 112 "Drive_Select_button" 113 "Sport_button" 114 "ESP_Drift_Selection_ThumbWheel" 115 "PTT_special_vehicle" 116 "TravelAssist" 240 "Startup_Reset" 241 "Initialization" ;
VAL_ 817 MFL_Eventcode_1 0 "W_no_event____T_no_event" 1 "W_1_Tick_up__T_pressed_normal" 2 "W_2_Ticks_up__T_touched" 3 "W_3_Ticks_up__T_double_click_nor" 4 "W_4_Ticks_up__T_long_press_nor_1" 5 "W_5_Ticks_up__T_long_press_nor_2" 6 "W_6_Ticks_up__T_long_press_nor_3" 7 "W_7_Ticks_up" 9 "W_7_Ticks_dn__T_pressed_strong" 10 "W_6_Ticks_dn" 11 "W_5_Ticks_dn__T_double_click_str" 12 "W_4_Ticks_dn__T_long_press_str_1" 13 "W_3_Ticks_dn__T_long_press_str_2" 14 "W_2_Ticks_dn__T_long_press_str_3" 15 "W_1_Tick_dn" ;
VAL_ 817 MFL_Eventcode_2 0 "W_no_event____T_no_event" 1 "W_1_Tick_up__T_pressed_normal" 2 "W_2_Ticks_up__T_touched" 3 "W_3_Ticks_up__T_double_click_nor" 4 "W_4_Ticks_up__T_long_press_nor_1" 5 "W_5_Ticks_up__T_long_press_nor_2" 6 "W_6_Ticks_up__T_long_press_nor_3" 7 "W_7_Ticks_up" 9 "W_7_Ticks_dn__T_pressed_strong" 10 "W_6_Ticks_dn" 11 "W_5_Ticks_dn__T_double_click_str" 12 "W_4_Ticks_dn__T_long_press_str_1" 13 "W_3_Ticks_dn__T_long_press_str_2" 14 "W_2_Ticks_dn__T_long_press_str_3" 15 "W_1_Tick_dn" ;
VAL_ 817 MFL_Marke 0 "VW" 1 "Audi" 2 "Seat" 3 "Skoda" 4 "VW_Nutzf" 5 "Bugatti" 6 "Lamborghini" 7 "Bentley" 8 "Rolls Royce" 9 "Quattro" 10 "kein_Hersteller_1" 11 "kein_Hersteller_2" 12 "kein_Hersteller_3" 13 "kein_Hersteller_4" 14 "Ford" 15 "Porsche" ;
VAL_ 817 MFL_Tip_Down 0 "nicht_betaetigt" 1 "betaetigt" ;
VAL_ 817 MFL_Tip_Up 0 "nicht_betaetigt" 1 "betaetigt" ;
VAL_ 817 MFL_SatModul_links_Err 0 "kein_Fehler" 1 "Fehler" ;
VAL_ 817 MFL_SatModul_rechts_Err 0 "kein_Fehler" 1 "Fehler" ;
VAL_ 817 MFL_LR_HZG_Status 0 "inaktiv" 1 "aktiv" ;
VAL_ 817 MFL_LR_HZG_Err 0 "normal" 1 "Fehler" ;
VAL_ 817 MFL_Signalhorn 0 "nicht_betaetigt" 1 "betaetigt" ;
VAL_ 817 MFL_Signalhorn_Err 0 "normal" 1 "Fehler" ;
VAL_ 817 MFL_Tip_links_Err 0 "normal" 1 "Fehler" ;
VAL_ 817 MFL_Tip_rechts_Err 0 "normal" 1 "Fehler" ;
VAL_ 817 MFL_Taste_links_Err 0 "normal" 1 "Fehler" ;
VAL_ 817 MFL_Taste_rechts_Err 0 "normal" 1 "Fehler" ;
VAL_ 817 MFL_ECU_Err 0 "normal" 1 "Fehler" ;
VAL_ 817 MFL_Response_Err 0 "normal" 1 "Fehler" ;
VAL_ 1471 MFL_Tastencode_1 0 "Key_Released__No_Key" 1 "Context_Menu" 2 "Menu_Up__Next_Screen" 3 "Menu_Down__Previous_Screen" 4 "Up" 5 "Down" 6 "Up__Down_ThumbWheel" 7 "OK__ThumbWheel_Button" 8 "Cancel__Escape" 9 "Main_Menu" 10 "Side_Menu_left" 11 "Side_Menu_right" 12 "FAS_Menu" 13 "Left__Right_ThumbWheel" 16 "Volume_Up" 17 "Volume_Down" 18 "Volume_Up__Down_ThumbWheel" 19 "Volume_ThumbWheel_Button" 20 "Audio_Source" 21 "Arrow_A_Up__Right" 22 "Arrow_A_Down__Left" 23 "Arrow_B_Up__Right" 24 "Arrow_B_Down__Left" 25 "PTT__PushToTalk" 26 "PTT_Cancel" 27 "Route_Info" 28 "Hook" 29 "Hang_Up" 30 "Off_Hook" 31 "Light_On__Off" 32 "Mute" 33 "Joker1" 34 "Joker2" 35 "View" 36 "Arrow_A_Up__Down_ThumbWheel" 37 "Lenkradheizung" 38 "Rekuperation" 39 "Tube_Toggle" 100 "MAP" 101 "MAP_Boost" 102 "Turn_signal_left" 103 "Turn_signal_right" 104 "Turn_signal_off" 105 "Flashlight" 106 "Highbeam" 107 "Washer_button" 108 "Wiper_button_left" 109 "Wiper_button_right" 110 "Wiper_button_cancel" 111 "Exhaust_Sound" 112 "Drive_Select_button" 113 "Sport_button" 114 "ESP_Drift_Selection_ThumbWheel" 115 "PTT_special_vehicle" 116 "TravelAssist" 240 "Startup_Reset" 241 "Initialization" ;
VAL_ 1471 MFL_Tastencode_2 0 "Key_Released__No_Key" 1 "Context_Menu" 2 "Menu_Up__Next_Screen" 3 "Menu_Down__Previous_Screen" 4 "Up" 5 "Down" 6 "Up__Down_ThumbWheel" 7 "OK__ThumbWheel_Button" 8 "Cancel__Escape" 9 "Main_Menu" 10 "Side_Menu_left" 11 "Side_Menu_right" 12 "FAS_Menu" 13 "Left__Right_ThumbWheel" 16 "Volume_Up" 17 "Volume_Down" 18 "Volume_Up__Down_ThumbWheel" 19 "Volume_ThumbWheel_Button" 20 "Audio_Source" 21 "Arrow_A_Up__Right" 22 "Arrow_A_Down__Left" 23 "Arrow_B_Up__Right" 24 "Arrow_B_Down__Left" 25 "PTT__PushToTalk" 26 "PTT_Cancel" 27 "Route_Info" 28 "Hook" 29 "Hang_Up" 30 "Off_Hook" 31 "Light_On__Off" 32 "Mute" 33 "Joker1" 34 "Joker2" 35 "View" 36 "Arrow_A_Up_Right_Down_Left_ThumbWheel" 37 "Lenkradheizung" 38 "Rekuperation" 39 "Tube_Toggle" 100 "MAP" 101 "MAP_Boost" 102 "Turn_signal_left" 103 "Turn_signal_right" 104 "Turn_signal_off" 105 "Flashlight" 106 "Highbeam" 107 "Washer_button" 108 "Wiper_button_left" 109 "Wiper_button_right" 110 "Wiper_button_cancel" 111 "Exhaust_Sound" 112 "Drive_Select_button" 113 "Sport_button" 114 "ESP_Drift_Selection_ThumbWheel" 115 "PTT_special_vehicle" 116 "TravelAssist" 240 "Startup_Reset" 241 "Initialization" ;
VAL_ 1471 MFL_Eventcode_1 0 "W_no_event____T_no_event" 1 "W_1_Tick_up__T_pressed_normal" 2 "W_2_Ticks_up__T_touched" 3 "W_3_Ticks_up__T_double_click_nor" 4 "W_4_Ticks_up__T_long_press_nor_1" 5 "W_5_Ticks_up__T_long_press_nor_2" 6 "W_6_Ticks_up__T_long_press_nor_3" 7 "W_7_Ticks_up" 9 "W_7_Ticks_dn__T_pressed_strong" 10 "W_6_Ticks_dn" 11 "W_5_Ticks_dn__T_double_click_str" 12 "W_4_Ticks_dn__T_long_press_str_1" 13 "W_3_Ticks_dn__T_long_press_str_2" 14 "W_2_Ticks_dn__T_long_press_str_3" 15 "W_1_Tick_dn" ;
VAL_ 1471 MFL_Eventcode_2 0 "W_no_event____T_no_event" 1 "W_1_Tick_up__T_pressed_normal" 2 "W_2_Ticks_up__T_touched" 3 "W_3_Ticks_up__T_double_click_nor" 4 "W_4_Ticks_up__T_long_press_nor_1" 5 "W_5_Ticks_up__T_long_press_nor_2" 6 "W_6_Ticks_up__T_long_press_nor_3" 7 "W_7_Ticks_up" 9 "W_7_Ticks_dn__T_pressed_strong" 10 "W_6_Ticks_dn" 11 "W_5_Ticks_dn__T_double_click_str" 12 "W_4_Ticks_dn__T_long_press_str_1" 13 "W_3_Ticks_dn__T_long_press_str_2" 14 "W_2_Ticks_dn__T_long_press_str_3" 15 "W_1_Tick_dn" ;
VAL_ 1471 MFL_Marke 0 "VW" 1 "Audi" 2 "Seat" 3 "Skoda" 4 "VW_Nutzf" 5 "Bugatti" 6 "Lamborghini" 7 "Bentley" 8 "Rolls Royce" 9 "Quattro" 10 "kein_Hersteller_1" 11 "kein_Hersteller_2" 12 "kein_Hersteller_3" 13 "kein_Hersteller_4" 14 "Ford" 15 "Porsche" ;
VAL_ 2463978670 SDF2_MIB_Segment_ID 0 "KeineSegmentinformation" 1 "Fehlerwert" ;
VAL_ 2463978670 SDF2_MIB_Fehler_Laengsrichtung 0 "Init" 1 "kleiner_2m" 2 "kleiner_5m" 3 "kleiner_10m" 4 "kleiner_20m" 5 "kleiner_50m" 6 "groesser_50m" 7 "offroad" ;
VAL_ 2463978670 SDF2_MIB_Standort_Eindeutig 0 "mehrdeutiger_Standort" 1 "eindeutiger_Standort" ;
VAL_ 263 MO_rel_Ladedruck 255 "Fehler" ;
VAL_ 263 MO_Istgang 0 "kein_Gang_eingelegt" 1 "Gang_1" 2 "Gang_2" 3 "Gang_3" 4 "Gang_4" 5 "Gang_5" 6 "Gang_6" 7 "Gang_7" 8 "Gang_8" 9 "Gang_9" ;
VAL_ 263 MO_Sollgang 0 "keine_Empfehlung" 1 "Gang_1" 2 "Gang_2" 3 "Gang_3" 4 "Gang_4" 5 "Gang_5" 6 "Gang_6" 7 "Gang_7" 8 "Gang_8" 9 "Gang_9" 15 "Neutralgang" ;
VAL_ 263 MO_Oeldruck 254 "Init" 255 "Fehler" ;
VAL_ 263 MO_Anzeigedrehz 4095 "reserviert" ;
VAL_ 263 MO_Effizienzmodus 0 "nicht_im_Effizienz_Modus" 1 "Effizienz_Modus" ;
VAL_ 263 MO_Fehler_Oeldrucksensor 0 "kein_Fehler" 1 "Fehler" ;
VAL_ 263 MO_Schaltempf_verfbar 0 "nicht_verfuegbar" 1 "verfuegbar" ;
VAL_ 263 MO_Ladedruck 511 "Fehler" ;
VAL_ 263 MO_KVS_Ueberlauf 0 "kein Ueberlauf" 1 "Kraftstoffverbrauchsignale mindestens 1x übergelaufen" ;
VAL_ 1600 MO_QBit_Ansaugluft_Temp 0 "gueltiger_Wert" 1 "Ersatz_Init_oder_Fehlerwert" ;
VAL_ 1600 MO_QBit_Oel_Temp 0 "gueltiger_Wert" 1 "Ersatz_Init_oder_Fehlerwert" ;
VAL_ 1600 MO_QBit_Kuehlmittel_Temp 0 "gueltiger_Wert" 1 "Ersatz_Init_oder_Fehlerwert" ;
VAL_ 1600 MO_KL15_Abschaltempfehlung 0 "Keine Empfehlung" 1 "Abschaltempfehlung" ;
VAL_ 1600 MO_HYB_Fehler_HV_Netz 0 "i_O" 1 "kein_generatorischer_Betrieb_moeglich" ;
VAL_ 1600 MO_aktives_Getriebeheizen 0 "kein_Ventil_ansteuern" 1 "Ventil_muss_angesteuert_werden" ;
VAL_ 1600 MO_Absperrventil_oeffnen 0 "nicht_verfuegbar" 1 "Ansteuerung_Ventil_zulaessig" 2 "Ventil_oeffnen_oder_geoeffnet" 3 "Ventil_schliessen_oder_geschlossen" ;
VAL_ 1600 MO_Ansaugluft_Temp 254 "Init" 255 "Fehler" ;
VAL_ 1600 MO_Oel_Temp 253 "nicht_verbaut" 254 "Init" 255 "Fehler" ;
VAL_ 1600 MO_Kuehlmittel_Temp 254 "Init" 255 "Fehler" ;
VAL_ 1600 MO_Hoeheninfo 255 "Fehler" ;
VAL_ 1600 MO_Kennfeldk 0 "keine Kennfeldkühlung vorhanden" 1 "Kennfeldkühlung vorhanden" ;
VAL_ 1600 MO_Versionsinfo_02 0 "zum_Projektbeginn_aufgeraeumter_CAN" 1 "Motor_03_mit_10ms" 16 "MQB_mit_neuer_Momentenschnittstelle" ;
VAL_ 1600 MO_QBit_Hoeheninfo 0 "gueltiger_Wert" 1 "Ersatz_Init_oder_Fehlerwert" ;
VAL_ 1600 MO_Getriebe_kuehlen 0 "nicht_kuehlen" 1 "kuehlen" ;
VAL_ 1600 MO_Heizungspumpenansteuerung 13 "Fehler" 14 "Init" 15 "nicht_verbaut" ;
VAL_ 1600 MO_SpannungsAnf 0 "keine_Anforderung" 1 "Anforderung" ;
VAL_ 1607 MO_ITM_Kuehlmittel_Temp 0 "nicht_verbaut" 1 "Init" 2 "Fehler" ;
VAL_ 1607 MO_E85_Sensor 13 "nicht_verbaut" 14 "Init" 15 "Fehler" ;
VAL_ 1607 SCR_Anz_Motorstarts 0 "Anzahl_moeglicher_Restarts" 1 "Anzahl_moeglicher_Restarts" 2 "Anzahl_moeglicher_Restarts" 3 "Anzahl_moeglicher_Restarts" 4 "Anzahl_moeglicher_Restarts" 5 "Anzahl_moeglicher_Restarts" 6 "Anzahl_moeglicher_Restarts" 7 "Anzahl_moeglicher_Restarts" 8 "Anzahl_moeglicher_Restarts" 9 "Anzahl_moeglicher_Restarts" 10 "Anzahl_moeglicher_Restarts" 11 "Anzahl_moeglicher_Restarts" 12 "Anzahl_moeglicher_Restarts" 13 "Anzahl_moeglicher_Restarts" 14 "Fahrbarkeitseinschraenkung" 15 "keine_Einschraenkung" ;
VAL_ 1607 SCR_Reichweite 32767 "keine_Anzeige" ;
VAL_ 1607 MO_Ethanol_Spuelhinweis 0 "Kein_Hinweis" 1 "Spuelhinweis_aktiv" ;
VAL_ 1607 SCR_Warnstufe_1 0 "nicht_aktiv" 1 "Warnstufe_1_aktiv" ;
VAL_ 1607 SCR_Warnstufe_2 0 "nicht_aktiv" 1 "Warnstufe_2_aktiv" ;
VAL_ 1607 SCR_Text 0 "kein_Text" 1 "Warntext_1" 2 "Warntext_2" 3 "Hinweis_Fuellstand" 4 "Reserve" 5 "SysFehler_1" 6 "SysFehler_2" 7 "Hinweis_Systemfehler" ;
VAL_ 1607 SCR_Akustik 0 "keine_Akustik" 1 "Akustik_1" 2 "Akustik_2" 3 "Akustik_bei_Hinweis" ;
VAL_ 1607 SCR_verbaut 0 "kein_SCR" 1 "SCR_verbaut" ;
VAL_ 1607 MO_Kraftstofffilter_Wasser 0 "keine_Anzeige" 1 "Abscheidevolumen_erschoepft" ;
VAL_ 1607 SCR_Systemfehler 0 "Warnung_nicht_aktiv" 1 "Warnung_aktiv" ;
VAL_ 1607 SCR_Inducement_Strategie 0 "Restart_Strategie" 1 "Reduced_Drivability_Strategie" ;
VAL_ 1607 MO_CO2_Faktor 0 "nicht_verbaut" 4095 "Fehler" ;
VAL_ 1607 MO_MKB_MUX 0 "MKB_01" 1 "MKB_02" 2 "MKB_03" 3 "MKB_04" ;
VAL_ 1607 MO_MKB_01 0 "Minus" 1 "A" 2 "B" 3 "C" 4 "D" 5 "E" 6 "F" 7 "G" 8 "H" 9 "I" 10 "J" 11 "K" 12 "L" 13 "M" 14 "N" 15 "O" 16 "P" 17 "Q" 18 "R" 19 "S" 20 "T" 21 "U" 22 "V" 23 "W" 24 "X" 25 "Y" 26 "Z" 27 "Leerzeichen" 28 "Leerzeichen" 29 "Leerzeichen" 30 "Leerzeichen" 31 "Unterstrich" ;
VAL_ 1607 MO_MKB_02 0 "Minus" 1 "A" 2 "B" 3 "C" 4 "D" 5 "E" 6 "F" 7 "G" 8 "H" 9 "I" 10 "J" 11 "K" 12 "L" 13 "M" 14 "N" 15 "O" 16 "P" 17 "Q" 18 "R" 19 "S" 20 "T" 21 "U" 22 "V" 23 "W" 24 "X" 25 "Y" 26 "Z" 27 "Leerzeichen" 28 "Leerzeichen" 29 "Leerzeichen" 30 "Leerzeichen" 31 "Unterstrich" ;
VAL_ 1607 MO_MKB_03 0 "Minus" 1 "A" 2 "B" 3 "C" 4 "D" 5 "E" 6 "F" 7 "G" 8 "H" 9 "I" 10 "J" 11 "K" 12 "L" 13 "M" 14 "N" 15 "O" 16 "P" 17 "Q" 18 "R" 19 "S" 20 "T" 21 "U" 22 "V" 23 "W" 24 "X" 25 "Y" 26 "Z" 27 "Leerzeichen" 28 "Leerzeichen" 29 "Leerzeichen" 30 "Leerzeichen" 31 "Unterstrich" ;
VAL_ 1607 MO_MKB_04 0 "Minus" 1 "A" 2 "B" 3 "C" 4 "D" 5 "E" 6 "F" 7 "G" 8 "H" 9 "I" 10 "J" 11 "K" 12 "L" 13 "M" 14 "N" 15 "O" 16 "P" 17 "Q" 18 "R" 19 "S" 20 "T" 21 "U" 22 "V" 23 "W" 24 "X" 25 "Y" 26 "Z" 27 "Leerzeichen" 28 "Leerzeichen" 29 "Leerzeichen" 30 "Leerzeichen" 31 "Unterstrich" ;
VAL_ 167 MO_Mom_Soll_Roh 1022 "Init" ;
VAL_ 167 MO_Mom_Ist_Summe 1022 "Init" ;
VAL_ 167 MO_Mom_Traegheit_Summe 1022 "Init" ;
VAL_ 167 MO_Mom_Soll_gefiltert 1022 "Init" ;
VAL_ 167 MO_Mom_Schub 510 "Init" ;
VAL_ 167 MO_Status_Normalbetrieb_01 0 "kein_Normalbetrieb" 1 "Normalbetrieb_erreicht" ;
VAL_ 167 MO_erste_Ungenauschwelle 0 "genau" 1 "Momente ungenauer >8%" ;
VAL_ 167 MO_QBit_Motormomente 0 "gueltiger_Wert" 1 "Ersatz_Init_oder_Fehlerwert" ;
VAL_ 168 MO_Mom_neg_verfuegbar 510 "Init" 511 "Fehler" ;
VAL_ 168 MO_Mom_Begr_stat 510 "Init" ;
VAL_ 168 MO_Mom_Begr_dyn 1022 "Init" ;
VAL_ 168 MO_QBit_Drehzahl_01 0 "gueltiger_Wert" 1 "Ersatz_Init_oder_Fehlerwert" ;
VAL_ 958 MO_StartStopp_Status 0 "System_in_diesem_KL15_Zyklus_nicht_verfuegbar" 1 "System_aktiv_keine_Freigabe_durch_StartStop_Koordinator" 2 "System_aktiv_alle_Freigaben_liegen_vor" 3 "System_aktiv_mindestens_eine_Freigabe_fehlt" ;
VAL_ 958 MO_StartStopp_Wiederstart 0 "Wiederstart_inaktiv" 1 "Wiederstart_aktiv" ;
VAL_ 958 MO_StartStopp_Motorstopp 0 "Motor_Stop_inaktiv" 1 "Motor_Stop_aktiv" ;
VAL_ 958 MO_Freig_Reku 0 "Rekuperations-Modus aus" 1 "Empfehlung Spannungsanhebung" 2 "Empfehlung Spannungsabsenkung" 3 "Rekuperationsmodus aktiv, Spannungsvariation nicht notwendig" ;
VAL_ 958 MO_Kl_75 0 "Aus" 1 "Ein" ;
VAL_ 958 MO_Kl_50 0 "aus" 1 "KL50_ein_Startausfuehrung_Fahrer" ;
VAL_ 958 MO_Gangposition 0 "Gang_N" 1 "Gang_1" 2 "Gang_2" 3 "Gang_3" 4 "Gang_4" 5 "Gang_5" 6 "Gang_6" 7 "Gang_7" 8 "Gang_8" 9 "Automat_P" 10 "Automat_Vorwaerts_S" 11 "Automat_Vorwaerts_D/E" 12 "Zwischenstellung" 13 "Gang_R" 14 "Istgang_nicht_definiert" 15 "Fehler" ;
VAL_ 958 MO_StartStopp_Fahrerwunsch 0 "Init" 1 "Stoppverbot_durch_Fahrer" 2 "Stoppfreigabe_durch_Fahrer" 3 "Stoppanforderung_durch_Fahrer" ;
VAL_ 958 MO_HYB_Fahrbereitschaft 0 "keine_Fahrbereitschaft" 1 "Fahrbereitschaft" ;
VAL_ 958 MO_Ext_E_Fahrt_aktiv 0 "Rueckmeldung_E_Taster_aus" 1 "Rueckmeldung_E_Taster_ein" ;
VAL_ 958 MO_Fahrer_bremst 0 "kein_Bremsen" 1 "Bremse_betaetigt" ;
VAL_ 958 MO_QBit_Fahrer_bremst 0 "gueltiger_Wert" 1 "Ersatz_Init_oder_Fehlerwert" ;
VAL_ 958 MO_BLS 0 "kein_Bremsen" 1 "Bremse_betaetigt" ;
VAL_ 958 MO_Konsistenz_Bremsped 0 "Bremspedalinformation_plausibel" 1 "Bremspedalinformation_unplausibel" ;
VAL_ 958 MO_KomFehler_ESP 0 "kein_Fehler" 1 "Fehler" ;
VAL_ 958 MO_Klima_Eingr 0 "kein Eingriff" 1 "Klimakompressor ausschalten" 2 "Klimakompressor Leistungsreduzierung" 3 "Klimakompressor aufgrund der Heissleuchtenvorwarnung ausschalten" ;
VAL_ 958 MO_Aussp_Anlass 0 "Anlasser_darf_angesteuert_werden" 1 "Anlasser_ausspuren__Ansteuerung_nicht_moeglich" ;
VAL_ 958 MO_Freig_Anlass 0 "Start_nicht_zulaessig" 1 "Startfreigabe" ;
VAL_ 958 MO_Kuppl_schalter 0 "Schalter_sagt_ausgekuppelt" 1 "Schalter_sagt_eingekuppelt" ;
VAL_ 958 MO_Interlock 0 "Interlockschalter_nicht_betaetigt" 1 "Interlockschalter_betaetigt" ;
VAL_ 958 MO_Motor_laeuft 0 "Motor_laeuft_nicht" 1 "Motor_laeuft_autark_und_stabil_und_darf_mechanisch_belastet_werden" ;
VAL_ 958 MO_Kickdown 0 "kein_Kickdown" 1 "Kickdown" ;
VAL_ 958 MO_QBit_KL_75 0 "gueltiger_Wert" 1 "Ersatz_Init_oder_Fehlerwert" ;
VAL_ 958 MO_EKlKomLeiRed 0 "keine_Leistungsbegr" 1 "Leistungsbegr_75" 2 "Leistungsbegr_50" 3 "Leistungsbegr_25" ;
VAL_ 958 MO_Handshake_STH 0 "keine EKP-Ansteuerung durch STH-Anforderung" 1 "EKP-Ansteuerung durch STH-Anforderung" ;
VAL_ 958 MO_BKV_Unterdruckwarnung 0 "Unterdruckhaushalt_iO" 1 "Unterdruckhaushalt_niO" ;
VAL_ 958 MO_Freigabe_Segeln 0 "Segelbetrieb_nicht_freigegeben" 1 "Segelbetrieb_freigegeben" ;
VAL_ 958 MO_PTC_Status 0 "nicht_unterstuetzt" 1 "Stufe_0" 2 "Stufe_1" 3 "Stufe_2" 4 "Stufe_3" 7 "PTC_am_BCM" ;
VAL_ 958 MO_QBit_Gangposition 0 "gueltiger_Wert" 1 "Ersatz_Init_oder_Fehlerwert" ;
VAL_ 958 MO_Signalquelle_Gangposition 0 "Sensorsignal" 1 "Modellsignal" ;
VAL_ 958 MO_Remotestart_Betrieb 0 "MSG_nicht_bereit_fuer_RS_Betrieb" 1 "MSG_bereit_fuer_oder_im_RS_Betrieb" ;
VAL_ 958 MO_Remotestart_moeglich 0 "Remotestart_nicht_moeglich" 1 "Remotestart_moeglich" ;
VAL_ 958 MO_FMAus_aktiv 0 "inaktiv" 1 "Segeln_mit_Motor_aus_aktiv" ;
VAL_ 958 MO_FMAus_Startvariante 0 "kein_Motorstart" 1 "Motorstart_elektrischer_Starter" 2 "GetriebeAnschleppstart" 3 "GetriebeNotAnschleppstart" ;
VAL_ 958 MO_BMS_NV_Anf_stuetzen 0 "nicht_notwendig" 1 "notwendig" ;
VAL_ 958 MO_Zylinderabschaltung 0 "Vollmotorbetrieb_VMB" 1 "Uebergang_HMB_in_VMB" 2 "Uebergang_VMB_in_HMB" 3 "Halbmotorbetrieb_HMB" ;
VAL_ 958 MO_HYB_VM_aktiv 0 "VM_nicht_aktiv" 1 "VM_aktiv" ;
VAL_ 958 MO_StartVorauss_erfuellt 0 "Signal_nicht_bedient" 1 "StartVorauss_nicht_ueberpruefbar" 2 "StartVorauss_nicht_erfuellt" 3 "StartVorauss_erfuellt" ;
VAL_ 1631 TSK_QBit_Steigung 0 "gueltiger_Wert" 1 "Ersatz_Init_oder_Fehlerwert" ;
VAL_ 1631 TSK_QBit_Fahrzeugmasse 0 "gueltiger_Wert" 1 "Ersatz_Init_oder_Fehlerwert" ;
VAL_ 1631 MO_SpannungsAnf_02 0 "keine_Anforderung" 1 "Anforderung_Stufe_1" 2 "Anforderung_Stufe_2" 3 "Anforderung_Stufe_3" ;
VAL_ 1631 MO_DPF_reg 0 "DPF_regeneriert_nicht" 1 "DPF_regeneriert" ;
VAL_ 1631 MO_Heizstrom_EKAT 127 "Fehler" ;
VAL_ 1631 MO_Heizstrom_SCR 63 "Fehler" ;
VAL_ 1631 MO_Anzeige_Kaltleuchte 0 "Lampe_aus" 1 "Lampe_an" ;
VAL_ 1631 MO_P_Generator_ungefiltert_Anf 0 "nicht_angefordert" 1 "angefordert" ;
VAL_ 1631 TSK_Getriebeinfo 0 "Handschalter" 1 "AL_AQ_Getriebe" 2 "DL_DQ_Getriebe" 3 "CVT_Getriebe" ;
VAL_ 1631 MO_Energieinhalt_BMS 4094 "Init" 4095 "Fehler" ;
VAL_ 1631 TSK_Fahrzeugmasse_02 255 "Fehler" ;
VAL_ 1631 TSK_Steigung_02 0 "Init_oder_nicht_verbaut" 255 "Fehler" ;
VAL_ 1648 MO_ANC_Kennfeld_Anf 0 "Kennfeld_1" 1 "Uebergang_Kennfeld_2_nach_1" 2 "Uebergang_Kennfeld_1_nach_2" 3 "Kennfeld_2" ;
VAL_ 1648 MO_Bremslicht_Reku 0 "Aus" 1 "Ein" ;
VAL_ 1648 MO_StartStopp_PopUp 0 "Statuswechsel_ohne_Taster (Init)" 1 "StSt_per_Taster_deaktiviert" 2 "StSt_per_Taster_aktiviert" 3 "nicht verwendet" ;
VAL_ 1648 MO1_Sperr_Info_WFS 0 "nicht_gesperrt" 1 "gesperrt" ;
VAL_ 1648 MO1_Freigabe_Info_WFS 0 "ungueltig" 1 "gueltig" ;
VAL_ 1648 MO_EPCL 0 "EPCL_aus_kein_Text" 1 "EPCL_gelb_Stoerung" 2 "EPCL_gelb_Leistungsbeschraenkung" 3 "EPCL_rot_Fzg_sicher_abstellen" ;
VAL_ 1648 MO_Zylabsch_Texte_02 0 "ein_ZAS_generell_keine_ZAS_Anzeigen" 1 "ZAS_im_VMB" 2 "ZAS_im_ASB_1_Zyl_aktiv" 3 "ZAS_im_ASB_2_Zyl_aktiv" 4 "ZAS_im_ASB_3_Zyl_aktiv" 5 "ZAS_im_ASB_4_Zyl_aktiv" 6 "ZAS_im_ASB_5_Zyl_aktiv" 7 "ZAS_im_ASB_6_Zyl_aktiv" 8 "ZAS_im_ASB_8_Zyl_aktiv" 9 "ZAS_im_ASB_12_Zyl_aktiv" 13 "Uebergangsbetrieb" 14 "keine_ZAS_Anzeige_ggf_Stopp_Schub_Betrieb" 15 "ZAS_Stoerungs_Anzeige" ;
VAL_ 1648 MO_Fahrzeugtyp 0 "Verbrenner_Fahrzeug" 1 "Hybrid" 2 "E_Fahrzeug" 3 "E_Fahrzeug_mit_Range_Extender" 4 "Brennstoffzellenfahrzeug" 5 "tbd" 6 "tbd" 7 "tbd" ;
VAL_ 1648 MO_Abstellzeit 254 "Init" 255 "reserviert" ;
VAL_ 1648 MO_Abstellzeit_Status 0 "Abstellzeit_nicht_berechnet" 1 "Abstellzeit_berechnet" 2 "Abstellzeit_Minimalwert" 3 "Abstellzeit_ungueltig" ;
VAL_ 1648 MO1_Freigabe_Verfallsinfo_WFS 0 "verfaellt_nicht" 1 "verfaellt" ;
VAL_ 1648 MO_Hybrid_StartStopp_LED 0 "LED_aus_und_Blinken_aus" 1 "LED_ein_und_Blinken_aus" 2 "LED_ein_und_Blinken_ein_50_percent" 3 "reserviert" ;
VAL_ 1648 MO_Fehler_Zylabsch 0 "kein_Fehler" 1 "Notlauf_Vollmotorbetrieb" 2 "Notlauf_mindestens_einem_abgesch_Zylinder" ;
VAL_ 1648 MO_Anzahl_Abgesch_Zyl 0 "Vollmotorbetrieb" 1 "1_Zylinder_abgeschaltet" 2 "2_Zylinder_abgeschaltet" 3 "3_Zylinder_abgeschaltet" 4 "4_Zylinder_abgeschaltet" 5 "5_Zylinder_abgeschaltet" 6 "6_Zylinder_abgeschaltet" 7 "8_Zylinder_abgeschaltet" ;
VAL_ 1648 MO_Zylabsch_Texte 0 "keine_Texte" 1 "Zylinderabschaltung_deaktivieren" 2 "Zylinderabschaltung_aktivieren" 3 "Zylinderabschaltung_unruhig" ;
VAL_ 1648 MO_Ethanol_BS_Texte 0 "kein_Text" 1 "E85_Warm_Up" 2 "FlexFuel_Warnung_Stufe_3" 3 "Warmfahrempfehlung_MQB__FlexFuel_Warnung_Stufe_1" 4 "FlexFuel_Warnung_Stufe_2" 5 "FlexFuel_Warnung_Stufe_4" 6 "E25_Warm_Up" ;
VAL_ 1648 MO_Drehzahl_Warnung 0 "keinen_Warnhinweis_anzeigen" 1 "Warnhinweis_anzeigen" ;
VAL_ 1648 MO_obere_Drehzahlgrenze 0 "Init" ;
VAL_ 289 MO_Fahrpedalrohwert_01 255 "Fehler" ;
VAL_ 289 MO_QBit_Fahrpedalwerte_01 0 "gueltiger_Wert" 1 "Ersatz_Init_oder_Fehlerwert" ;
VAL_ 289 MO_Fahrpedalgradient 255 "Fehler" ;
VAL_ 289 MO_Sig_Fahrpedalgradient 0 "Fahrpedalgradient positiv" 1 "Fahrpedalgradient negativ" ;
VAL_ 289 MO_rel_Saugrohrdruck 0 "Init_Ueberdruck" 63 "Fehler" ;
VAL_ 289 MO_rel_Saugrohrdruck_gem_err 0 "errechnet" 1 "gemessen" ;
VAL_ 289 MO_Moment_im_Leerlauf 0 "kein_Leergas" 1 "Leergas" ;
VAL_ 289 MO_Schubabschaltung 0 "keine_Schubabschaltung" 1 "Schubabschaltung_aktiv" ;
VAL_ 289 MO_StartStopp_StoppVorbereitung 0 "Motorstopp_nicht_in_Vorbereitung" 1 "Motorstopp_in_Vorbereitung" ;
VAL_ 289 MO_Entkopplung_Sollschlupf 125 "Notoeffnen_Anfahrelement" 126 "Init" ;
VAL_ 289 MO_temporaere_Fahrerabwesenheit 0 "nicht_erkannt" 1 "erkannt" ;
VAL_ 289 TSK_a_Soll_gradientenbegrenzt 127 "Init_oder_nicht_aktiv" ;
VAL_ 1654 StSt_Koord_Wiederstart_Anz_09 0 "keine_Anzeige" 1 "Ampel_Info" ;
VAL_ 1654 StSt_Koord_Wiederstart_Anz_10 0 "keine_Anzeige" 1 "Race_Mode" ;
VAL_ 1654 StSt_Koord_Wiederstart_Anz_11 0 "keine_Anzeige" 1 "Wiederstart_PEA" ;
VAL_ 1654 MO_Wiederstart_Anz_01 0 "keine_Anzeige" 1 "Motortemperatur" ;
VAL_ 1654 MO_Wiederstart_Anz_02 0 "keine_Anzeige" 1 "BKV_Unterdruck" ;
VAL_ 1654 MO_Wiederstart_Anz_03 0 "keine_Anzeige" 1 "SCR_System" ;
VAL_ 1654 MO_Wiederstart_Anz_Std 0 "keine_Anzeige" 1 "Standard_Wiederstartgrund" ;
VAL_ 1654 MO_Stoppverbot_Anz_01 0 "keine_Anzeige" 1 "Abgasanlage" ;
VAL_ 1654 MO_Stoppverbot_Anz_02 0 "keine_Anzeige" 1 "Motortemperatur_Min" ;
VAL_ 1654 MO_Stoppverbot_Anz_03 0 "keine_Anzeige" 1 "Motortemperatur_Max" ;
VAL_ 1654 MO_Stoppverbot_Anz_04 0 "keine_Anzeige" 1 "Umgebungsluftdichte" ;
VAL_ 1654 MO_Stoppverbot_Anz_05 0 "keine_Anzeige" 1 "Bremsunterdruck" ;
VAL_ 1654 MO_Stoppverbot_Anz_06 0 "keine_Anzeige" 1 "Adaptionen" ;
VAL_ 1654 MO_Stoppverbot_Anz_07 0 "keine_Anzeige" 1 "Gangsensor" ;
VAL_ 1654 MO_Stoppverbot_Anz_08 0 "keine_Anzeige" 1 "Diagnose_Tankentlueftung" ;
VAL_ 1654 MO_Stoppverbot_Anz_09 0 "keine_Anzeige" 1 "FlexFuel_SCR_CNG" ;
VAL_ 1654 MO_Stoppverbot_Anz_10 0 "keine_Anzeige" 1 "OPF_DPF_Regeneration" ;
VAL_ 1654 MO_Stoppverbot_Anz_11 0 "keine_Anzeige" 1 "sporadische_Stoppverhinderung" ;
VAL_ 1654 MO_Stoppverbot_Anz_Std 0 "keine_Anzeige" 1 "Standard_Stoppvetogrund" ;
VAL_ 1654 StSt_Koord_Stoppverbot_Anz_20 0 "Ampel_verh_MotStopp_nicht" 1 "Ampel_verh_Motorstopp" ;
VAL_ 1654 StSt_Koord_Stoppverbot_Anz_21 0 "Race_Mode_verh_MotStopp_nicht" 1 "Race_Mode_verh_Motorstopp" ;
VAL_ 1654 StSt_Koord_Wiederstart_Anz_Std 0 "keine_Anzeige" 1 "Standard_Wiederstartgrund" ;
VAL_ 1654 StSt_Koord_Status_Bremspedalkzpt 0 "Bremspedalstart_moeglich" 1 "kein_Bremspedalstart_moeglich" ;
VAL_ 1654 StSt_Koord_Wiederstart_Anz_01 0 "keine_Anzeige" 1 "Kupplung_Bremse" ;
VAL_ 1654 StSt_Koord_Wiederstart_Anz_02 0 "keine_Anzeige" 1 "Fahrpedal" ;
VAL_ 1654 StSt_Koord_Wiederstart_Anz_03 0 "keine_Anzeige" 1 "Taster" ;
VAL_ 1654 StSt_Koord_Wiederstart_Anz_04 0 "keine_Anzeige" 1 "Schalten_nach_R" ;
VAL_ 1654 StSt_Koord_Wiederstart_Anz_05 0 "keine_Anzeige" 1 "Anrollen" ;
VAL_ 1654 StSt_Koord_Wiederstart_Anz_06 0 "keine_Anzeige" 1 "Notstart" ;
VAL_ 1654 StSt_Koord_Wiederstart_Anz_07 0 "keine_Anzeige" 1 "Lenkrad" ;
VAL_ 1654 StSt_Koord_Wiederstart_Anz_08 0 "keine_Anzeige" 1 "Offroad_Sport_und_ESP_Taster" ;
VAL_ 1654 StSt_Koord_Stoppverbot_Anz_01 0 "keine_Anzeige" 1 "Fahrzeugneigung" ;
VAL_ 1654 StSt_Koord_Stoppverbot_Anz_02 0 "keine_Anzeige" 1 "Wiederholstopp_Sperre" ;
VAL_ 1654 StSt_Koord_Stoppverbot_Anz_03 0 "keine_Anzeige" 1 "Rangiererkennung_MQ_DQ" ;
VAL_ 1654 StSt_Koord_Stoppverbot_Anz_04 0 "keine_Anzeige" 1 "Spielschutz" ;
VAL_ 1654 StSt_Koord_Stoppverbot_Anz_05 0 "keine_Anzeige" 1 "Taster_StSt_ausgeschaltet" ;
VAL_ 1654 StSt_Koord_Stoppverbot_Anz_06 0 "keine_Anzeige" 1 "Motorhaube" ;
VAL_ 1654 StSt_Koord_Stoppverbot_Anz_07 0 "keine_Anzeige" 1 "Fahrergurt" ;
VAL_ 1654 StSt_Koord_Stoppverbot_Anz_08 0 "keine_Anzeige" 1 "Fahrertuer" ;
VAL_ 1654 StSt_Koord_Stoppverbot_Anz_09 0 "keine_Anzeige" 1 "Fahrpedal" ;
VAL_ 1654 StSt_Koord_Stoppverbot_Anz_10 0 "keine_Anzeige" 1 "Lenkwinkel_Lenkwinkelgeschwindigkeit" ;
VAL_ 1654 StSt_Koord_Stoppverbot_Anz_11 0 "keine_Anzeige" 1 "Anhaenger" ;
VAL_ 1654 StSt_Koord_Stoppverbot_Anz_12 0 "keine_Anzeige" 1 "Wegfahrsperre_aktiv" ;
VAL_ 1654 StSt_Koord_Stoppverbot_Anz_13 0 "keine_Anzeige" 1 "dauerhafte_Fahrerabwesenheit" ;
VAL_ 1654 StSt_Koord_Stoppverbot_Anz_14 0 "keine_Anzeige" 1 "temporaere_Fahrerabwesenheit" ;
VAL_ 1654 StSt_Koord_Stoppverbot_Anz_15 0 "keine_Anzeige" 1 "Offroad_Sport_und_ESP_Taster" ;
VAL_ 1654 StSt_Koord_Stoppverbot_Anz_16 0 "keine_Anzeige" 1 "Neutralgang" ;
VAL_ 1654 StSt_Koord_Stoppverbot_Anz_17 0 "Fahrerhandl_verh_MotStopp_nicht" 1 "fehl_Fahrerhandl_verh_Motorstopp" ;
VAL_ 1654 StSt_Koord_Stoppverbot_Anz_Std 0 "keine_Anzeige" 1 "Standard_Stoppvetogrund" ;
VAL_ 1654 StSt_Koord_Stoppverbot_Anz_18 0 "PSD_verh_MotStopp_nicht" 1 "PSD_verh_Motorstopp" ;
VAL_ 1654 StSt_Koord_Stoppverbot_Anz_19 0 "Kurzstopp_verh_MotStopp_nicht" 1 "Kurzstopp_verh_Motorstopp" ;
VAL_ 1654 MO_StaGluehk 15 "Fehler" ;
